VERSION "HNNBNNNYNNNNNNNNNNNNNNNNNNNNNNNNNNNNNNNNNN/4/%%%/4/'%**4NNN///"

NS_ :

BS_:

BU_: AFS_B8 Airbag_B8 Daempfer_B8 Gateway_B8 Getriebe_AL6000 Getriebe_DL5001 Getriebe_VL3002 LWR_B8 Motor_EDC17_003 Motor_EDC17_004 Motor_MED17_B8 Motor_MED9_B8 Motor_SIMOS8_B8 Motor_Slave_B8 Getriebe_AL1000 Motor_MED17_SIMOS8 Motor_EDC17 Gateway_Routing_PAG Gateway_VW EPB_D4 Motor_EDC17_D4 Motor_MED17_003 Hybrid_MSG Hybrid_DQ200 Motor_ME17_BY Motor_MED17_SIMOS8_D4 Motor_EDC17_B8 Getriebe_AL551_951_D4_C7 Getriebe_AL551_Hybrid_D4_C7 Getriebe_DL501_C7 Getriebe_VL381_C7 Motor_MED17_SIMOS8_D4_Hybrid SCU_D4 Gateway_D4C7 Motor_MED17_Q5_Hybrid Fahrwerk STH_D4 Airbag_D4 Gateway_PAG_002 Gateway_VW_T003 Gateway_D4 LEH_Hybrid SCR_C7 BMS_Hybrid Gateway_App_PAG Getriebe_AL1004 Motor_MED17_006 Getriebe_AL5000

BO_ 906 GW_Fwk_01_Ant_PAG: 8 Gateway_Routing_PAG
 SG_ KL_T_PASM_1 : 5|1@1+ (1,0) [0|1] "" Vector__XXX
 SG_ KL_T_PASM_2 : 6|1@1+ (1,0) [0|1] "" Vector__XXX
 SG_ ESP_Gierrate_Offset : 8|8@1+ (0.1,-12.6) [-12.6|12.7] "Unit_DegreOfArcPerSecon" Vector__XXX
 SG_ KL_AussenTemp_WK : 16|8@1+ (0.5,-50) [-50|76] "Unit_DegreCelsi" Vector__XXX
 SG_ GE_Getriebestatus : 24|4@1+ (1,0) [0|15] "" Vector__XXX
 SG_ FAS_Status_Anzeige : 28|3@1+ (1,0) [0|7] "" Vector__XXX
 SG_ KL_Magnetventil : 32|1@1+ (1,0) [0|1] "" Vector__XXX
 SG_ LS_Tip_Hoch : 33|1@1+ (1,0) [0|1] "" Vector__XXX
 SG_ LS_Tip_Runter : 34|1@1+ (1,0) [0|1] "" Vector__XXX
 SG_ KL_T_PSM_off : 35|1@1+ (1,0) [0|1] ""  Getriebe_AL1000
 SG_ TV_Eingriff : 36|1@1+ (1,0) [0|1] "" Vector__XXX
 SG_ FSM_Status : 37|1@1+ (1,0) [0|1] "" Vector__XXX
 SG_ KL_Niv_up : 38|1@1+ (1,0) [0|1] "" Vector__XXX
 SG_ KL_Niv_down : 39|1@1+ (1,0) [0|1] "" Vector__XXX
 SG_ ESP_Rollenmodus : 40|1@1+ (1,0) [0|1] ""  Getriebe_AL1000,Motor_MED17_SIMOS8
 SG_ KL_T_Abgasklappe : 41|1@1+ (1,0) [0|1] ""  Motor_EDC17,Motor_MED17_SIMOS8
 SG_ KL_T_HDC : 42|1@1+ (1,0) [0|1] "" Vector__XXX
 SG_ KL_T_PASM_3 : 45|1@1+ (1,0) [0|1] "" Vector__XXX
 SG_ Wischer_vorne_Schnell : 46|1@1+ (1,0) [0|1] "" Vector__XXX
 SG_ Wischer_vorne_Normal : 47|1@1+ (1,0) [0|1] "" Vector__XXX
 SG_ F_Getriebe_07_PAG_Fwk : 48|1@1+ (1,0) [0|1] "" Vector__XXX
 SG_ F_ESP_11_Ant : 49|1@1+ (1,0) [0|1] ""  Motor_MED17_SIMOS8
 SG_ F_Klima_03_Fwk_Ant : 50|1@1+ (1,0) [0|1] "" Vector__XXX
 SG_ F_Wischer_01_Fwk : 51|1@1+ (1,0) [0|1] "" Vector__XXX
 SG_ F_TSK_03_Fwk : 52|1@1+ (1,0) [0|1] "" Vector__XXX
 SG_ LS_Fehler : 53|1@1+ (1,0) [0|1] "" Vector__XXX
 SG_ F_Klima_08_PAG_Fwk : 54|1@1+ (1,0) [0|1] ""  Getriebe_AL1000,Motor_EDC17,Motor_MED17_SIMOS8
 SG_ F_ESP_13_Ant : 56|1@1+ (1,0) [0|1] "" Vector__XXX
 SG_ F_LS_01_Fwk : 57|1@1+ (1,0) [0|1] "" Vector__XXX

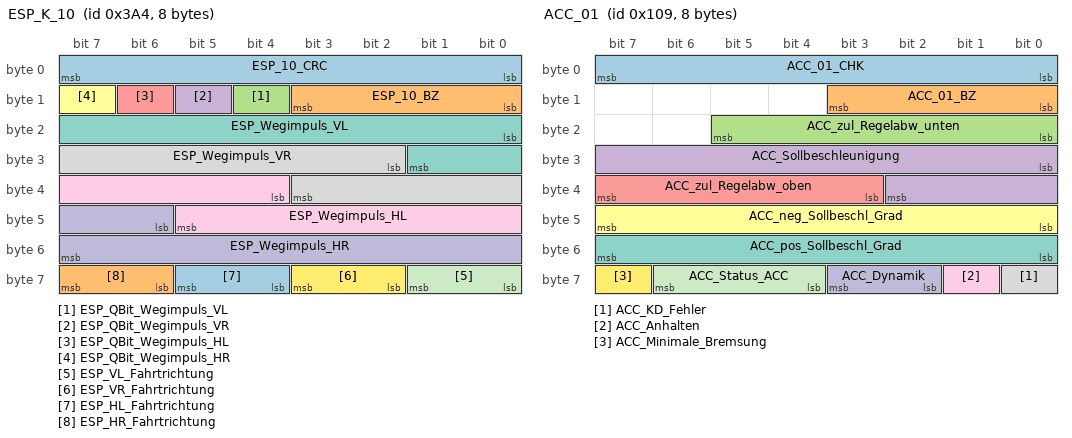
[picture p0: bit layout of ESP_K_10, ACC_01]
BO_ 932 ESP_K_10: 8 Gateway_VW
 SG_ ESP_10_CRC : 0|8@1+ (1,0) [0|255] ""  Motor_EDC17,Motor_MED17_SIMOS8
 SG_ ESP_10_BZ : 8|4@1+ (1,0) [0|15] ""  Motor_EDC17,Motor_MED17_SIMOS8
 SG_ ESP_QBit_Wegimpuls_VL : 12|1@1+ (1,0) [0|1] ""  Motor_EDC17,Motor_MED17_SIMOS8
 SG_ ESP_QBit_Wegimpuls_VR : 13|1@1+ (1,0) [0|1] ""  Motor_EDC17,Motor_MED17_SIMOS8
 SG_ ESP_QBit_Wegimpuls_HL : 14|1@1+ (1,0) [0|1] ""  Motor_EDC17,Motor_MED17_SIMOS8
 SG_ ESP_QBit_Wegimpuls_HR : 15|1@1+ (1,0) [0|1] ""  Motor_EDC17,Motor_MED17_SIMOS8
 SG_ ESP_Wegimpuls_VL : 16|10@1+ (1,0) [0|1000] ""  Motor_EDC17,Motor_MED17_SIMOS8
 SG_ ESP_Wegimpuls_VR : 26|10@1+ (1,0) [0|1000] ""  Motor_EDC17,Motor_MED17_SIMOS8
 SG_ ESP_Wegimpuls_HL : 36|10@1+ (1,0) [0|1000] ""  Motor_EDC17,Motor_MED17_SIMOS8
 SG_ ESP_Wegimpuls_HR : 46|10@1+ (1,0) [0|1000] ""  Motor_EDC17,Motor_MED17_SIMOS8
 SG_ ESP_VL_Fahrtrichtung : 56|2@1+ (1,0) [0|3] "" Vector__XXX
 SG_ ESP_VR_Fahrtrichtung : 58|2@1+ (1,0) [0|3] "" Vector__XXX
 SG_ ESP_HL_Fahrtrichtung : 60|2@1+ (1,0) [0|3] "" Vector__XXX
 SG_ ESP_HR_Fahrtrichtung : 62|2@1+ (1,0) [0|3] "" Vector__XXX

BO_ 1424 Kessy_02: 8 Gateway_B8
 SG_ KY_Funkschl_Nr : 0|4@1+ (1,0) [0|15] "" Vector__XXX
 SG_ KY_ID_Geb_autorisiert : 4|1@1+ (1,0) [0|1] "" Vector__XXX
 SG_ KY_ID_Geb_steckt : 5|1@1+ (1,0) [0|1] "" Vector__XXX
 SG_ KY_FFB_Frequenz : 6|2@1+ (1,0) [0|3] "" Vector__XXX
 SG_ KY_HF_Aktiv : 8|1@1+ (1,0) [0|1] "" Vector__XXX
 SG_ KY_LF_Aktiv : 9|1@1+ (1,0) [0|1] "" Vector__XXX
 SG_ KY_ELV_verr : 10|1@1+ (1,0) [0|1] ""  EPB_D4
 SG_ KY_ELV_entr : 11|1@1+ (1,0) [0|1] ""  EPB_D4
 SG_ KY_ELV_enable_Anforderung : 12|1@1+ (1,0) [0|1] "" Vector__XXX
 SG_ KY_Valet_Parking : 14|1@1+ (1,0) [0|1] "" Vector__XXX
 SG_ KY_Keyless_Verbau : 15|1@1+ (1,0) [0|1] "" Vector__XXX
 SG_ KY_FBS_Fahrer_Hinweise : 16|3@1+ (1,0) [0|7] "" Vector__XXX
 SG_ FBS_Warn_Lenkung_def : 19|1@1+ (1,0) [0|1] "" Vector__XXX
 SG_ FBS_Warn_LenkVerriegelung_def : 20|1@1+ (1,0) [0|1] "" Vector__XXX
 SG_ FBS_Warn_Schluessel_Batt : 21|1@1+ (1,0) [0|1] "" Vector__XXX
 SG_ FBS_Prio_Warn_04 : 22|1@1+ (1,0) [0|1] "" Vector__XXX
 SG_ FBS_Prio_Warn_05 : 23|1@1+ (1,0) [0|1] "" Vector__XXX
 SG_ KY_KYL_Fahrer_Hinweise : 24|3@1+ (1,0) [0|7] "" Vector__XXX
 SG_ KYL_Warn_kein_Schuessel : 27|1@1+ (1,0) [0|1] "" Vector__XXX
 SG_ KYL_Warn_Kessy_defekt : 28|1@1+ (1,0) [0|1] "" Vector__XXX
 SG_ KY_KYL_Prio_Warn_03 : 29|1@1+ (1,0) [0|1] "" Vector__XXX
 SG_ KY_KYL_Prio_Warn_04 : 30|1@1+ (1,0) [0|1] "" Vector__XXX
 SG_ KY_KYL_Prio_Warn_05 : 31|1@1+ (1,0) [0|1] "" Vector__XXX
 SG_ KY_Schluessel_Soll : 32|4@1+ (1,0) [0|15] "" Vector__XXX
 SG_ KY_Schluessel_Ist : 36|4@1+ (1,0) [0|15] "" Vector__XXX
 SG_ KY_WFS_Safe : 40|1@1+ (1,0) [0|1] "" Vector__XXX
 SG_ KY_WFS_LZ : 41|2@1+ (1,0) [0|3] "" Vector__XXX
 SG_ KY_StartStopp_Info : 43|2@1+ (1,0) [0|3] ""  Motor_EDC17_D4,Motor_MED17_003
 SG_ FBS_KD_Fehler : 47|1@1+ (1,0) [0|1] "" Vector__XXX

BO_ 265 ACC_01: 8 Gateway_B8
 SG_ ACC_01_CHK : 0|8@1+ (1,0) [0|255] ""  Daempfer_B8,Motor_EDC17_003,Motor_EDC17_004,Motor_MED17_B8,Motor_MED9_B8,Motor_SIMOS8_B8
 SG_ ACC_01_BZ : 8|4@1+ (1,0) [0|15] ""  Daempfer_B8,Motor_EDC17_003,Motor_EDC17_004,Motor_MED17_B8,Motor_MED9_B8,Motor_SIMOS8_B8
 SG_ ACC_zul_Regelabw_unten : 16|6@1+ (0.024,0) [0|1.512] "m/s2"  Motor_EDC17_003,Motor_EDC17_004,Motor_MED17_B8,Motor_MED9_B8,Motor_SIMOS8_B8
 SG_ ACC_Sollbeschleunigung : 24|11@1+ (0.005,-7.22) [-7.22|3.01] "m/s2"  Daempfer_B8,Motor_EDC17_003,Motor_EDC17_004,Motor_MED17_B8,Motor_MED9_B8,Motor_SIMOS8_B8
 SG_ ACC_zul_Regelabw_oben : 35|5@1+ (0.0625,0) [0|1.9375] "m/s2"  Motor_EDC17_003,Motor_EDC17_004,Motor_MED17_B8,Motor_MED9_B8,Motor_SIMOS8_B8
 SG_ ACC_neg_Sollbeschl_Grad : 40|8@1+ (0.05,0) [0|12.7] "m/s³"  Motor_EDC17_003,Motor_EDC17_004,Motor_MED17_B8,Motor_MED9_B8,Motor_SIMOS8_B8
 SG_ ACC_pos_Sollbeschl_Grad : 48|8@1+ (0.05,0) [0|12.7] "m/s³"  Motor_EDC17_003,Motor_EDC17_004,Motor_MED17_B8,Motor_MED9_B8,Motor_SIMOS8_B8
 SG_ ACC_KD_Fehler : 56|1@1+ (1,0) [0|1] "" Vector__XXX
 SG_ ACC_Anhalten : 57|1@1+ (1,0) [0|1] ""  Motor_EDC17_003,Motor_EDC17_004,Motor_MED17_B8,Motor_MED9_B8,Motor_SIMOS8_B8
 SG_ ACC_Dynamik : 58|2@1+ (1,0) [0|3] ""  Motor_EDC17_003,Motor_EDC17_004,Motor_MED17_B8,Motor_MED9_B8,Motor_SIMOS8_B8
 SG_ ACC_Status_ACC : 60|3@1+ (1,0) [0|7] ""  Daempfer_B8,Motor_EDC17_003,Motor_EDC17_004,Motor_MED17_B8,Motor_MED9_B8,Motor_SIMOS8_B8
 SG_ ACC_Minimale_Bremsung : 63|1@1+ (1,0) [0|1] ""  Motor_EDC17_003,Motor_EDC17_004,Motor_MED17_B8,Motor_MED9_B8,Motor_SIMOS8_B8

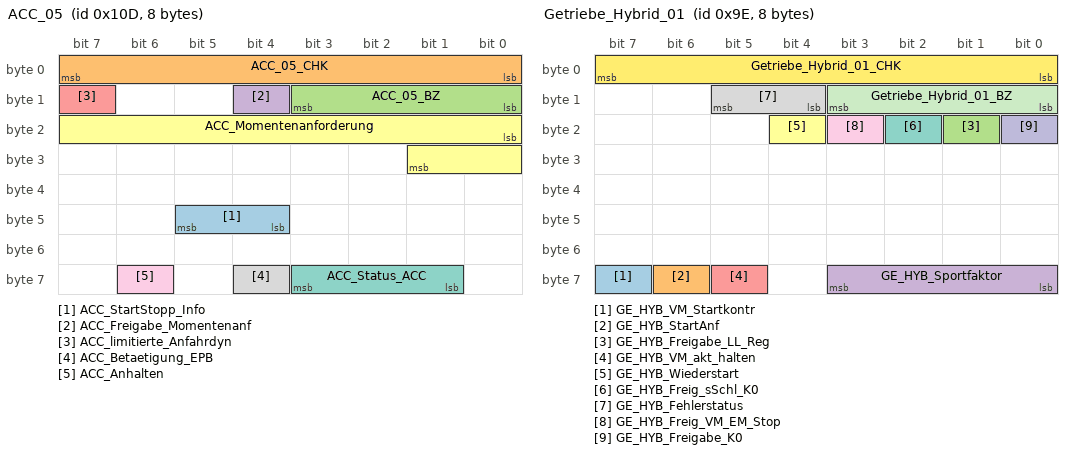
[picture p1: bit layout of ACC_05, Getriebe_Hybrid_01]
BO_ 269 ACC_05: 8 Gateway_B8
 SG_ ACC_StartStopp_Info : 44|2@1+ (1,0) [0|0] "" Vector__XXX
 SG_ ACC_05_CHK : 0|8@1+ (1,0) [0|255] ""  Daempfer_B8,Motor_EDC17_003,Motor_EDC17_004,Motor_MED17_B8,Motor_MED9_B8,Motor_SIMOS8_B8
 SG_ ACC_05_BZ : 8|4@1+ (1,0) [0|15] ""  Daempfer_B8,Motor_EDC17_003,Motor_EDC17_004,Motor_MED17_B8,Motor_MED9_B8,Motor_SIMOS8_B8
 SG_ ACC_Freigabe_Momentenanf : 12|1@1+ (1,0) [0|1] ""  Motor_EDC17_003,Motor_EDC17_004,Motor_MED17_B8,Motor_MED9_B8,Motor_SIMOS8_B8
 SG_ ACC_limitierte_Anfahrdyn : 15|1@1+ (1,0) [0|1] ""  Daempfer_B8,Motor_EDC17_003,Motor_EDC17_004,Motor_MED17_B8,Motor_MED9_B8,Motor_SIMOS8_B8
 SG_ ACC_Momentenanforderung : 16|10@1+ (1,0) [0|1021] ""  Motor_EDC17_003,Motor_EDC17_004,Motor_MED17_B8,Motor_MED9_B8,Motor_SIMOS8_B8
 SG_ ACC_Status_ACC : 57|3@1+ (1,0) [0|7] ""  Motor_EDC17_003,Motor_EDC17_004,Motor_MED17_B8,Motor_MED9_B8,Motor_SIMOS8_B8
 SG_ ACC_Betaetigung_EPB : 60|1@1+ (1,0) [0|1] ""  Motor_EDC17_003,Motor_EDC17_004,Motor_MED17_B8,Motor_MED9_B8,Motor_SIMOS8_B8
 SG_ ACC_Anhalten : 62|1@1+ (1,0) [0|1] ""  Motor_EDC17_003,Motor_EDC17_004,Motor_MED17_B8,Motor_MED9_B8,Motor_SIMOS8_B8

BO_ 158 Getriebe_Hybrid_01: 8 Hybrid_DQ200
 SG_ GE_HYB_VM_Startkontr : 63|1@1+ (1,0) [0|1] ""  Hybrid_MSG
 SG_ GE_HYB_StartAnf : 62|1@1+ (1,0) [0|1] ""  Hybrid_MSG
 SG_ GE_HYB_Freigabe_LL_Reg : 17|1@1+ (1,0) [0|1] ""  Hybrid_MSG
 SG_ GE_HYB_Sportfaktor : 56|4@1+ (1,0) [0|15] ""  Hybrid_MSG
 SG_ GE_HYB_VM_akt_halten : 61|1@1+ (1,0) [0|1] ""  Hybrid_MSG
 SG_ GE_HYB_Wiederstart : 20|1@1+ (1,0) [0|1] ""  Hybrid_MSG
 SG_ GE_HYB_Freig_sSchl_K0 : 18|1@1+ (1,0) [0|1] ""  Hybrid_MSG
 SG_ GE_HYB_Fehlerstatus : 12|2@1+ (1,0) [0|3] ""  Hybrid_MSG
 SG_ GE_HYB_Freig_VM_EM_Stop : 19|1@1+ (1,0) [0|1] ""  Hybrid_MSG
 SG_ GE_HYB_Freigabe_K0 : 16|1@1+ (1,0) [0|1] ""  Hybrid_MSG
 SG_ Getriebe_Hybrid_01_BZ : 8|4@1+ (1,0) [0|15] ""  Hybrid_MSG
 SG_ Getriebe_Hybrid_01_CHK : 0|8@1+ (1,0) [0|255] ""  Hybrid_MSG

BO_ 255 NOX2: 8 Vector__XXX
 SG_ NOx_Fehlerstatus_Bit7_1 : 63|1@1+ (1,0) [0|1] "" Vector__XXX
 SG_ NOx_Fehlerstatus_Bit6_1 : 62|1@1+ (1,0) [0|1] "" Vector__XXX
 SG_ NOx_Fehlerstatus_Bit5_1 : 61|1@1+ (1,0) [0|1] "" Vector__XXX
 SG_ NOx_Fehlerstatus_Bit4_1 : 60|1@1+ (1,0) [0|1] "" Vector__XXX
 SG_ NOx_Fehlerstatus_Bit3_1 : 59|1@1+ (1,0) [0|1] "" Vector__XXX
 SG_ NOx_Fehlerstatus_Bit2_1 : 58|1@1+ (1,0) [0|1] "" Vector__XXX
 SG_ NOx_Fehlerstatus_Bit1_1 : 57|1@1+ (1,0) [0|1] "" Vector__XXX
 SG_ NOx_Fehlerstatus_Bit0_1 : 56|1@1+ (1,0) [0|1] "" Vector__XXX
 SG_ NOx_Ubat_1 : 56|8@1+ (160,0) [0|40800] "mV" Vector__XXX
 SG_ NOx_MuxInfo_Korrekturfakt_OBD_1 : 56|8@1+ (1,0) [0|255] "" Vector__XXX
 SG_ NOx_MultiplexCode_Daten_1 : 55|1@1+ (1,0) [0|1] "" Vector__XXX
 SG_ NOx_MultiplexCode_OBD_1 : 53|2@1+ (1,0) [0|1] "" Vector__XXX
 SG_ NOx_Qbit_NOx_1 : 52|1@1+ (1,0) [0|1] "" Vector__XXX
 SG_ NOx_QBit_Rezp_Lambda_1 : 51|1@1+ (1,0) [0|1] "" Vector__XXX
 SG_ NOx_QBit_Lamb_U_1 : 50|1@1+ (1,0) [0|1] "" Vector__XXX
 SG_ NOx_QBit_Heizer_1 : 49|1@1+ (1,0) [0|1] "" Vector__XXX
 SG_ NOx_TaupunktEmpfang_1 : 48|1@1+ (1,0) [0|1] "" Vector__XXX
 SG_ NOx_MuxInfo_SensorStatus_1 : 48|8@1+ (1,0) [0|255] "" Vector__XXX
 SG_ NOx_MuxInfo_Lamb_U_4 : 40|8@1+ (1,0) [0|255] "" Vector__XXX
 SG_ NOx_MuxInfo_Lamb_U_3 : 40|8@1- (1,0) [-127|127] "" Vector__XXX
 SG_ NOx_MuxInfo_Lamb_U_2 : 32|8@1- (1,0) [-127|127] "" Vector__XXX
 SG_ NOx_MuxInfo_Lamb_U_1 : 32|16@1- (1,0) [-32768|32767] "mV" Vector__XXX
 SG_ NOx_MuxInfo_RezpLambda_Wert_3 : 16|16@1+ (1,0) [0|2000] "" Vector__XXX
 SG_ NOx_MuxInfo_RezpLambda_Wert_2 : 16|16@1+ (1,0) [0|8000] "" Vector__XXX
 SG_ NOx_MuxInfo_RezpLambda_Wert_1 : 16|16@1- (0.001,0) [-32.768|32.767] "" Vector__XXX
 SG_ NOx_MuxInfo_NOx_Wert_3 : 0|16@1+ (1,0) [0|2000] "-" Vector__XXX
 SG_ NOx_MuxInfo_NOx_Wert_2 : 0|16@1+ (1,0) [0|2000] "-" Vector__XXX
 SG_ NOx_MuxInfo_NOx_Wert_1 : 0|16@1- (0.1,0) [-3276.8|3276.7] "ppm" Vector__XXX

BO_ 254 NOX1: 8 Vector__XXX
 SG_ NOx_Fehlerstatus_Bit7_1 : 63|1@1+ (1,0) [0|1] "" Vector__XXX
 SG_ NOx_Fehlerstatus_Bit6_1 : 62|1@1+ (1,0) [0|1] "" Vector__XXX
 SG_ NOx_Fehlerstatus_Bit5_1 : 61|1@1+ (1,0) [0|1] "" Vector__XXX
 SG_ NOx_Fehlerstatus_Bit4_1 : 60|1@1+ (1,0) [0|1] "" Vector__XXX
 SG_ NOx_Fehlerstatus_Bit3_1 : 59|1@1+ (1,0) [0|1] "" Vector__XXX
 SG_ NOx_Fehlerstatus_Bit2_1 : 58|1@1+ (1,0) [0|1] "" Vector__XXX
 SG_ NOx_Fehlerstatus_Bit1_1 : 57|1@1+ (1,0) [0|1] "" Vector__XXX
 SG_ NOx_Fehlerstatus_Bit0_1 : 56|1@1+ (1,0) [0|1] "" Vector__XXX
 SG_ NOx_Ubat_1 : 56|8@1+ (160,0) [0|40800] "mV" Vector__XXX
 SG_ NOx_MuxInfo_Korrekturfakt_OBD_1 : 56|8@1+ (1,0) [0|255] "" Vector__XXX
 SG_ NOx_MultiplexCode_Daten_1 : 55|1@1+ (1,0) [0|1] "" Vector__XXX
 SG_ NOx_MultiplexCode_OBD_1 : 53|2@1+ (1,0) [0|1] "" Vector__XXX
 SG_ NOx_Qbit_NOx_1 : 52|1@1+ (1,0) [0|1] "" Vector__XXX
 SG_ NOx_QBit_Rezp_Lambda_1 : 51|1@1+ (1,0) [0|1] "" Vector__XXX
 SG_ NOx_QBit_Lamb_U_1 : 50|1@1+ (1,0) [0|1] "" Vector__XXX
 SG_ NOx_QBit_Heizer_1 : 49|1@1+ (1,0) [0|1] "" Vector__XXX
 SG_ NOx_TaupunktEmpfang_1 : 48|1@1+ (1,0) [0|1] "" Vector__XXX
 SG_ NOx_MuxInfo_SensorStatus_1 : 48|8@1+ (1,0) [0|255] "" Vector__XXX
 SG_ NOx_MuxInfo_Lamb_U_4 : 40|8@1+ (1,0) [0|255] "" Vector__XXX
 SG_ NOx_MuxInfo_Lamb_U_3 : 40|8@1- (1,0) [-127|127] "" Vector__XXX
 SG_ NOx_MuxInfo_Lamb_U_2 : 32|8@1- (1,0) [-127|127] "" Vector__XXX
 SG_ NOx_MuxInfo_Lamb_U_1 : 32|16@1- (1,0) [-32768|32767] "mV" Vector__XXX
 SG_ NOx_MuxInfo_RezpLambda_Wert_3 : 16|16@1+ (1,0) [0|2000] "" Vector__XXX
 SG_ NOx_MuxInfo_RezpLambda_Wert_2 : 16|16@1+ (1,0) [0|8000] "" Vector__XXX
 SG_ NOx_MuxInfo_RezpLambda_Wert_1 : 16|16@1- (0.001,0) [-32.768|32.767] "" Vector__XXX
 SG_ NOx_MuxInfo_NOx_Wert_3 : 0|16@1+ (1,0) [0|2000] "-" Vector__XXX
 SG_ NOx_MuxInfo_NOx_Wert_2 : 0|16@1+ (1,0) [0|2000] "-" Vector__XXX
 SG_ NOx_MuxInfo_NOx_Wert_1 : 0|16@1- (0.1,0) [-3276.8|3276.7] "ppm" Vector__XXX

BO_ 64 Airbag_01: 8 Airbag_B8
 SG_ Airbag_01_CHK : 0|8@1+ (1,0) [0|255] ""  Gateway_B8,Motor_EDC17_003,Motor_EDC17_004,Motor_MED17_B8,Motor_MED9_B8,Motor_SIMOS8_B8
 SG_ Airbag_01_BZ : 8|4@1+ (1,0) [0|15] ""  Gateway_B8,Motor_EDC17_003,Motor_EDC17_004,Motor_MED17_B8,Motor_MED9_B8,Motor_SIMOS8_B8
 SG_ AB_Front_Crash : 16|1@1+ (1,0) [0|1] ""  Gateway_B8
 SG_ AB_Heck_Crash : 17|1@1+ (1,0) [0|1] ""  Gateway_B8
 SG_ AB_SF_Crash : 18|1@1+ (1,0) [0|1] ""  Gateway_B8
 SG_ AB_SB_Crash : 19|1@1+ (1,0) [0|1] ""  Gateway_B8
 SG_ AB_Rollover_Crash : 20|1@1+ (1,0) [0|1] ""  Gateway_B8
 SG_ AB_Crash_Int : 21|3@1+ (1,0) [0|7] ""  Gateway_B8,Motor_EDC17_003,Motor_EDC17_004,Motor_MED17_B8,Motor_MED9_B8,Motor_SIMOS8_B8
 SG_ AB_Lampe : 24|1@1+ (1,0) [0|1] ""  Gateway_B8
 SG_ AB_Deaktiviert : 25|1@1+ (1,0) [0|1] ""  Gateway_B8
 SG_ AB_VB_deaktiviert : 26|1@1+ (1,0) [0|1] ""  Gateway_B8
 SG_ AB_Systemfehler : 27|1@1+ (1,0) [0|1] ""  Gateway_B8
 SG_ AB_Diagnose : 28|1@1+ (1,0) [0|1] ""  Gateway_B8
 SG_ AB_Stellgliedtest : 29|1@1+ (1,0) [0|1] ""  Gateway_B8,Motor_EDC17_003,Motor_EDC17_004,Motor_MED17_B8,Motor_MED9_B8,Motor_SIMOS8_B8
 SG_ AB_Erh_Auf_VB : 30|2@1+ (1,0) [0|3] ""  Gateway_B8
 SG_ AB_Gurtwarn_VF : 32|1@1+ (1,0) [0|1] ""  Gateway_B8
 SG_ AB_Gurtwarn_VB : 33|1@1+ (1,0) [0|1] ""  Gateway_B8
 SG_ AB_Anzeige_Fussg : 34|2@1+ (1,0) [0|3] ""  Gateway_B8
 SG_ AB_Deaktivierung_HV : 42|3@1+ (1,0) [0|7] ""  Gateway_B8
 SG_ void_Byte_02 : 48|8@1+ (1,0) [0|255] ""  Gateway_B8
 SG_ void_Byte_03 : 56|7@1+ (1,0) [0|127] ""  Gateway_B8
 SG_ AB_KD_Fehler : 63|1@1+ (1,0) [0|1] ""  Gateway_B8

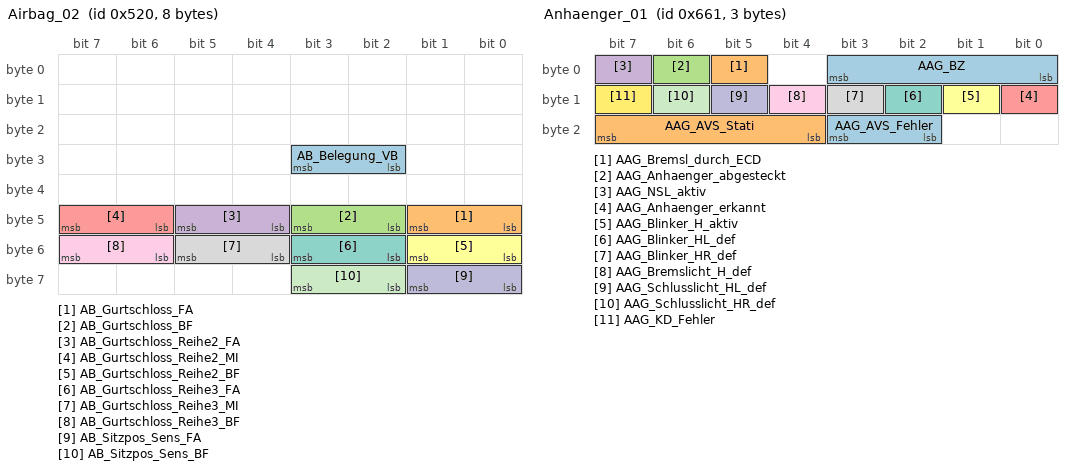
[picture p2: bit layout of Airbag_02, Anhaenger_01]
BO_ 1312 Airbag_02: 8 Airbag_B8
 SG_ AB_Belegung_VB : 26|2@1+ (1,0) [0|3] ""  Gateway_B8
 SG_ AB_Gurtschloss_FA : 40|2@1+ (1,0) [0|3] ""  Gateway_B8,Motor_EDC17_D4,Motor_MED17_003
 SG_ AB_Gurtschloss_BF : 42|2@1+ (1,0) [0|3] ""  Gateway_B8
 SG_ AB_Gurtschloss_Reihe2_FA : 44|2@1+ (1,0) [0|3] ""  Gateway_B8
 SG_ AB_Gurtschloss_Reihe2_MI : 46|2@1+ (1,0) [0|3] ""  Gateway_B8
 SG_ AB_Gurtschloss_Reihe2_BF : 48|2@1+ (1,0) [0|3] ""  Gateway_B8
 SG_ AB_Gurtschloss_Reihe3_FA : 50|2@1+ (1,0) [0|3] ""  Gateway_B8
 SG_ AB_Gurtschloss_Reihe3_MI : 52|2@1+ (1,0) [0|3] ""  Gateway_B8
 SG_ AB_Gurtschloss_Reihe3_BF : 54|2@1+ (1,0) [0|3] ""  Gateway_B8
 SG_ AB_Sitzpos_Sens_FA : 56|2@1+ (1,0) [0|3] ""  Gateway_B8
 SG_ AB_Sitzpos_Sens_BF : 58|2@1+ (1,0) [0|3] ""  Gateway_B8

BO_ 1633 Anhaenger_01: 3 Gateway_B8
 SG_ AAG_BZ : 0|4@1+ (1,0) [0|15] ""  Getriebe_AL6000,Motor_EDC17_003,Motor_EDC17_004,Motor_MED17_B8,Motor_MED9_B8,Motor_SIMOS8_B8
 SG_ AAG_Bremsl_durch_ECD : 5|1@1+ (1,0) [0|1] ""  Motor_EDC17_003,Motor_EDC17_004,Motor_MED17_B8,Motor_MED9_B8,Motor_SIMOS8_B8
 SG_ AAG_Anhaenger_abgesteckt : 6|1@1+ (1,0) [0|1] "" Vector__XXX
 SG_ AAG_NSL_aktiv : 7|1@1+ (1,0) [0|1] "" Vector__XXX
 SG_ AAG_Anhaenger_erkannt : 8|1@1+ (1,0) [0|1] ""  Getriebe_AL6000,Getriebe_DL5001,Getriebe_VL3002,Motor_EDC17_003,Motor_EDC17_004,Motor_MED17_B8,Motor_MED9_B8,Motor_SIMOS8_B8
 SG_ AAG_Blinker_H_aktiv : 9|1@1+ (1,0) [0|1] "" Vector__XXX
 SG_ AAG_Blinker_HL_def : 10|1@1+ (1,0) [0|1] "" Vector__XXX
 SG_ AAG_Blinker_HR_def : 11|1@1+ (1,0) [0|1] "" Vector__XXX
 SG_ AAG_Bremslicht_H_def : 12|1@1+ (1,0) [0|1] ""  Motor_EDC17_003,Motor_EDC17_004,Motor_MED17_B8,Motor_MED9_B8,Motor_SIMOS8_B8
 SG_ AAG_Schlusslicht_HL_def : 13|1@1+ (1,0) [0|1] "" Vector__XXX
 SG_ AAG_Schlusslicht_HR_def : 14|1@1+ (1,0) [0|1] "" Vector__XXX
 SG_ AAG_KD_Fehler : 15|1@1+ (1,0) [0|1] "" Vector__XXX
 SG_ AAG_AVS_Fehler : 18|2@1+ (1,0) [0|3] "" Vector__XXX
 SG_ AAG_AVS_Stati : 20|4@1+ (1,0) [0|15] "" Vector__XXX

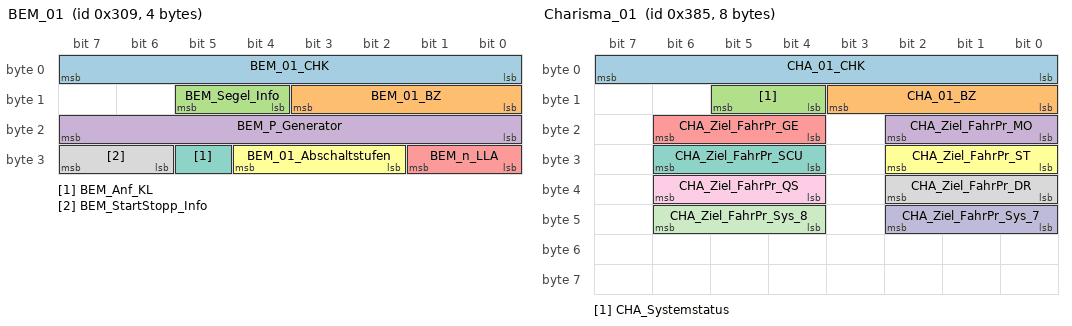
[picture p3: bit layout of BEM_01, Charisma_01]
BO_ 777 BEM_01: 4 Gateway_B8
 SG_ BEM_01_CHK : 0|8@1+ (1,0) [0|255] ""  Motor_EDC17_D4,Motor_ME17_BY,Motor_MED17_SIMOS8_D4
 SG_ BEM_01_BZ : 8|4@1+ (1,0) [0|15] ""  Motor_EDC17_D4,Motor_ME17_BY,Motor_MED17_SIMOS8_D4
 SG_ BEM_Segel_Info : 12|2@1+ (1,0) [0|3] "" Vector__XXX
 SG_ BEM_P_Generator : 16|8@1+ (50,0) [0|12700] "Unit_Watt"  Motor_EDC17_D4,Motor_ME17_BY,Motor_MED17_SIMOS8_D4
 SG_ BEM_n_LLA : 24|2@1+ (1,0) [0|3] ""  Motor_EDC17_D4,Motor_ME17_BY,Motor_MED17_SIMOS8_D4
 SG_ BEM_01_Abschaltstufen : 26|3@1+ (1,0) [0|7] "" Vector__XXX
 SG_ BEM_Anf_KL : 29|1@1+ (1,0) [0|1] ""  Motor_EDC17_D4,Motor_ME17_BY,Motor_MED17_SIMOS8_D4
 SG_ BEM_StartStopp_Info : 30|2@1+ (1,0) [0|3] ""  Motor_EDC17_D4,Motor_ME17_BY,Motor_MED17_SIMOS8_D4

BO_ 867 Blinkmodi_01: 4 Gateway_B8
 SG_ BM_ZV_auf : 0|1@1+ (1,0) [0|1] "" Vector__XXX
 SG_ BM_ZV_zu : 1|1@1+ (1,0) [0|1] "" Vector__XXX
 SG_ BM_DWA_ein : 2|1@1+ (1,0) [0|1] "" Vector__XXX
 SG_ BM_DWA_Alarm : 3|1@1+ (1,0) [0|1] "" Vector__XXX
 SG_ BM_Crash : 4|1@1+ (1,0) [0|1] "" Vector__XXX
 SG_ BM_Panik : 5|1@1+ (1,0) [0|1] "" Vector__XXX
 SG_ BM_Not_Bremsung : 6|1@1+ (1,0) [0|1] "" Vector__XXX
 SG_ BM_GDO : 7|1@1+ (1,0) [0|1] "" Vector__XXX
 SG_ BM_links : 8|1@1+ (1,0) [0|1] "" Vector__XXX
 SG_ BM_rechts : 9|1@1+ (1,0) [0|1] "" Vector__XXX
 SG_ BM_Warnblinken : 10|1@1+ (1,0) [0|1] "" Vector__XXX
 SG_ BM_Autobahn : 11|1@1+ (1,0) [0|1] ""  AFS_B8
 SG_ BM_Taxi_Notalarm : 12|1@1+ (1,0) [0|1] "" Vector__XXX
 SG_ BM_Telematik : 13|1@1+ (1,0) [0|1] "" Vector__XXX
 SG_ BM_WBT_Beleuchtung : 15|1@1+ (1,0) [0|1] "" Vector__XXX
 SG_ Blinken_li_Fzg_Takt : 16|1@1+ (1,0) [0|1] "" Vector__XXX
 SG_ Blinken_re_Fzg_Takt : 17|1@1+ (1,0) [0|1] "" Vector__XXX
 SG_ Blinken_li_Kombi_Takt : 18|1@1+ (1,0) [0|1] "" Vector__XXX
 SG_ Blinken_re_Kombi_Takt : 19|1@1+ (1,0) [0|1] "" Vector__XXX
 SG_ Blinken_FWB_aktiv : 23|1@1+ (1,0) [0|1] "" Vector__XXX

BO_ 482 CCP_GE_CR0_01: 8 Gateway_B8
 SG_ CCP_GE_CRO_01_Data : 0|64@1+ (1,0) [0|1] ""  Getriebe_AL6000,Getriebe_DL5001,Getriebe_VL3002

BO_ 490 CCP_GE_DTO_01: 8 Getriebe_AL6000
 SG_ CCP_GE_DTO_01_Data : 0|64@1+ (1,0) [0|1] "" Vector__XXX

BO_ 480 CCP_MO_CRO_01: 8 Gateway_B8
 SG_ CCP_MO_CRO_01_Data : 0|64@1+ (1,0) [0|1] ""  Motor_EDC17_003,Motor_EDC17_004,Motor_MED17_B8,Motor_MED9_B8,Motor_SIMOS8_B8

BO_ 2616986624 CCP_MO_CRO_02: 8 Vector__XXX
 SG_ CCP_MO_CRO_02_Data : 0|64@1+ (1,0) [0|1] ""  Motor_EDC17_003,Motor_EDC17_004,Motor_MED17_B8,Motor_MED9_B8,Motor_SIMOS8_B8

BO_ 488 CCP_MO_DTO_01: 8 Motor_EDC17_003
 SG_ CCP_MO_DTO_01_Data : 0|64@1+ (1,0) [0|1] "" Vector__XXX

BO_ 2616986625 CCP_MO_DTO_02: 8 Motor_SIMOS8_B8
 SG_ CCP_MO_DTO_02_Data : 0|64@1+ (1,0) [0|1] "" Vector__XXX

BO_ 481 CCP_MOS_CRO_01: 8 Gateway_B8
 SG_ CCP_MOS_CRO_01_Data : 0|64@1+ (1,0) [0|1] ""  Motor_Slave_B8

BO_ 2616986629 CCP_MOS_CRO_02: 8 Vector__XXX
 SG_ CCP_MOS_CRO_02_Data : 0|64@1+ (1,0) [0|1] ""  Motor_Slave_B8

BO_ 489 CCP_MOS_DTO_01: 8 Motor_Slave_B8
 SG_ CCP_MOS_DTO_01_Data : 0|64@1+ (1,0) [0|1] "" Vector__XXX

BO_ 2616986630 CCP_MOS_DTO_02: 8 Motor_Slave_B8
 SG_ CCP_MOS_DTO_02_Data : 0|64@1+ (1,0) [0|1] "" Vector__XXX

BO_ 901 Charisma_01: 8 Gateway_B8
 SG_ CHA_01_CHK : 0|8@1+ (1,0) [0|255] ""  Daempfer_B8,Getriebe_AL6000,Getriebe_DL5001,Getriebe_VL3002,Motor_EDC17_003,Motor_EDC17_004,Motor_MED17_B8,Motor_MED9_B8,Motor_SIMOS8_B8
 SG_ CHA_01_BZ : 8|4@1+ (1,0) [0|15] "" Vector__XXX
 SG_ CHA_Systemstatus : 12|2@1+ (1,0) [0|3] ""  Daempfer_B8,Getriebe_AL6000,Getriebe_DL5001,Getriebe_VL3002,Motor_EDC17_003,Motor_EDC17_004,Motor_MED17_B8,Motor_MED9_B8,Motor_SIMOS8_B8
 SG_ CHA_Ziel_FahrPr_MO : 16|3@1+ (1,0) [0|7] ""  Motor_EDC17_003,Motor_EDC17_004,Motor_MED17_B8,Motor_MED9_B8,Motor_SIMOS8_B8
 SG_ CHA_Ziel_FahrPr_GE : 20|3@1+ (1,0) [0|7] ""  Getriebe_AL6000,Getriebe_DL5001,Getriebe_VL3002
 SG_ CHA_Ziel_FahrPr_ST : 24|3@1+ (1,0) [0|7] "" Vector__XXX
 SG_ CHA_Ziel_FahrPr_SCU : 28|3@1+ (1,0) [0|7] "" Vector__XXX
 SG_ CHA_Ziel_FahrPr_DR : 32|3@1+ (1,0) [0|7] ""  Daempfer_B8
 SG_ CHA_Ziel_FahrPr_QS : 36|3@1+ (1,0) [0|7] "" Vector__XXX
 SG_ CHA_Ziel_FahrPr_Sys_7 : 40|3@1+ (1,0) [0|7] "" Vector__XXX
 SG_ CHA_Ziel_FahrPr_Sys_8 : 44|3@1+ (1,0) [0|7] "" Vector__XXX

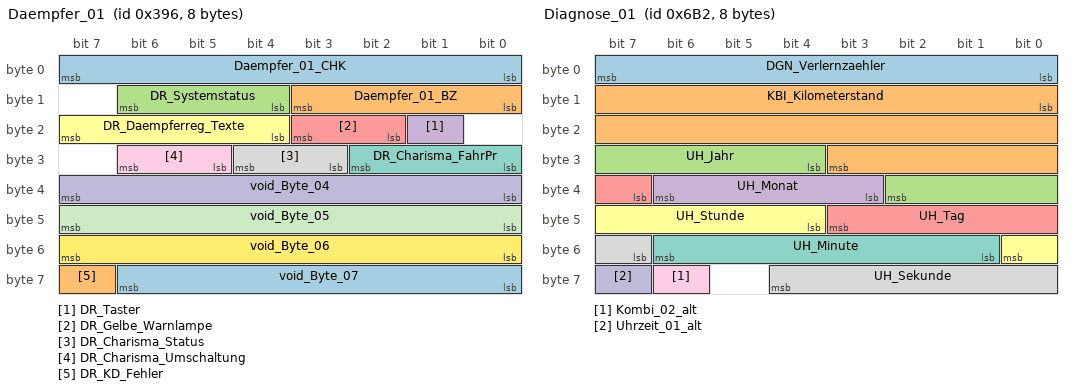
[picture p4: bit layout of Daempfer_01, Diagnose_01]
BO_ 918 Daempfer_01: 8 Daempfer_B8
 SG_ Daempfer_01_CHK : 0|8@1+ (1,0) [0|255] ""  Gateway_B8
 SG_ Daempfer_01_BZ : 8|4@1+ (1,0) [0|15] ""  Gateway_B8
 SG_ DR_Systemstatus : 12|3@1+ (1,0) [0|7] ""  Gateway_B8
 SG_ DR_Taster : 17|1@1+ (1,0) [0|1] ""  Gateway_B8
 SG_ DR_Gelbe_Warnlampe : 18|2@1+ (1,0) [0|3] ""  Gateway_B8
 SG_ DR_Daempferreg_Texte : 20|4@1+ (1,0) [0|15] ""  Gateway_B8
 SG_ DR_Charisma_FahrPr : 24|3@1+ (1,0) [0|7] ""  Gateway_B8
 SG_ DR_Charisma_Status : 27|2@1+ (1,0) [0|3] ""  Gateway_B8
 SG_ DR_Charisma_Umschaltung : 29|2@1+ (1,0) [0|3] ""  Gateway_B8
 SG_ void_Byte_04 : 32|8@1+ (1,0) [0|255] ""  Gateway_B8
 SG_ void_Byte_05 : 40|8@1+ (1,0) [0|255] ""  Gateway_B8
 SG_ void_Byte_06 : 48|8@1+ (1,0) [0|255] ""  Gateway_B8
 SG_ void_Byte_07 : 56|7@1+ (1,0) [0|127] ""  Gateway_B8
 SG_ DR_KD_Fehler : 63|1@1+ (1,0) [0|1] ""  Gateway_B8

BO_ 1714 Diagnose_01: 8 Gateway_B8
 SG_ DGN_Verlernzaehler : 0|8@1+ (1,0) [0|254] ""  AFS_B8,Airbag_B8,Daempfer_B8,LWR_B8
 SG_ KBI_Kilometerstand : 8|20@1+ (1,0) [0|1048573] "km"  AFS_B8,Airbag_B8,Daempfer_B8,Getriebe_AL6000,Getriebe_DL5001,Getriebe_VL3002,LWR_B8,Motor_EDC17_003,Motor_EDC17_004,Motor_MED17_B8,Motor_MED9_B8,Motor_SIMOS8_B8
 SG_ UH_Jahr : 28|7@1+ (1,2000) [2000|2127] ""  AFS_B8,Airbag_B8,Daempfer_B8,Getriebe_AL6000,Getriebe_DL5001,Getriebe_VL3002,LWR_B8,Motor_EDC17_003,Motor_EDC17_004,Motor_MED17_B8,Motor_MED9_B8,Motor_SIMOS8_B8
 SG_ UH_Monat : 35|4@1+ (1,0) [1|12] "month"  AFS_B8,Airbag_B8,Daempfer_B8,Getriebe_AL6000,Getriebe_DL5001,Getriebe_VL3002,LWR_B8,Motor_EDC17_003,Motor_EDC17_004,Motor_MED17_B8,Motor_MED9_B8,Motor_SIMOS8_B8
 SG_ UH_Tag : 39|5@1+ (1,0) [1|31] "d"  AFS_B8,Airbag_B8,Daempfer_B8,Getriebe_AL6000,Getriebe_DL5001,Getriebe_VL3002,LWR_B8,Motor_EDC17_003,Motor_EDC17_004,Motor_MED17_B8,Motor_MED9_B8,Motor_SIMOS8_B8
 SG_ UH_Stunde : 44|5@1+ (1,0) [0|23] "h"  AFS_B8,Airbag_B8,Daempfer_B8,Getriebe_AL6000,Getriebe_DL5001,Getriebe_VL3002,LWR_B8,Motor_EDC17_003,Motor_EDC17_004,Motor_MED17_B8,Motor_MED9_B8,Motor_SIMOS8_B8
 SG_ UH_Minute : 49|6@1+ (1,0) [0|59] "min"  AFS_B8,Airbag_B8,Daempfer_B8,Getriebe_AL6000,Getriebe_DL5001,Getriebe_VL3002,LWR_B8,Motor_EDC17_003,Motor_EDC17_004,Motor_MED17_B8,Motor_MED9_B8,Motor_SIMOS8_B8
 SG_ UH_Sekunde : 55|6@1+ (1,0) [0|59] "s"  AFS_B8,Airbag_B8,Daempfer_B8,Getriebe_AL6000,Getriebe_DL5001,Getriebe_VL3002,LWR_B8,Motor_EDC17_003,Motor_EDC17_004,Motor_MED17_B8,Motor_MED9_B8,Motor_SIMOS8_B8
 SG_ Kombi_02_alt : 62|1@1+ (1,0) [0|1] ""  AFS_B8,Airbag_B8,Getriebe_AL6000,Getriebe_DL5001,Getriebe_VL3002,LWR_B8,Motor_EDC17_003,Motor_EDC17_004,Motor_MED17_B8,Motor_MED9_B8,Motor_SIMOS8_B8
 SG_ Uhrzeit_01_alt : 63|1@1+ (1,0) [0|1] ""  AFS_B8,Airbag_B8,Getriebe_AL6000,Getriebe_DL5001,Getriebe_VL3002,LWR_B8,Motor_EDC17_003,Motor_EDC17_004,Motor_MED17_B8,Motor_MED9_B8,Motor_SIMOS8_B8

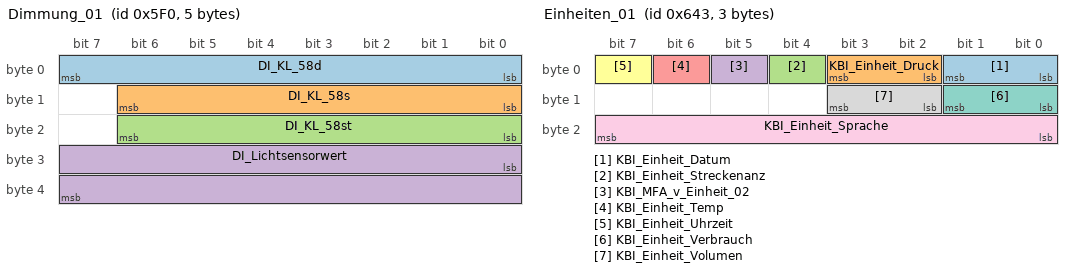
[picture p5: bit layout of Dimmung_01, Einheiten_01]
BO_ 1520 Dimmung_01: 5 Gateway_B8
 SG_ DI_KL_58d : 0|8@1+ (1,0) [0|253] ""  Airbag_B8
 SG_ DI_KL_58s : 8|7@1+ (1,0) [0|100] "%" Vector__XXX
 SG_ DI_KL_58st : 16|7@1+ (1,0) [0|100] "%" Vector__XXX
 SG_ DI_Lichtsensorwert : 24|16@1+ (1,0) [0|65535] "" Vector__XXX

BO_ 1603 Einheiten_01: 3 Gateway_B8
 SG_ KBI_Einheit_Datum : 0|2@1+ (1,0) [0|3] "" Vector__XXX
 SG_ KBI_Einheit_Druck : 2|2@1+ (1,0) [0|3] "" Vector__XXX
 SG_ KBI_Einheit_Streckenanz : 4|1@1+ (1,0) [0|1] ""  Motor_EDC17_B8
 SG_ KBI_MFA_v_Einheit_02 : 5|1@1+ (1,0) [0|1] "" Vector__XXX
 SG_ KBI_Einheit_Temp : 6|1@1+ (1,0) [0|1] "" Vector__XXX
 SG_ KBI_Einheit_Uhrzeit : 7|1@1+ (1,0) [0|1] "" Vector__XXX
 SG_ KBI_Einheit_Verbrauch : 8|2@1+ (1,0) [0|3] "" Vector__XXX
 SG_ KBI_Einheit_Volumen : 10|2@1+ (1,0) [0|3] "" Vector__XXX
 SG_ KBI_Einheit_Sprache : 16|8@1+ (1,0) [0|255] "" Vector__XXX

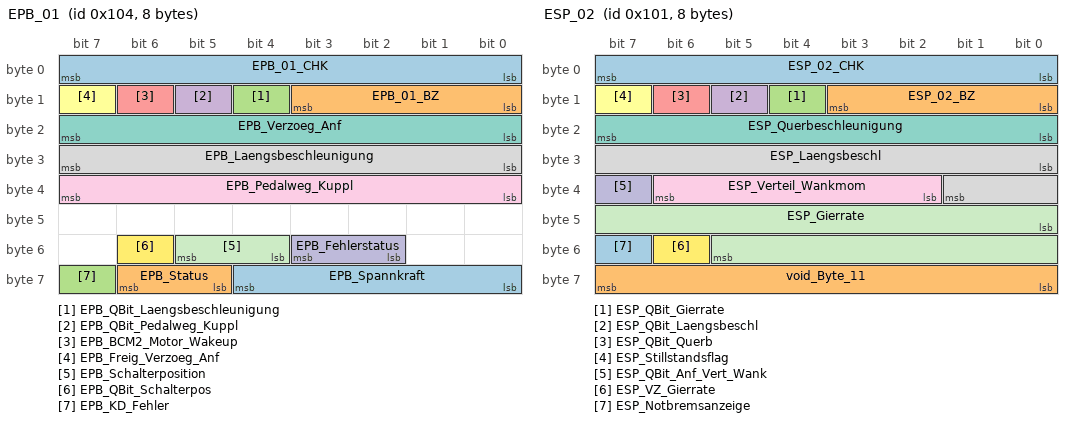
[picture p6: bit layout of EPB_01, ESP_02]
BO_ 260 EPB_01: 8 Gateway_B8
 SG_ EPB_01_CHK : 0|8@1+ (1,0) [0|255] ""  Daempfer_B8,Getriebe_AL6000,Getriebe_DL5001,Getriebe_VL3002,Motor_EDC17_003,Motor_EDC17_004,Motor_MED17_B8,Motor_MED9_B8,Motor_SIMOS8_B8
 SG_ EPB_01_BZ : 8|4@1+ (1,0) [0|15] ""  Daempfer_B8,Getriebe_AL6000,Getriebe_DL5001,Getriebe_VL3002,Motor_EDC17_003,Motor_EDC17_004,Motor_MED17_B8,Motor_MED9_B8,Motor_SIMOS8_B8
 SG_ EPB_QBit_Laengsbeschleunigung : 12|1@1+ (1,0) [0|1] ""  Getriebe_AL6000,Getriebe_DL5001,Getriebe_VL3002,Motor_EDC17_003,Motor_EDC17_004,Motor_MED17_B8,Motor_MED9_B8,Motor_SIMOS8_B8
 SG_ EPB_QBit_Pedalweg_Kuppl : 13|1@1+ (1,0) [0|1] ""  Motor_EDC17_003,Motor_EDC17_004,Motor_MED17_B8,Motor_MED9_B8,Motor_SIMOS8_B8
 SG_ EPB_BCM2_Motor_Wakeup : 14|1@1+ (1,0) [0|1] "" Vector__XXX
 SG_ EPB_Freig_Verzoeg_Anf : 15|1@1+ (1,0) [0|1] ""  Daempfer_B8,Getriebe_AL6000,Motor_EDC17_003,Motor_EDC17_004,Motor_MED17_B8,Motor_MED9_B8,Motor_SIMOS8_B8
 SG_ EPB_Verzoeg_Anf : 16|8@1+ (0.048,-7.968) [-7.968|4.224] "m/s2"  Daempfer_B8
 SG_ EPB_Laengsbeschleunigung : 24|8@1+ (1,-128) [-128|126] "%g"  Getriebe_AL6000,Getriebe_DL5001,Getriebe_VL3002,Motor_EDC17_003,Motor_EDC17_004,Motor_MED17_B8,Motor_MED9_B8,Motor_SIMOS8_B8
 SG_ EPB_Pedalweg_Kuppl : 32|8@1+ (0.4,0) [8|92] "%"  Motor_EDC17_003,Motor_EDC17_004,Motor_MED17_B8,Motor_MED9_B8,Motor_SIMOS8_B8
 SG_ EPB_Fehlerstatus : 50|2@1+ (1,0) [0|3] "" Vector__XXX
 SG_ EPB_Schalterposition : 52|2@1+ (1,0) [0|3] ""  Getriebe_AL6000,Motor_EDC17_003,Motor_EDC17_004,Motor_MED17_B8,Motor_MED9_B8,Motor_SIMOS8_B8
 SG_ EPB_QBit_Schalterpos : 54|1@1+ (1,0) [0|1] ""  Getriebe_AL6000,Motor_EDC17_003,Motor_EDC17_004,Motor_MED17_B8,Motor_MED9_B8,Motor_SIMOS8_B8
 SG_ EPB_Spannkraft : 56|5@1+ (1,0) [0|29] "kN"  Getriebe_AL6000
 SG_ EPB_Status : 61|2@1+ (1,0) [0|3] ""  Getriebe_AL6000,Motor_EDC17_003,Motor_EDC17_004,Motor_MED17_B8,Motor_MED9_B8,Motor_SIMOS8_B8
 SG_ EPB_KD_Fehler : 63|1@1+ (1,0) [0|1] "" Vector__XXX

BO_ 256 ESP_01: 8 Gateway_B8
 SG_ ESP_01_CHK : 0|8@1+ (1,0) [0|255] ""  Airbag_B8,Daempfer_B8,Getriebe_AL6000,Getriebe_DL5001,Getriebe_VL3002,Motor_EDC17_003,Motor_EDC17_004,Motor_MED17_B8,Motor_MED9_B8,Motor_SIMOS8_B8
 SG_ ESP_01_BZ : 8|4@1+ (1,0) [0|15] ""  Airbag_B8,Daempfer_B8,Getriebe_AL6000,Getriebe_DL5001,Getriebe_VL3002,Motor_EDC17_003,Motor_EDC17_004,Motor_MED17_B8,Motor_MED9_B8,Motor_SIMOS8_B8
 SG_ ASR_Moment_langsam : 12|10@1+ (1,0) [0|1021] ""  Airbag_B8,Getriebe_AL6000,Getriebe_DL5001,Motor_EDC17_003,Motor_EDC17_004,Motor_MED17_B8,Motor_MED9_B8,Motor_SIMOS8_B8
 SG_ ASR_MSR_Moment_schnell : 22|10@1+ (1,0) [0|1021] ""  Airbag_B8,Getriebe_AL6000,Getriebe_DL5001,Motor_EDC17_003,Motor_EDC17_004,Motor_MED17_B8,Motor_MED9_B8,Motor_SIMOS8_B8
 SG_ ESP_v_Signal : 32|16@1+ (0.01,0) [0|655.32] "km/h"  Airbag_B8,Daempfer_B8,Getriebe_AL6000,Getriebe_DL5001,Motor_EDC17_003,Motor_EDC17_004,Motor_MED17_B8,Motor_MED9_B8,Motor_SIMOS8_B8
 SG_ ASR_Tastung_passiv : 48|1@1+ (1,0) [0|1] ""  Airbag_B8,Getriebe_AL6000,Getriebe_DL5001,Getriebe_VL3002,Motor_EDC17_003,Motor_EDC17_004,Motor_MED17_B8,Motor_MED9_B8,Motor_SIMOS8_B8
 SG_ ESP_Tastung_passiv : 49|1@1+ (1,0) [0|1] ""  Airbag_B8,Getriebe_AL6000,Getriebe_DL5001,Getriebe_VL3002,Motor_EDC17_003,Motor_EDC17_004,Motor_MED17_B8,Motor_MED9_B8,Motor_SIMOS8_B8
 SG_ ESP_Systemstatus : 50|1@1+ (1,0) [0|1] ""  Airbag_B8,Motor_EDC17_003,Motor_EDC17_004,Motor_MED17_B8,Motor_MED9_B8,Motor_SIMOS8_B8
 SG_ ASR_Schalteingriff : 51|2@1+ (1,0) [0|3] ""  Airbag_B8,Getriebe_AL6000,Getriebe_DL5001,Getriebe_VL3002
 SG_ OBD_Schlechtweg : 53|1@1+ (1,0) [0|1] ""  Motor_EDC17_003,Motor_EDC17_004,Motor_MED17_B8,Motor_MED9_B8,Motor_SIMOS8_B8
 SG_ OBD_QBit_Schlechtweg : 54|1@1+ (1,0) [0|1] ""  Motor_EDC17_003,Motor_EDC17_004,Motor_MED17_B8,Motor_MED9_B8,Motor_SIMOS8_B8
 SG_ ESP_QBit_v_Signal : 55|1@1+ (1,0) [0|1] ""  Airbag_B8,Daempfer_B8,Getriebe_AL6000,Getriebe_DL5001,Motor_EDC17_003,Motor_EDC17_004,Motor_MED17_B8,Motor_MED9_B8,Motor_SIMOS8_B8
 SG_ ABS_Bremsung : 56|1@1+ (1,0) [0|1] ""  Airbag_B8,Daempfer_B8,Getriebe_AL6000,Getriebe_DL5001,Getriebe_VL3002,Motor_EDC17_003,Motor_EDC17_004,Motor_MED17_B8,Motor_MED9_B8,Motor_SIMOS8_B8
 SG_ ASR_Anf : 57|1@1+ (1,0) [0|1] ""  Airbag_B8,Getriebe_AL6000,Getriebe_DL5001,Getriebe_VL3002,Motor_EDC17_003,Motor_EDC17_004,Motor_MED17_B8,Motor_MED9_B8,Motor_SIMOS8_B8
 SG_ MSR_Anf : 58|1@1+ (1,0) [0|1] ""  Airbag_B8,Getriebe_VL3002,Motor_EDC17_003,Motor_EDC17_004,Motor_MED17_B8,Motor_MED9_B8,Motor_SIMOS8_B8
 SG_ EBV_Eingriff : 59|1@1+ (1,0) [0|1] ""  Airbag_B8,Daempfer_B8,Getriebe_AL6000,Getriebe_DL5001,Motor_EDC17_003,Motor_EDC17_004,Motor_MED17_B8,Motor_MED9_B8,Motor_SIMOS8_B8
 SG_ EDS_Eingriff : 60|1@1+ (1,0) [0|1] ""  Airbag_B8,Daempfer_B8,Getriebe_VL3002,Motor_EDC17_003,Motor_EDC17_004,Motor_MED17_B8,Motor_MED9_B8,Motor_SIMOS8_B8
 SG_ ESP_Eingriff : 61|1@1+ (1,0) [0|1] ""  Airbag_B8,Daempfer_B8,Getriebe_AL6000,Getriebe_DL5001,Getriebe_VL3002,Motor_EDC17_003,Motor_EDC17_004,Motor_MED17_B8,Motor_MED9_B8,Motor_SIMOS8_B8
 SG_ ESP_ASP : 62|1@1+ (1,0) [0|1] ""  Motor_EDC17_003,Motor_EDC17_004,Motor_MED17_B8,Motor_MED9_B8,Motor_SIMOS8_B8
 SG_ ESP_KD_Fehler : 63|1@1+ (1,0) [0|1] "" Vector__XXX

BO_ 257 ESP_02: 8 Gateway_B8
 SG_ ESP_02_CHK : 0|8@1+ (1,0) [0|255] ""  Daempfer_B8,Getriebe_AL6000,Getriebe_DL5001,Motor_EDC17_003,Motor_EDC17_004,Motor_MED17_B8,Motor_MED9_B8,Motor_SIMOS8_B8
 SG_ ESP_02_BZ : 8|4@1+ (1,0) [0|15] ""  Daempfer_B8,Getriebe_AL6000,Getriebe_DL5001,Motor_EDC17_003,Motor_EDC17_004,Motor_MED17_B8,Motor_MED9_B8,Motor_SIMOS8_B8
 SG_ ESP_QBit_Gierrate : 12|1@1+ (1,0) [0|1] ""  AFS_B8,Daempfer_B8
 SG_ ESP_QBit_Laengsbeschl : 13|1@1+ (1,0) [0|1] "" Vector__XXX
 SG_ ESP_QBit_Querb : 14|1@1+ (1,0) [0|1] ""  AFS_B8,Daempfer_B8,Getriebe_AL6000,Getriebe_DL5001,Motor_EDC17_003,Motor_EDC17_004,Motor_MED17_B8,Motor_MED9_B8,Motor_SIMOS8_B8
 SG_ ESP_Stillstandsflag : 15|1@1+ (1,0) [0|1] "" Vector__XXX
 SG_ ESP_Querbeschleunigung : 16|8@1+ (0.01,-1.27) [-1.27001|1.26999] "g"  AFS_B8,Daempfer_B8,Getriebe_AL6000,Getriebe_DL5001,Motor_EDC17_003,Motor_EDC17_004,Motor_MED17_B8,Motor_MED9_B8,Motor_SIMOS8_B8
 SG_ ESP_Laengsbeschl : 24|10@1+ (0.03125,-16) [-16|15.90625] "" Vector__XXX
 SG_ ESP_Verteil_Wankmom : 34|5@1+ (0.1,-1) [-1|1] "" Vector__XXX
 SG_ ESP_QBit_Anf_Vert_Wank : 39|1@1+ (1,0) [0|1] "" Vector__XXX
 SG_ ESP_Gierrate : 40|14@1+ (0.01,0) [0|163.82] "Grad/s"  AFS_B8,Daempfer_B8
 SG_ ESP_VZ_Gierrate : 54|1@1+ (1,0) [0|1] ""  AFS_B8,Daempfer_B8
 SG_ ESP_Notbremsanzeige : 55|1@1+ (1,0) [0|1] "" Vector__XXX
 SG_ void_Byte_11 : 56|8@1+ (1,0) [0|255] "" Vector__XXX

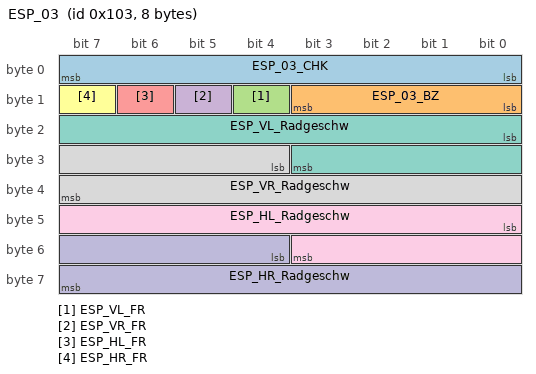
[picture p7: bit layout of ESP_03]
BO_ 259 ESP_03: 8 Gateway_B8
 SG_ ESP_03_CHK : 0|8@1+ (1,0) [0|255] ""  Getriebe_AL6000,Getriebe_DL5001,Getriebe_VL3002
 SG_ ESP_03_BZ : 8|4@1+ (1,0) [0|15] ""  Getriebe_AL6000,Getriebe_DL5001,Getriebe_VL3002
 SG_ ESP_VL_FR : 12|1@1+ (1,0) [0|1] ""  Getriebe_AL6000,Getriebe_DL5001
 SG_ ESP_VR_FR : 13|1@1+ (1,0) [0|1] ""  Getriebe_AL6000,Getriebe_DL5001
 SG_ ESP_HL_FR : 14|1@1+ (1,0) [0|1] ""  AFS_B8,Getriebe_AL6000,Getriebe_DL5001,LWR_B8
 SG_ ESP_HR_FR : 15|1@1+ (1,0) [0|1] ""  AFS_B8,Getriebe_AL6000,Getriebe_DL5001,LWR_B8
 SG_ ESP_VL_Radgeschw : 16|12@1+ (0.1,0) [0|409.2] "km/h"  Getriebe_AL6000,Getriebe_DL5001,Getriebe_VL3002
 SG_ ESP_VR_Radgeschw : 28|12@1+ (0.1,0) [0|409.2] "km/h"  Getriebe_AL6000,Getriebe_DL5001,Getriebe_VL3002
 SG_ ESP_HL_Radgeschw : 40|12@1+ (0.1,0) [0|409.2] "km/h"  AFS_B8,Getriebe_AL6000,Getriebe_DL5001,Getriebe_VL3002,LWR_B8
 SG_ ESP_HR_Radgeschw : 52|12@1+ (0.1,0) [0|409.2] "km/h"  AFS_B8,Getriebe_AL6000,Getriebe_DL5001,Getriebe_VL3002,LWR_B8

BO_TX_BU_ 490 : Getriebe_AL6000,Getriebe_DL5001,Getriebe_VL3002;
BO_TX_BU_ 488 : Motor_EDC17_003,Motor_EDC17_004,Motor_MED17_B8,Motor_MED9_B8,Motor_SIMOS8_B8;
BO_TX_BU_ 2616986625 : Motor_EDC17_003,Motor_EDC17_004,Motor_MED17_B8,Motor_MED9_B8,Motor_SIMOS8_B8;

CM_ "Generiert durch die EE-Vernetzungsdatenbank, Version 3.0.3";
CM_ SG_ 265 ACC_01_CHK "Bildung der CHK:

XOR Byte2 XOR Byte 3 ... XOR Byte n  XOR CHK-Endwert  = CHK

Ab B8 ist CHK-Endwert abhängig vom CAN-ID: CHK-Endwert = MSB XOR LSB
MSB: High-Byte des Identifiers der CAN-Botschaft
LSB: Low-Byte des Identifiers der CAN-Botschaft";
CM_ SG_ 265 ACC_zul_Regelabw_unten "Anforderung an den Triebstrangkoordinator. Zulässiger Betrag der Abweichung zwischen angeforderter 'ACC_Sollbeschleunigung' und umzusetzender Sollbeschleunigung  im TSK. Im TSK wird, abhängig vom Arbeitspunkt die Toleranz und die Sollbeschleunigung für da";
CM_ SG_ 265 ACC_Sollbeschleunigung "Anforderung an den Triebstrangkoordinator , eine 'ACC_Sollbeschleunigung' umzusetzen.";
CM_ SG_ 265 ACC_zul_Regelabw_oben "Anforderung an den Triebstrangkoordinator. Zulässiger Betrag der Abweichung zwischen angeforderter 'ACC_Sollbeschleunigung' und umzusetzender Sollbeschleunigung  im TSK. Im TSK wird, abhängig vom Arbeitspunkt die Toleranz und die Sollbeschleunigung für da";
CM_ SG_ 265 ACC_neg_Sollbeschl_Grad "Empfehlung an den Triebstrangkoordinator , mit welchem betragsmäßig maximalen negativen Gradienten eine ACC-Anforderung 'ACC_Sollbeschleunigung' einzuregeln ist.";
CM_ SG_ 265 ACC_pos_Sollbeschl_Grad "Empfehlung an den Triebstrangkoordinator , mit welchem betragsmäßig maximalen positiven Gradienten eine ACC-Anforderung 'ACC_Sollbeschleunigung' einzuregeln ist.";
CM_ SG_ 265 ACC_Anhalten "Im Falle eines gesetzten Bits wird vom ACC ein Anhalten bis in den Stand gewünscht. Das Bit wird von ACC nur unterhalb einer appl. Geschwindigkeitsschwelle gesetzt. Notwendig für die ACCplus-Funktionalität. Nicht für B8 relevant, jedoch im Vorgriff auf di";
CM_ SG_ 265 ACC_Dynamik "Über dieses Signal wird dem TSK mitgeteilt, in welchem Fahrprogramm das ACC aktuell betrieben wird. Wird im TSK verwendet, u.a. um im Falle ACC im Handschalter beim Wiedereinkuppeln das Moment abh. vom Fahrprogramm mit unterschiedlichen Rampen hochzufahre";
CM_ SG_ 265 ACC_Status_ACC "ACC-Status für Handshake mit Triebstrangkoordinator.
";
CM_ SG_ 265 ACC_Minimale_Bremsung "Im Falle eines gesetzten Bits wird vom ACC dem TSK angezeigt, dass es sich im Resume_Suspend_Mode befindet. In diesem Mode darf der TSK keine ECD-Bremsung anfordern, unabhängig von der 'ACC_Sollbeschleunigungsanforderung'. Eine Fahrzeugverzögerung darf nu";
CM_ SG_ 64 AB_Front_Crash "Bit wird bei Überschreitung der Gurtstraffer-, US- und RdW-Schwelle gesetzt";
CM_ SG_ 64 AB_Heck_Crash "Wird für alle neu anlaufenden Projekte umgesetzt: AB8.4, Audi8/VW8";
CM_ SG_ 64 AB_SF_Crash "Z.Zt. nur in Verbindung mit Crash-Intensität >= 100b (Kraftstoffpumpenabschaltung) verwendet.";
CM_ SG_ 64 AB_SB_Crash "Z.Zt. nur in Verbindung mit Crash-Intensität >= 100b (Kraftstoffpumpenabschaltung) verwendet.
";
CM_ SG_ 64 AB_Rollover_Crash "Wird im B6/B7 Cabrio und New Beetle Cabrio bedient. ";
CM_ SG_ 64 AB_Crash_Int "Die folgende Auswertung ist bei VW geplant:
>= 0x1: ZV auf
>= 0x2: Notruf ausgelöst
>= 0x4: Kraftstoffabschaltung (mit RDW-Schwelle aktiviert, d.h.Bit 7 = 1);

Information bleibt bei jeder Schwellwert-überschreitung für ~1 s bestehen
(Achtung: Ene";
CM_ SG_ 64 AB_Lampe "Sicherheitswarnlampe im Kombi wird vom Airbag-SG angesteuert; Zustand der Lampe wird auf dem CAN-Bus ausgegeben (auch Blinkinformation).";
CM_ SG_ 64 AB_Deaktiviert "Airbag oder Gurtstraffer wurden per Anpassung deaktiviert: Aktualisierung erst nach Selbsttest";
CM_ SG_ 64 AB_VB_deaktiviert "Als Option vorgehalten, Beifahrerairbag wurden per Schlüsselschalter oder Insassenerkennung deaktiviert";
CM_ SG_ 64 AB_Systemfehler "Systemfehler Ggf. wird Warnlampe dauernd eingeschaltet.";
CM_ SG_ 64 AB_Diagnose "Airbag in Diagnose";
CM_ SG_ 64 AB_Stellgliedtest "Information, ob Airbag im Stellgliedtest ist, um eine Notrufauflösung beim Stellgliedtest zu verhindern";
CM_ SG_ 64 AB_Erh_Auf_VB "Der Fahrer soll bei einem Statuswechsel des Beifahrerairbags (ausgelöst durch die Beifahrerinsassenerkennung oder den Schlüsselschloßschalter) aufmerksam gemacht werden durch eine Anzeige im Kombi. Nur Audi: gültig für: AB2 (4-Türer AU352), B7, C6, D3";
CM_ SG_ 64 AB_Gurtwarn_VF "Fahrer hat Gurt nicht gesteckt, Anzeige im Kombi";
CM_ SG_ 64 AB_Gurtwarn_VB "Beifahrer hat Gurt nicht gesteckt, Anzeige im Kombi";
CM_ SG_ 64 AB_Anzeige_Fussg "Anzeige für den Kunden, ob Reversierung der Motorhaube erfolgt ist";
CM_ SG_ 64 AB_KD_Fehler "Bei gesetztem Bit ist mindestens ein Kundendienstfehler eingetragen
";
CM_ SG_ 1312 AB_Belegung_VB "Belegungserkennung Vorne Beifahrer über Gurt-Wickelband
Wird in US-Steuergeräten Audi8R/VW8R/AB8.4E++ bedient, optional bei der RdW, falls SBE_EuroNCAP entschieden wird.
";
CM_ SG_ 1633 AAG_BZ "4bit-Botschaftszaehler, wird in jeder Sendebotschaft inkrementiert

";
CM_ SG_ 1633 AAG_Bremsl_durch_ECD "Bremslicht durch ECD aktiv";
CM_ SG_ 1633 AAG_Anhaenger_abgesteckt "Anhaenger wurde bei Kl. 15 aus abgesteckt";
CM_ SG_ 1633 AAG_NSL_aktiv "Anhaenger Nebelschlusslicht aktiv";
CM_ SG_ 1633 AAG_Anhaenger_erkannt "Erkennung Anhaenger ";
CM_ SG_ 1633 AAG_Blinker_H_aktiv "Status: Anhaenger Blinker aktiv";
CM_ SG_ 1633 AAG_Blinker_HL_def "Anhaenger Blinker links defekt";
CM_ SG_ 1633 AAG_Blinker_HR_def "Anhaenger Blinker rechts defekt";
CM_ SG_ 1633 AAG_Bremslicht_H_def "Anhaenger Bremslicht defekt";
CM_ SG_ 1633 AAG_Schlusslicht_HL_def "Anhaenger Schlußlicht links defekt";
CM_ SG_ 1633 AAG_Schlusslicht_HR_def "Anhaenger Schlußlicht rechts defekt";
CM_ SG_ 1633 AAG_KD_Fehler "Status Kundendienst-Fehlerspeicher";
CM_ SG_ 1633 AAG_AVS_Stati "Status AVS (bei abnehmbarer oder mech.schwenkbarer Anhängerkupplung ist der Status immer 0)
";
CM_ SG_ 777 BEM_01_CHK "Bildung der CHK:

XOR Byte2 XOR Byte 3 ... XOR Byte n  XOR CHK-Endwert  = CHK

Ab B8 ist CHK-Endwert abhängig vom CAN-ID: CHK-Endwert = MSB XOR LSB
MSB: High-Byte des Identifiers der CAN-Botschaft
LSB: Low-Byte des Identifiers der CAN-Botschaft";
CM_ SG_ 777 BEM_P_Generator "Es gilt: Signalspec BEM_P_Generator v1.0

Mechanische Generatorleistung dient dem Motorsteuergerät zur Berechnung der Motorlast; Genauigkeit ca. +/- (500W + 20% vom Messwert)";
CM_ SG_ 777 BEM_n_LLA "Es gilt: Signalspec BEM_n_LLA v1.0

Anforderung einer Leerlaufdrehzahlanhebung in zwei Stufen. Die Höhe der jeweiligen LL-Drehzahlstufe ist im Motorsteuergerät appliziert.



";
CM_ SG_ 777 BEM_01_Abschaltstufen "Signal inhaltlich identisch mit BEM_02_Abschaltstufen. Namentliche Umbenennung wegen Standard-SW im Gateway-BEM im B8 (Handling gleicher Signalnamen im Source-Code).
Abschaltstufen des Ruhestrommanagements
(Initialisierungswert aus EEPROM)";
CM_ SG_ 777 BEM_Anf_KL "Es gilt: Signalspec BEM_Anf_KL v1.1
Das BEM fordert über das MSG den Kühlerlüfter-Betrieb an; hierzu wird ein minimaler Leistungswert im MSG appliziert.
Szenario: bei erkannter abgetrennten Batterie soll durch Ansteuerung des Kühlerlüfters das Energien";
CM_ SG_ 867 BM_ZV_auf "Blinken bei ZV auf

";
CM_ SG_ 867 BM_ZV_zu "Blinken bei ZV zu

";
CM_ SG_ 867 BM_DWA_ein "Status Quittierungsblinken DWA";
CM_ SG_ 867 BM_DWA_Alarm "Status DWA-Alarmblinken
";
CM_ SG_ 867 BM_Crash "Status Crashblinken
";
CM_ SG_ 867 BM_Panik "Panikblinken
";
CM_ SG_ 867 BM_Not_Bremsung "Notbremsblinken

";
CM_ SG_ 867 BM_GDO "Blinken bei UGDO anlernen

";
CM_ SG_ 867 BM_links "Richtungsblinken links

";
CM_ SG_ 867 BM_rechts "Richtungsblinken rechts

";
CM_ SG_ 867 BM_Warnblinken "Warnblinken

";
CM_ SG_ 867 BM_Autobahn "Status Autobahnblinken
";
CM_ SG_ 867 BM_Taxi_Notalarm "Blinken bei Taxi-Not-Alarm

";
CM_ SG_ 867 BM_Telematik "Telematikblinken
";
CM_ SG_ 867 BM_WBT_Beleuchtung "Aktivierung Warnblinktasterfunktionsbeleuchtung
";
CM_ SG_ 867 Blinken_li_Fzg_Takt "Fzg-Takt Blinker links

";
CM_ SG_ 867 Blinken_re_Fzg_Takt "Fzg-Takt Blinker rechts

";
CM_ SG_ 867 Blinken_li_Kombi_Takt "Kombi-Takt Blinker links

";
CM_ SG_ 867 Blinken_re_Kombi_Takt "Kombi-Takt Blinker rechts

";
CM_ SG_ 867 Blinken_FWB_aktiv "Status freilaufendes Warnblinken
";
CM_ BO_ 482 "CCP in Serie mit 11Bit - Empfangskanal";
CM_ BO_ 490 "CCP in Serie mit 11Bit - Sendekanal";
CM_ BO_ 480 "CCP in Serie mit 11Bit - Empfangskanal";
CM_ BO_ 488 "CCP in Serie mit 11Bit - Sendekanal";
CM_ BO_ 901 "Die Botschaft wird bei aktiver Funktion (Betaetigung Charisma-Schalter) sowie bei Kl.15 EIN 5mal gesendet (kein Abmelden)";
CM_ SG_ 901 CHA_01_CHK "Bildung der CHK:

XOR Byte2 XOR Byte 3 ... XOR Byte n  XOR CHK-Endwert  = CHK

Ab B8 ist CHK-Endwert abhängig vom CAN-ID: CHK-Endwert = MSB XOR LSB
MSB: High-Byte des Identifiers der CAN-Botschaft
LSB: Low-Byte des Identifiers der CAN-Botschaft";
CM_ SG_ 901 CHA_01_BZ "Botschaftszaehler, wird aktuell noch nicht vom BCM1 bedient
(Vorhalt, falls Botschaft zyklisch wird)
";
CM_ SG_ 901 CHA_Systemstatus "Systemstatus Charisma Koordinator
";
CM_ SG_ 901 CHA_Ziel_FahrPr_MO "Anforderung Ziel-Fahrprogramm Motor";
CM_ SG_ 901 CHA_Ziel_FahrPr_GE "Anforderung Ziel-Fahrprogramm Getriebe";
CM_ SG_ 901 CHA_Ziel_FahrPr_ST "Anforderung Ziel-Fahrprogramm
";
CM_ SG_ 901 CHA_Ziel_FahrPr_SCU "Anforderung Ziel-Fahrprogramm SCU";
CM_ SG_ 901 CHA_Ziel_FahrPr_DR "Anforderung Ziel-Fahrprogramm Dämpfer

";
CM_ SG_ 901 CHA_Ziel_FahrPr_QS "Anforderung Ziel-Fahrprogramm Quattro Sport
";
CM_ SG_ 901 CHA_Ziel_FahrPr_Sys_7 "Anforderung Ziel-Fahrprogramm";
CM_ SG_ 901 CHA_Ziel_FahrPr_Sys_8 "Anforderung Ziel-Fahrprogramm";
CM_ SG_ 918 Daempfer_01_CHK "Bildung der CHK:

XOR Byte2 XOR Byte 3 ... XOR Byte n  XOR CHK-Endwert  = CHK

Ab B8 ist CHK-Endwert abhängig vom CAN-ID: CHK-Endwert = MSB XOR LSB
MSB: High-Byte des Identifiers der CAN-Botschaft
LSB: Low-Byte des Identifiers der CAN-Botschaft";
CM_ SG_ 918 DR_Systemstatus "Bei Statusänderung wird der Soll-Zustand ausgegeben. Der Status beschreibt einen Parametersatz: Temporäre Änderung der Dämpfereinstellungen werden hier nicht abgebildet.
";
CM_ SG_ 918 DR_Taster "Ausgabe der Position des Tasters der Dämpferregelung";
CM_ SG_ 918 DR_Gelbe_Warnlampe "Bit wird gesetzt, wenn während des Betriebes ein Fehler erkannt wird.";
CM_ SG_ 918 DR_Daempferreg_Texte "Die Textbits werden verwendet, um im Kombi Texte oder Bilder für die Dämpferregelung darzustellen

0x4 - 0xE tbd.

";
CM_ SG_ 918 DR_Charisma_FahrPr "Aktuelles Fahrprogramm des Charisma-Teilnehmers";
CM_ SG_ 918 DR_Charisma_Status "Charisma Systemstatus des Charisma-Teilnehmers";
CM_ SG_ 918 DR_Charisma_Umschaltung "Erkennung  Umschaltaufforderung des Charisma-Teilnehmers";
CM_ SG_ 1714 DGN_Verlernzaehler "Binär, wrap around";
CM_ SG_ 1714 KBI_Kilometerstand "Fehler wird ausgegeben, falls Kilometerstand nicht restaurierbar
";
CM_ SG_ 1714 UH_Monat "0x0D- 0xF =  Werte ungültig";
CM_ SG_ 1714 UH_Stunde "0x18 - 0x1F = Werte ungültig";
CM_ SG_ 1714 UH_Minute "0x3C- 0x3f = Werte ungültig";
CM_ SG_ 1714 UH_Sekunde "0x3C- 0x3f = Werte ungültig";
CM_ SG_ 1714 Kombi_02_alt "Veraltet Bit für die Signale:

Botschaft Diagnose_01:
KBI_Kilometerstand";
CM_ SG_ 1714 Uhrzeit_01_alt "Veraltet Bit für die Signale:

Botschaft Diagnose_01:
UH_Jahr
UH_Monat
UH_Tag
UH_Stunde
";
CM_ SG_ 1520 DI_KL_58d "Dimmwert für Funktionsbeleuchtung(u.a. Displays)
Um den hohen Dynamikbereich ohne sichtbare Sprungänderungen abzudecken, wird das Signal logarithmisch übertragen (Auflösung im unteren Dimmbereich höher). Im Detail gilt das Bauteil-Lastenheft LAH 8D0 900 ";
CM_ SG_ 1520 DI_KL_58s "Dimmwert für Suchbeleuchtung (z.B. Schaltersymbole, etc.)
0x7F = Fehlerwert, 0x7E = Init bzw. nicht verfuegbar;  gueltiger Wertebereich 0x0 - 0x64; ungueltiger Wertebereich 0x65 - 0x7D; Audi Sende Mindestabstand 50 ms, Hysterese +/- 3 Digits, Abtastung i";
CM_ SG_ 1520 DI_KL_58st "0x7F = Fehlerwert, 0x7E = Init bzw. nicht verfuegbar;  gueltiger Wertebereich 0x0 - 0x64; ungueltiger Wertebereich 0x65 - 0x7D; Audi Sende Mindestabstand 50 ms, Hysterese +/- 3 Digits, Abtastung im Empfänger-SG 50 ms";
CM_ SG_ 260 EPB_01_CHK "Bildung der CHK:

XOR Byte2 XOR Byte 3 ... XOR Byte n  XOR CHK-Endwert  = CHK

Ab B8 ist CHK-Endwert abhängig vom CAN-ID: CHK-Endwert = MSB XOR LSB
MSB: High-Byte des Identifiers der CAN-Botschaft
LSB: Low-Byte des Identifiers der CAN-Botschaft";
CM_ SG_ 260 EPB_QBit_Laengsbeschleunigung "Mitteilung z.Zt. für ACC, um unter bestimmten Zuständen mitzuteilen, daß Längsbeschleunigung temporär ungültig ist. Bsp.: Selbsttest Längsbeschleunigungssensor.";
CM_ SG_ 260 EPB_BCM2_Motor_Wakeup "EPB setzt dieses Bit, wenn EPB ein Nachwecken des ACAN fordert. Die Wakeup-Ursache des Car-Wakeup wird im NM high von den SG nicht ausgewertet, weswegen die Car-Wakeup-Information in einer konventionellen Applikationsbotschaft zum BCM2 gesendet werden. Da";
CM_ SG_ 260 EPB_Freig_Verzoeg_Anf "Verzögerungsanforderung  ";
CM_ SG_ 260 EPB_Verzoeg_Anf "Steuerungsanforderung an andere Systeme (z.B. ESP), um während der Fahrt, durch den Handbremsschalter ausgelöst, zu bremsen (ECD-Funktion)";
CM_ SG_ 260 EPB_Laengsbeschleunigung "Längsbeschleunigungssignal.
Achtung misst auch die Erdebeschleuinigung (stehend am Hang Wert !=0)

Entspricht bei kleinen Winkel dem Neigungswinkelsignal (<30%).";
CM_ SG_ 260 EPB_Pedalweg_Kuppl "Signal entspricht Tastverhältnis des PWM. Gesamtweg Kupplungspedal 10% bis 90%, damit zu erwartende Werte 25 bis 225. 25 bei Kupplungspedal nicht getreten, 225 bei Kupplungspedal voll durchgetreten.
2% Toleranz wird im Wertebereich ermöglicht (8%-92%).
";
CM_ SG_ 260 EPB_Schalterposition "Spiegelt die Schalterstellung wieder.

0x3 = Schalterfehler ";
CM_ SG_ 260 EPB_Spannkraft "Erzeugte Spannkraft. Bezieht sich auf die Aktuatoren.";
CM_ SG_ 260 EPB_Status "Gibt den Zustand der EPB-Aktuatoren an. Verknüpfung mit Fehlerstatus; wenn z.B. 'Linke Seite fehlerhaft' und 'Bremse geschlossen', dann ist nur die rechte Seite geschlossen. Das Bit wird gesetzt, wenn auf einer Seite Spannkraft aufgebaut wird. Wenn auf be";
CM_ SG_ 256 ESP_01_CHK "ACHTUNG: Ab v658_02 wird ein zusätzlicher Endwert verwendet wegen nich abwärtskompatible Änderungen!
Ab B8 ist CHK-Endwert abhängig vom CAN-ID: CHK-Endwert = MSB XOR LSB XOR 0xAA
MSB: High-Byte des Identifiers der CAN-Botschaft
LSB: Low-Byte des Identi";
CM_ SG_ 256 ASR_Moment_langsam "Achtung:
Einheitenloser CAN-Wert.
Faktor in MO_Faktor_Momente in Motor_Code_01 beachten!

Langsame reduzierende (ASR) Momentenanforderung an der Motor";
CM_ SG_ 256 ASR_MSR_Moment_schnell "Achtung:
Einheitenloser CAN-Wert.
Faktor in MO_Faktor_Momente in Motor_Code_01 beachten!

Schnelle reduzierende (ASR) oder erhöhende (MSR) Momentanforderung an den Motor, Eingriffsart wird über das Signal 'ASR_MSR_Eingriffsart' qualifiziert";
CM_ SG_ 256 ESP_v_Signal "Geschwindigkeitssignal vom ESP. Mittelwert der angetriebenen Räder.

Im B8 gilt die Signalspezifikation: LAH 8K0907AG_V1.3.pdf - Geschwindigkeitausgabe BOSCH ESP
";
CM_ SG_ 256 ASR_Tastung_passiv "ASR passiv getastet.
AUDI B8 front: Ab 70km/h wird das Bit automatisiert zurückgesetzt.
AUDI B8 quattro: Ab 70km/h wird das Bit automatisiert zurückgesetzt, ab 50km/h wieder zugeschalten.

Im B8 gilt die Funktionsspezifikation: LAH 8K0614D_V1.0.pdf - ";
CM_ SG_ 256 ESP_Tastung_passiv "ESP passiv getastet

Im B8 gilt die Funktionsspezifikation: LAH 8K0614D_V1.0.pdf - Passivtasterkonzept";
CM_ SG_ 256 ESP_Systemstatus "Fehler steht für Stillegung ESP mit Fehlereintrag.
AUDI B8: Flag wird bei Unterspannung im Stand bis einmalig 6km/h überschritten wurden nicht gesetzt (Ausblendung Startvorgang)";
CM_ SG_ 256 ASR_Schalteingriff "Wunsch an das Getriebe während einer ASR Regelung, bei Audi nur 0x0 und 0x1 genutzt

";
CM_ SG_ 256 OBD_Schlechtweg "Für Ausblendung der Zündaussetzererkennung im Motorsteuergerät (Otto). Bit wird gesetzt, wenn Rad-Drehbeschleunigung im ESP > Grenzwert ist. Vorteil gegenüber Radgeschwindigkeiten, dass ESP alle 2 ms dynamisch die Rad-Drehbeschleunigung errechnet und dem ";
CM_ SG_ 256 ESP_QBit_v_Signal "Geschwindigkeit wird vom ESP aus Ersatzwerten errechnet, wenn Bit gesetzt ist. Güte des Signals ist verändert.

Im B8 gilt die Signalspezifikation: LAH 8K0907AG_V1.3.pdf - Geschwindigkeitausgabe BOSCH ESP ";
CM_ SG_ 256 ABS_Bremsung "Antiblockiersystem, Bit zeigt auch Druckabbau an (z.B. ESP hat zuviel Druck aufgebaut oder ungebremste Regelung auf Bahnübergang)";
CM_ SG_ 256 ASR_Anf "Die Momentenanforderung 'ASR_MSR_Moment_schnell' und 'ASR_Moment_langsam' sind auszuführen";
CM_ SG_ 256 MSR_Anf "Die Momentenanforderung 'ASR_MSR_Moment_schnell' ist auszuführen.";
CM_ SG_ 256 EBV_Eingriff "Elektronische Bremskraftverteilung, aktueller Eingriff (Druckhalten, Druckabbau), kein ABS / ESP-Eingriff";
CM_ SG_ 256 EDS_Eingriff "Elektronische Differentialsperre";
CM_ SG_ 256 ESP_Eingriff "Eingriff des Fahrdynamikreglers";
CM_ SG_ 256 ESP_ASP "ASP = Anhaenger-Stabilisierungs-Programm";
CM_ SG_ 257 ESP_02_CHK "ACHTUNG: Ab v658_02 wird ein zusätzlicher Endwert verwendet wegen nich abwärtskompatible Änderungen!
Ab B8 ist CHK-Endwert abhängig vom CAN-ID: CHK-Endwert = MSB XOR LSB XOR 0xAA
MSB: High-Byte des Identifiers der CAN-Botschaft
LSB: Low-Byte des Identi";
CM_ SG_ 257 ESP_QBit_Gierrate "QBit der Giergeschwindigkeit, keine Filterung; ungültiger Wert kann bspw. aufgrund einer Unterspannung oder in der Initialisierungsphase ausgegeben werden.";
CM_ SG_ 257 ESP_QBit_Laengsbeschl "Vorhalt VW / nicht AUDI:
QBit der Längsbeschleunigung";
CM_ SG_ 257 ESP_QBit_Querb "Querbeschleunigung wird vom ESP aus Ersatzwerten errechnet, wenn Bit gesetzt ist. Güte des Signals ist verändert.

AUDI B8: Es wird kein Ersatzwert berechnet";
CM_ SG_ 257 ESP_Stillstandsflag "Bei RB-Projekten wird das Stillstandsflag gesetzt, wenn der absolute Stillstand der Raddrehzahlsensoren erkannt wurde, d.h. kein Zahn bewegt sich mehr. Dieses Bit wird bspw. im MOST für TV-Tuner-Abschaltung Australien verwendet, d.h. leichte Erschütterung";
CM_ SG_ 257 ESP_Querbeschleunigung "In ESP-Projekten bspw. ContiTEVES und RB wird ein Sensor-Cluster verwendet, welcher den gemessenen Sensorwert ausgibt. 0xFF bedeutet hier die Größe kann nicht errechnet werden.";
CM_ SG_ 257 ESP_Laengsbeschl "Vorhalt VW / nicht AUDI:
Sensorwert Längsbeschleunigung vom Sensorcluster";
CM_ SG_ 257 ESP_Verteil_Wankmom "Anforderung einer Wankmomentenverteilung an CDC (Exklusivnutzung!)

-1...-0,1 = Fahrzeug untersteuernd (Anforderung Dämpfer vorne weich / hinten hart)
0 = Fahrzeug neutral, keine Dämpferansteuerung erforderlich
+0,1...+1 = Fahrzeug übersteuernd: Anfor";
CM_ SG_ 257 ESP_QBit_Anf_Vert_Wank "QBit der Wankmomentenverteilung";
CM_ SG_ 257 ESP_Gierrate "Low_Byte = Byte 1; High_Byte = Byte 2; Nicht offsetkorrigierte, gemessene Giergeschwindigkeit
tatsächliche Auflösung Bosch ESP: 0,27 Grad/s
";
CM_ SG_ 257 ESP_VZ_Gierrate "Vorzeichen der Gierrate";
CM_ SG_ 257 ESP_Notbremsanzeige "Im B8 gilt das Lastenheft Adaptives Bremslicht V18.0.doc";
CM_ SG_ 259 ESP_03_CHK "Bildung der CHK:

XOR Byte2 XOR Byte 3 ... XOR Byte n  XOR CHK-Endwert  = CHK

Ab B8 ist CHK-Endwert abhängig vom CAN-ID: CHK-Endwert = MSB XOR LSB
MSB: High-Byte des Identifiers der CAN-Botschaft
LSB: Low-Byte des Identifiers der CAN-Botschaft";
CM_ SG_ 259 ESP_VL_FR "Fahrtrichtungserkennung Rad Vorne Links

Im B8 gilt die Signalspezifikation: LAH 8K0907AG_V1.3.pdf - Geschwindigkeitausgabe BOSCH ESP ";
CM_ SG_ 259 ESP_VR_FR "Fahrtrichtungserkennung Rad Vorne Rechts

Im B8 gilt die Signalspezifikation: LAH 8K0907AG_V1.3.pdf - Geschwindigkeitausgabe BOSCH ESP ";
CM_ SG_ 259 ESP_HL_FR "Fahrtrichtungserkennung Rad Hinten Links

Im B8 gilt die Signalspezifikation: LAH 8K0907AG_V1.3.pdf - Geschwindigkeitausgabe BOSCH ESP ";
CM_ SG_ 259 ESP_HR_FR "Fahrtrichtungserkennung Rad Hinten Rechts

Im B8 gilt die Signalspezifikation: LAH 8K0907AG_V1.3.pdf - Geschwindigkeitausgabe BOSCH ESP ";
CM_ SG_ 259 ESP_VL_Radgeschw "Im B8 gilt die Signalspezifikation: LAH 8K0907AG_V1.3.pdf - Geschwindigkeitausgabe BOSCH ESP ";
CM_ SG_ 259 ESP_VR_Radgeschw "Im B8 gilt die Signalspezifikation: LAH 8K0907AG_V1.3.pdf - Geschwindigkeitausgabe BOSCH ESP ";
CM_ SG_ 259 ESP_HL_Radgeschw "Im B8 gilt die Signalspezifikation: LAH 8K0907AG_V1.3.pdf - Geschwindigkeitausgabe BOSCH ESP ";
CM_ SG_ 259 ESP_HR_Radgeschw "Im B8 gilt die Signalspezifikation: LAH 8K0907AG_V1.3.pdf - Geschwindigkeitausgabe BOSCH ESP ";
BA_DEF_  "GenNWMApBusSleep" STRING ;
BA_DEF_  "GenNWMApCanNormal" STRING ;
BA_DEF_  "GenNWMApCanOff" STRING ;
BA_DEF_  "GenNWMApCanOn" STRING ;
BA_DEF_  "GenNWMApCanSleep" STRING ;
BA_DEF_  "GenNWMApCanWakeUp" STRING ;
BA_DEF_  "GenNWMGotoMode_Awake" STRING ;
BA_DEF_  "GenNWMGotoMode_BusSleep" STRING ;
BA_DEF_  "GenNWMSleepTime" INT 0 1000000;
BA_DEF_  "GenNWMTalkNM" STRING ;
BA_DEF_  "Manufacturer" STRING ;
BA_DEF_  "NmBaseAddress" HEX 0 2047;
BA_DEF_  "NWM-BasisAdresse" HEX 0 2047;
BA_DEF_  "NmMessageCount" INT 1 255;
BA_DEF_  "NWMMessageCount" INT 1 64;
BA_DEF_  "NmType" STRING ;
BA_DEF_  "NWM-Typ" ENUM  "VAG-OSEK","None";
BA_DEF_  "VAGTP20_SetupMessageCount" INT 0 255;
BA_DEF_  "VAGTP20_SetupStartAddress" HEX 0 2047;
BA_DEF_  "VersionDay" INT 1 31;
BA_DEF_  "VersionMonth" INT 1 12;
BA_DEF_  "VersionNumber" INT -2147483648 2147483647;
BA_DEF_  "VersionWeek" INT 1 52;
BA_DEF_  "VersionYear" INT 0 99;
BA_DEF_  "NmhBaseAddress" INT 0 0;
BA_DEF_  "NmhMessageCount" INT 0 0;
BA_DEF_ BU_  "GenNodAutoGenDsp" ENUM  "No","Yes";
BA_DEF_ BU_  "GenNodAutoGenSnd" ENUM  "No","Yes";
BA_DEF_ BU_  "GenNodSleepTime" INT 0 1000000;
BA_DEF_ BU_  "ILUsed" ENUM  "No","Yes";
BA_DEF_ BU_  "NmCAN" INT 1 2;
BA_DEF_ BU_  "NmNode" ENUM  "No","Yes";
BA_DEF_ BU_  "NWM-Knoten" ENUM  "No","Yes";
BA_DEF_ BU_  "NodeLayerModules" STRING ;
BA_DEF_ BU_  "VAGTP20_TargetAddress" HEX 0 127;
BA_DEF_ BU_  "NmhStationAddress" HEX 0 0;
BA_DEF_ BU_  "NmhNode" ENUM  "No","Yes";
BA_DEF_ BO_  "GenMsgAutoGenDsp" ENUM  "No","Yes";
BA_DEF_ BO_  "GenMsgAutoGenSnd" ENUM  "No","Yes";
BA_DEF_ BO_  "GenMsgCycleTime" INT 0 65535;
BA_DEF_ BO_  "GenMsgCycleTimeFast" INT 0 65535;
BA_DEF_ BO_  "GenMsgDelayTime" INT 0 100000;
BA_DEF_ BO_  "GenMsgILSupport" ENUM  "No","Yes";
BA_DEF_ BO_  "GenMsgNrOfRepetition" INT 0 100;
BA_DEF_ BO_  "GenMsgSendType" ENUM  "cyclicX","spontanX","cyclicIfActiveX","spontanWithDelay","cyclicAndSpontanX","cyclicAndSpontanWithDelay","spontanWithRepetition","cyclicIfActiveAndSpontanWD","cyclicIfActiveFast","cyclicWithRepeatOnDemand";
BA_DEF_ BO_  "GenMsgStartDelayTime" INT 0 100000;
BA_DEF_ BO_  "NmMessage" ENUM  "No","Yes";
BA_DEF_ BO_  "NmhMessage" ENUM  "No","Yes";
BA_DEF_ BO_  "NWM-Botschaft" ENUM  "No","Yes";
BA_DEF_ BO_  "VAGTP20_API" HEX 0 255;
BA_DEF_ BO_  "VAGTP20_DynConnection" ENUM  "No","Yes";
BA_DEF_ BO_  "VAGTP20_DynSetup" ENUM  "No","Yes";
BA_DEF_ BO_  "VAGTP20_StatConnection" ENUM  "No","Yes";
BA_DEF_ BO_  "Timeoutzeit" INT 0 1000000;
BA_DEF_ BO_  "akt_Dateninh_NM_Betr" ENUM  "No","Yes";
BA_DEF_ SG_  "GenSigAltSetting" STRING ;
BA_DEF_ SG_  "GenSigAssignSetting" STRING ;
BA_DEF_ SG_  "GenSigAutoGenDsp" ENUM  "No","Yes";
BA_DEF_ SG_  "GenSigAutoGenSnd" ENUM  "No","Yes";
BA_DEF_ SG_  "GenSigConditionalSend" STRING ;
BA_DEF_ SG_  "GenSigEnvVarType" ENUM  "int","float","undef";
BA_DEF_ SG_  "GenSigEVName" STRING ;
BA_DEF_ SG_  "GenSigInactiveValue" INT -2147483648 2147483647;
BA_DEF_ SG_  "GenSigPostIfSetting" STRING ;
BA_DEF_ SG_  "GenSigPostSetting" STRING ;
BA_DEF_ SG_  "GenSigPreIfSetting" STRING ;
BA_DEF_ SG_  "GenSigPreSetting" STRING ;
BA_DEF_ SG_  "GenSigSendType" ENUM  "Cyclic","OnWrite","OnWriteWithRepetition","OnChange","OnChangeWithRepetition","IfActive","IfActiveWithRepetition","NoSigSendType";
BA_DEF_ SG_  "GenSigStartValue" INT -2147483648 2147483647;
BA_DEF_ SG_  "NWM-WakeupAllowed" ENUM  "No","Yes";
BA_DEF_ SG_  "NMH-WakeupAllowed" ENUM  "No","Yes";
BA_DEF_ SG_  "GenSigTimeoutMsg_Motor_EDC17_003" HEX 0 2047;
BA_DEF_ SG_  "GenSigTimeoutMsg_Motor_EDC17_004" HEX 0 2047;
BA_DEF_ SG_  "GenSigTimeoutMsg_Motor_MED17_B8" HEX 0 2047;
BA_DEF_ SG_  "GenSigTimeoutMsg_Motor_MED9_B8" HEX 0 2047;
BA_DEF_ SG_  "GenSigTimeoutMsg_Motor_SIMOS8_B8" HEX 0 2047;
BA_DEF_ SG_  "GenSigTimeoutMsg_Daempfer_B8" HEX 0 2047;
BA_DEF_ SG_  "GenSigTimeoutMsg_Gateway_B8" HEX 0 2047;
BA_DEF_ SG_  "GenSigTimeoutMsg_Getriebe_AL6000" HEX 0 2047;
BA_DEF_ SG_  "GenSigTimeoutMsg_Getriebe_DL5001" HEX 0 2047;
BA_DEF_ SG_  "GenSigTimeoutMsg_Getriebe_VL3002" HEX 0 2047;
BA_DEF_ SG_  "GenSigTimeoutMsg_AFS_B8" HEX 0 2047;
BA_DEF_ SG_  "GenSigTimeoutMsg_Motor_Slave_B8" HEX 0 2047;
BA_DEF_ SG_  "GenSigTimeoutMsg_Airbag_B8" HEX 0 2047;
BA_DEF_ SG_  "GenSigTimeoutMsg_LWR_B8" HEX 0 2047;
BA_DEF_ SG_  "GenSigFuncType" ENUM  "NoFunction","MsgCounter","CRC-8","XOR","XOR-2","DatedBit","SW-Kl15","CHK","Constant","Protocol";
BA_DEF_ SG_  "GenSigSwitchedByIgnition" ENUM  "No","Yes";
BA_DEF_ SG_  "Fehlerwert" HEX 0 2147483647;
BA_DEF_ SG_  "GenSigMissingSourceValue" HEX 0 2147483647;
BA_DEF_ SG_  "SystemSignalLongSymbol" STRING ;
BA_DEF_DEF_  "GenNWMApBusSleep" "NMIndNetSDN()";
BA_DEF_DEF_  "GenNWMApCanNormal" "";
BA_DEF_DEF_  "GenNWMApCanOff" "NMIndNetOff()";
BA_DEF_DEF_  "GenNWMApCanOn" "NMIndNetOn()";
BA_DEF_DEF_  "GenNWMApCanSleep" "";
BA_DEF_DEF_  "GenNWMApCanWakeUp" "";
BA_DEF_DEF_  "GenNWMGotoMode_Awake" "Nmh_ReqNetOn()";
BA_DEF_DEF_  "GenNWMGotoMode_BusSleep" "Nmh_ReqNetOff()";
BA_DEF_DEF_  "GenNWMSleepTime" 0;
BA_DEF_DEF_  "GenNWMTalkNM" "Nmh_ReqNetOn()";
BA_DEF_DEF_  "Manufacturer" "";
BA_DEF_DEF_  "NmBaseAddress" 0;
BA_DEF_DEF_  "NWM-BasisAdresse" 0;
BA_DEF_DEF_  "NmMessageCount" 64;
BA_DEF_DEF_  "NWMMessageCount" 64;
BA_DEF_DEF_  "NmType" "VAG-OSEK";
BA_DEF_DEF_  "NWM-Typ" "VAG-OSEK";
BA_DEF_DEF_  "VAGTP20_SetupMessageCount" 128;
BA_DEF_DEF_  "VAGTP20_SetupStartAddress" 0;
BA_DEF_DEF_  "VersionDay" 10;
BA_DEF_DEF_  "VersionMonth" 10;
BA_DEF_DEF_  "VersionNumber" 0;
BA_DEF_DEF_  "VersionWeek" 41;
BA_DEF_DEF_  "VersionYear" 6;
BA_DEF_DEF_  "NmhBaseAddress" 0;
BA_DEF_DEF_  "NmhMessageCount" 0;
BA_DEF_DEF_  "GenNodAutoGenDsp" "Yes";
BA_DEF_DEF_  "GenNodAutoGenSnd" "Yes";
BA_DEF_DEF_  "GenNodSleepTime" 0;
BA_DEF_DEF_  "ILUsed" "";
BA_DEF_DEF_  "NmCAN" 1;
BA_DEF_DEF_  "NmNode" "No";
BA_DEF_DEF_  "NWM-Knoten" "No";
BA_DEF_DEF_  "NodeLayerModules" "";
BA_DEF_DEF_  "VAGTP20_TargetAddress" 0;
BA_DEF_DEF_  "NmhStationAddress" 0;
BA_DEF_DEF_  "NmhNode" "Yes";
BA_DEF_DEF_  "GenMsgAutoGenDsp" "Yes";
BA_DEF_DEF_  "GenMsgAutoGenSnd" "Yes";
BA_DEF_DEF_  "GenMsgCycleTime" 0;
BA_DEF_DEF_  "GenMsgCycleTimeFast" 0;
BA_DEF_DEF_  "GenMsgDelayTime" 0;
BA_DEF_DEF_  "GenMsgILSupport" "";
BA_DEF_DEF_  "GenMsgNrOfRepetition" 0;
BA_DEF_DEF_  "GenMsgSendType" "cyclicX";
BA_DEF_DEF_  "GenMsgStartDelayTime" 0;
BA_DEF_DEF_  "NmMessage" "No";
BA_DEF_DEF_  "NmhMessage" "No";
BA_DEF_DEF_  "NWM-Botschaft" "No";
BA_DEF_DEF_  "VAGTP20_API" 0;
BA_DEF_DEF_  "VAGTP20_DynConnection" "No";
BA_DEF_DEF_  "VAGTP20_DynSetup" "No";
BA_DEF_DEF_  "VAGTP20_StatConnection" "No";
BA_DEF_DEF_  "Timeoutzeit" 0;
BA_DEF_DEF_  "akt_Dateninh_NM_Betr" "";
BA_DEF_DEF_  "GenSigAltSetting" "";
BA_DEF_DEF_  "GenSigAssignSetting" "";
BA_DEF_DEF_  "GenSigAutoGenDsp" "";
BA_DEF_DEF_  "GenSigAutoGenSnd" "";
BA_DEF_DEF_  "GenSigConditionalSend" "";
BA_DEF_DEF_  "GenSigEnvVarType" "undef";
BA_DEF_DEF_  "GenSigEVName" "";
BA_DEF_DEF_  "GenSigInactiveValue" 0;
BA_DEF_DEF_  "GenSigPostIfSetting" "";
BA_DEF_DEF_  "GenSigPostSetting" "";
BA_DEF_DEF_  "GenSigPreIfSetting" "";
BA_DEF_DEF_  "GenSigPreSetting" "";
BA_DEF_DEF_  "GenSigSendType" "Cyclic";
BA_DEF_DEF_  "GenSigStartValue" 0;
BA_DEF_DEF_  "NWM-WakeupAllowed" "";
BA_DEF_DEF_  "NMH-WakeupAllowed" "";
BA_DEF_DEF_  "GenSigTimeoutMsg_Motor_EDC17_003" 0;
BA_DEF_DEF_  "GenSigTimeoutMsg_Motor_EDC17_004" 0;
BA_DEF_DEF_  "GenSigTimeoutMsg_Motor_MED17_B8" 0;
BA_DEF_DEF_  "GenSigTimeoutMsg_Motor_MED9_B8" 0;
BA_DEF_DEF_  "GenSigTimeoutMsg_Motor_SIMOS8_B8" 0;
BA_DEF_DEF_  "GenSigTimeoutMsg_Daempfer_B8" 0;
BA_DEF_DEF_  "GenSigTimeoutMsg_Gateway_B8" 0;
BA_DEF_DEF_  "GenSigTimeoutMsg_Getriebe_AL6000" 0;
BA_DEF_DEF_  "GenSigTimeoutMsg_Getriebe_DL5001" 0;
BA_DEF_DEF_  "GenSigTimeoutMsg_Getriebe_VL3002" 0;
BA_DEF_DEF_  "GenSigTimeoutMsg_AFS_B8" 0;
BA_DEF_DEF_  "GenSigTimeoutMsg_Motor_Slave_B8" 0;
BA_DEF_DEF_  "GenSigTimeoutMsg_Airbag_B8" 0;
BA_DEF_DEF_  "GenSigTimeoutMsg_LWR_B8" 0;
BA_DEF_DEF_  "GenSigFuncType" "";
BA_DEF_DEF_  "GenSigSwitchedByIgnition" "";
BA_DEF_DEF_  "Fehlerwert" 0;
BA_DEF_DEF_  "GenSigMissingSourceValue" 0;
BA_DEF_DEF_  "SystemSignalLongSymbol" "";
BA_ "GenNWMApBusSleep" "apBusSleep()";
BA_ "GenNWMApCanNormal" "apCanNormal()";
BA_ "GenNWMApCanOff" "apCanOff()";
BA_ "GenNWMApCanOn" "apCanOn()";
BA_ "GenNWMApCanSleep" "apCanSleep()";
BA_ "GenNWMApCanWakeUp" "apCanWakeUp()";
BA_ "GenNWMGotoMode_Awake" "gotoMode_Awake()";
BA_ "GenNWMGotoMode_BusSleep" "gotoMode_BusSleep()";
BA_ "GenNWMSleepTime" 30;
BA_ "GenNWMTalkNM" "talkNM()";
BA_ "Manufacturer" "VAG";
BA_ "NmBaseAddress" 1024;
BA_ "NWM-BasisAdresse" 1024;
BA_ "VAGTP20_SetupStartAddress" 512;
BA_ "NmhBaseAddress" 30;
BA_ "ILUsed" BU_ AFS_B8 0;
BA_ "VAGTP20_TargetAddress" BU_ AFS_B8 6;
BA_ "NmhNode" BU_ AFS_B8 0;
BA_ "ILUsed" BU_ Airbag_B8 0;
BA_ "VAGTP20_TargetAddress" BU_ Airbag_B8 5;
BA_ "NmhNode" BU_ Airbag_B8 0;
BA_ "ILUsed" BU_ Daempfer_B8 0;
BA_ "VAGTP20_TargetAddress" BU_ Daempfer_B8 12;
BA_ "NmhNode" BU_ Daempfer_B8 0;
BA_ "GenNodSleepTime" BU_ Gateway_B8 30000;
BA_ "ILUsed" BU_ Gateway_B8 0;
BA_ "NmNode" BU_ Gateway_B8 1;
BA_ "NWM-Knoten" BU_ Gateway_B8 1;
BA_ "NodeLayerModules" BU_ Gateway_B8 "VAGNM01.DLL";
BA_ "VAGTP20_TargetAddress" BU_ Gateway_B8 31;
BA_ "GenNodSleepTime" BU_ Getriebe_AL6000 30000;
BA_ "ILUsed" BU_ Getriebe_AL6000 0;
BA_ "NodeLayerModules" BU_ Getriebe_AL6000 "VAGNM01.DLL";
BA_ "VAGTP20_TargetAddress" BU_ Getriebe_AL6000 2;
BA_ "NmhStationAddress" BU_ Getriebe_AL6000 2;
BA_ "GenNodSleepTime" BU_ Getriebe_DL5001 30000;
BA_ "ILUsed" BU_ Getriebe_DL5001 0;
BA_ "NodeLayerModules" BU_ Getriebe_DL5001 "NMHigh.DLL";
BA_ "VAGTP20_TargetAddress" BU_ Getriebe_DL5001 2;
BA_ "NmhStationAddress" BU_ Getriebe_DL5001 2;
BA_ "GenNodSleepTime" BU_ Getriebe_VL3002 30000;
BA_ "ILUsed" BU_ Getriebe_VL3002 0;
BA_ "NodeLayerModules" BU_ Getriebe_VL3002 "VAGNM01.DLL";
BA_ "VAGTP20_TargetAddress" BU_ Getriebe_VL3002 2;
BA_ "NmhStationAddress" BU_ Getriebe_VL3002 2;
BA_ "ILUsed" BU_ LWR_B8 0;
BA_ "VAGTP20_TargetAddress" BU_ LWR_B8 6;
BA_ "NmhNode" BU_ LWR_B8 0;
BA_ "GenNodSleepTime" BU_ Motor_EDC17_003 30000;
BA_ "ILUsed" BU_ Motor_EDC17_003 0;
BA_ "NodeLayerModules" BU_ Motor_EDC17_003 "VAGNM01.DLL";
BA_ "VAGTP20_TargetAddress" BU_ Motor_EDC17_003 1;
BA_ "NmhStationAddress" BU_ Motor_EDC17_003 1;
BA_ "GenNodSleepTime" BU_ Motor_EDC17_004 30000;
BA_ "ILUsed" BU_ Motor_EDC17_004 0;
BA_ "NodeLayerModules" BU_ Motor_EDC17_004 "VAGNM01.DLL";
BA_ "VAGTP20_TargetAddress" BU_ Motor_EDC17_004 1;
BA_ "NmhStationAddress" BU_ Motor_EDC17_004 1;
BA_ "GenNodSleepTime" BU_ Motor_MED17_B8 30000;
BA_ "ILUsed" BU_ Motor_MED17_B8 0;
BA_ "NodeLayerModules" BU_ Motor_MED17_B8 "VAGNM01.DLL";
BA_ "VAGTP20_TargetAddress" BU_ Motor_MED17_B8 1;
BA_ "NmhStationAddress" BU_ Motor_MED17_B8 1;
BA_ "GenNodSleepTime" BU_ Motor_MED9_B8 30000;
BA_ "ILUsed" BU_ Motor_MED9_B8 0;
BA_ "NodeLayerModules" BU_ Motor_MED9_B8 "VAGNM01.DLL";
BA_ "VAGTP20_TargetAddress" BU_ Motor_MED9_B8 1;
BA_ "NmhStationAddress" BU_ Motor_MED9_B8 1;
BA_ "ILUsed" BU_ Motor_SIMOS8_B8 0;
BA_ "VAGTP20_TargetAddress" BU_ Motor_SIMOS8_B8 1;
BA_ "NmhStationAddress" BU_ Motor_SIMOS8_B8 1;
BA_ "GenNodSleepTime" BU_ Motor_Slave_B8 30000;
BA_ "ILUsed" BU_ Motor_Slave_B8 0;
BA_ "NodeLayerModules" BU_ Motor_Slave_B8 "VAGNM01.DLL";
BA_ "VAGTP20_TargetAddress" BU_ Motor_Slave_B8 21;
BA_ "NmhNode" BU_ Motor_Slave_B8 0;
BA_ "GenMsgCycleTime" BO_ 265 20;
BA_ "GenMsgILSupport" BO_ 265 1;
BA_ "akt_Dateninh_NM_Betr" BO_ 265 0;
BA_ "GenMsgCycleTime" BO_ 64 50;
BA_ "GenMsgDelayTime" BO_ 64 10;
BA_ "GenMsgILSupport" BO_ 64 1;
BA_ "GenMsgSendType" BO_ 64 5;
BA_ "akt_Dateninh_NM_Betr" BO_ 64 0;
BA_ "GenMsgCycleTime" BO_ 1312 200;
BA_ "GenMsgILSupport" BO_ 1312 1;
BA_ "akt_Dateninh_NM_Betr" BO_ 1312 0;
BA_ "GenMsgCycleTime" BO_ 1633 100;
BA_ "GenMsgILSupport" BO_ 1633 1;
BA_ "akt_Dateninh_NM_Betr" BO_ 1633 1;
BA_ "GenMsgCycleTime" BO_ 777 50;
BA_ "GenMsgILSupport" BO_ 777 0;
BA_ "akt_Dateninh_NM_Betr" BO_ 777 1;
BA_ "GenMsgCycleTime" BO_ 867 50;
BA_ "GenMsgILSupport" BO_ 867 1;
BA_ "GenMsgSendType" BO_ 867 7;
BA_ "akt_Dateninh_NM_Betr" BO_ 867 1;
BA_ "GenMsgILSupport" BO_ 482 0;
BA_ "GenMsgSendType" BO_ 482 7;
BA_ "akt_Dateninh_NM_Betr" BO_ 482 1;
BA_ "GenMsgILSupport" BO_ 490 0;
BA_ "GenMsgSendType" BO_ 490 7;
BA_ "akt_Dateninh_NM_Betr" BO_ 490 1;
BA_ "GenMsgILSupport" BO_ 480 0;
BA_ "GenMsgSendType" BO_ 480 7;
BA_ "akt_Dateninh_NM_Betr" BO_ 480 1;
BA_ "GenMsgILSupport" BO_ 2616986624 0;
BA_ "GenMsgSendType" BO_ 2616986624 7;
BA_ "akt_Dateninh_NM_Betr" BO_ 2616986624 1;
BA_ "GenMsgILSupport" BO_ 488 0;
BA_ "GenMsgSendType" BO_ 488 7;
BA_ "akt_Dateninh_NM_Betr" BO_ 488 1;
BA_ "GenMsgILSupport" BO_ 2616986625 0;
BA_ "GenMsgSendType" BO_ 2616986625 7;
BA_ "akt_Dateninh_NM_Betr" BO_ 2616986625 1;
BA_ "GenMsgILSupport" BO_ 481 0;
BA_ "GenMsgSendType" BO_ 481 7;
BA_ "akt_Dateninh_NM_Betr" BO_ 481 1;
BA_ "GenMsgILSupport" BO_ 2616986629 0;
BA_ "GenMsgSendType" BO_ 2616986629 7;
BA_ "akt_Dateninh_NM_Betr" BO_ 2616986629 1;
BA_ "GenMsgILSupport" BO_ 489 0;
BA_ "GenMsgSendType" BO_ 489 7;
BA_ "akt_Dateninh_NM_Betr" BO_ 489 1;
BA_ "GenMsgILSupport" BO_ 2616986630 0;
BA_ "GenMsgSendType" BO_ 2616986630 7;
BA_ "akt_Dateninh_NM_Betr" BO_ 2616986630 1;
BA_ "GenMsgCycleTime" BO_ 901 100;
BA_ "GenMsgILSupport" BO_ 901 1;
BA_ "GenMsgNrOfRepetition" BO_ 901 5;
BA_ "GenMsgSendType" BO_ 901 2;
BA_ "akt_Dateninh_NM_Betr" BO_ 901 1;
BA_ "GenMsgCycleTime" BO_ 918 100;
BA_ "GenMsgILSupport" BO_ 918 1;
BA_ "akt_Dateninh_NM_Betr" BO_ 918 1;
BA_ "GenMsgCycleTime" BO_ 1714 1000;
BA_ "GenMsgILSupport" BO_ 1714 1;
BA_ "akt_Dateninh_NM_Betr" BO_ 1714 1;
BA_ "GenMsgCycleTime" BO_ 1520 200;
BA_ "GenMsgDelayTime" BO_ 1520 50;
BA_ "GenMsgILSupport" BO_ 1520 1;
BA_ "akt_Dateninh_NM_Betr" BO_ 1520 1;
BA_ "GenMsgCycleTime" BO_ 260 20;
BA_ "GenMsgILSupport" BO_ 260 1;
BA_ "akt_Dateninh_NM_Betr" BO_ 260 1;
BA_ "GenMsgCycleTime" BO_ 256 20;
BA_ "GenMsgILSupport" BO_ 256 1;
BA_ "akt_Dateninh_NM_Betr" BO_ 256 1;
BA_ "GenMsgCycleTime" BO_ 257 20;
BA_ "GenMsgILSupport" BO_ 257 1;
BA_ "akt_Dateninh_NM_Betr" BO_ 257 1;
BA_ "GenMsgCycleTime" BO_ 259 20;
BA_ "GenMsgILSupport" BO_ 259 1;
BA_ "akt_Dateninh_NM_Betr" BO_ 259 1;
BA_ "GenSigAutoGenDsp" SG_ 265 ACC_01_CHK 1;
BA_ "GenSigAutoGenSnd" SG_ 265 ACC_01_CHK 1;
BA_ "GenSigSendType" SG_ 265 ACC_01_CHK 7;
BA_ "NWM-WakeupAllowed" SG_ 265 ACC_01_CHK 0;
BA_ "NMH-WakeupAllowed" SG_ 265 ACC_01_CHK 0;
BA_ "GenSigTimeoutMsg_Daempfer_B8" SG_ 265 ACC_01_CHK 265;
BA_ "GenSigTimeoutMsg_Motor_EDC17_003" SG_ 265 ACC_01_CHK 265;
BA_ "GenSigTimeoutMsg_Motor_EDC17_004" SG_ 265 ACC_01_CHK 265;
BA_ "GenSigTimeoutMsg_Motor_MED17_B8" SG_ 265 ACC_01_CHK 265;
BA_ "GenSigTimeoutMsg_Motor_MED9_B8" SG_ 265 ACC_01_CHK 265;
BA_ "GenSigTimeoutMsg_Motor_SIMOS8_B8" SG_ 265 ACC_01_CHK 265;
BA_ "GenSigAutoGenDsp" SG_ 265 ACC_01_BZ 1;
BA_ "GenSigAutoGenSnd" SG_ 265 ACC_01_BZ 1;
BA_ "GenSigSendType" SG_ 265 ACC_01_BZ 7;
BA_ "NWM-WakeupAllowed" SG_ 265 ACC_01_BZ 0;
BA_ "NMH-WakeupAllowed" SG_ 265 ACC_01_BZ 0;
BA_ "GenSigTimeoutMsg_Daempfer_B8" SG_ 265 ACC_01_BZ 265;
BA_ "GenSigTimeoutMsg_Motor_EDC17_003" SG_ 265 ACC_01_BZ 265;
BA_ "GenSigTimeoutMsg_Motor_EDC17_004" SG_ 265 ACC_01_BZ 265;
BA_ "GenSigTimeoutMsg_Motor_MED17_B8" SG_ 265 ACC_01_BZ 265;
BA_ "GenSigTimeoutMsg_Motor_MED9_B8" SG_ 265 ACC_01_BZ 265;
BA_ "GenSigTimeoutMsg_Motor_SIMOS8_B8" SG_ 265 ACC_01_BZ 265;
BA_ "GenSigAutoGenDsp" SG_ 265 ACC_zul_Regelabw_unten 1;
BA_ "GenSigAutoGenSnd" SG_ 265 ACC_zul_Regelabw_unten 1;
BA_ "GenSigSendType" SG_ 265 ACC_zul_Regelabw_unten 7;
BA_ "NWM-WakeupAllowed" SG_ 265 ACC_zul_Regelabw_unten 0;
BA_ "NMH-WakeupAllowed" SG_ 265 ACC_zul_Regelabw_unten 0;
BA_ "GenSigTimeoutMsg_Motor_EDC17_003" SG_ 265 ACC_zul_Regelabw_unten 265;
BA_ "GenSigTimeoutMsg_Motor_EDC17_004" SG_ 265 ACC_zul_Regelabw_unten 265;
BA_ "GenSigTimeoutMsg_Motor_MED17_B8" SG_ 265 ACC_zul_Regelabw_unten 265;
BA_ "GenSigTimeoutMsg_Motor_MED9_B8" SG_ 265 ACC_zul_Regelabw_unten 265;
BA_ "GenSigTimeoutMsg_Motor_SIMOS8_B8" SG_ 265 ACC_zul_Regelabw_unten 265;
BA_ "GenSigAutoGenDsp" SG_ 265 ACC_Sollbeschleunigung 0;
BA_ "GenSigAutoGenSnd" SG_ 265 ACC_Sollbeschleunigung 0;
BA_ "GenSigSendType" SG_ 265 ACC_Sollbeschleunigung 7;
BA_ "GenSigStartValue" SG_ 265 ACC_Sollbeschleunigung 1444;
BA_ "NWM-WakeupAllowed" SG_ 265 ACC_Sollbeschleunigung 0;
BA_ "NMH-WakeupAllowed" SG_ 265 ACC_Sollbeschleunigung 0;
BA_ "GenSigTimeoutMsg_Daempfer_B8" SG_ 265 ACC_Sollbeschleunigung 265;
BA_ "GenSigTimeoutMsg_Motor_EDC17_003" SG_ 265 ACC_Sollbeschleunigung 265;
BA_ "GenSigTimeoutMsg_Motor_EDC17_004" SG_ 265 ACC_Sollbeschleunigung 265;
BA_ "GenSigTimeoutMsg_Motor_MED17_B8" SG_ 265 ACC_Sollbeschleunigung 265;
BA_ "GenSigTimeoutMsg_Motor_MED9_B8" SG_ 265 ACC_Sollbeschleunigung 265;
BA_ "GenSigTimeoutMsg_Motor_SIMOS8_B8" SG_ 265 ACC_Sollbeschleunigung 265;
BA_ "GenSigAutoGenDsp" SG_ 265 ACC_zul_Regelabw_oben 1;
BA_ "GenSigAutoGenSnd" SG_ 265 ACC_zul_Regelabw_oben 1;
BA_ "GenSigSendType" SG_ 265 ACC_zul_Regelabw_oben 7;
BA_ "NWM-WakeupAllowed" SG_ 265 ACC_zul_Regelabw_oben 0;
BA_ "NMH-WakeupAllowed" SG_ 265 ACC_zul_Regelabw_oben 0;
BA_ "GenSigTimeoutMsg_Motor_EDC17_003" SG_ 265 ACC_zul_Regelabw_oben 265;
BA_ "GenSigTimeoutMsg_Motor_EDC17_004" SG_ 265 ACC_zul_Regelabw_oben 265;
BA_ "GenSigTimeoutMsg_Motor_MED17_B8" SG_ 265 ACC_zul_Regelabw_oben 265;
BA_ "GenSigTimeoutMsg_Motor_MED9_B8" SG_ 265 ACC_zul_Regelabw_oben 265;
BA_ "GenSigTimeoutMsg_Motor_SIMOS8_B8" SG_ 265 ACC_zul_Regelabw_oben 265;
BA_ "GenSigAutoGenDsp" SG_ 265 ACC_neg_Sollbeschl_Grad 1;
BA_ "GenSigAutoGenSnd" SG_ 265 ACC_neg_Sollbeschl_Grad 1;
BA_ "GenSigSendType" SG_ 265 ACC_neg_Sollbeschl_Grad 7;
BA_ "NWM-WakeupAllowed" SG_ 265 ACC_neg_Sollbeschl_Grad 0;
BA_ "NMH-WakeupAllowed" SG_ 265 ACC_neg_Sollbeschl_Grad 0;
BA_ "GenSigTimeoutMsg_Motor_EDC17_003" SG_ 265 ACC_neg_Sollbeschl_Grad 265;
BA_ "GenSigTimeoutMsg_Motor_EDC17_004" SG_ 265 ACC_neg_Sollbeschl_Grad 265;
BA_ "GenSigTimeoutMsg_Motor_MED17_B8" SG_ 265 ACC_neg_Sollbeschl_Grad 265;
BA_ "GenSigTimeoutMsg_Motor_MED9_B8" SG_ 265 ACC_neg_Sollbeschl_Grad 265;
BA_ "GenSigTimeoutMsg_Motor_SIMOS8_B8" SG_ 265 ACC_neg_Sollbeschl_Grad 265;
BA_ "GenSigAutoGenDsp" SG_ 265 ACC_pos_Sollbeschl_Grad 1;
BA_ "GenSigAutoGenSnd" SG_ 265 ACC_pos_Sollbeschl_Grad 1;
BA_ "GenSigSendType" SG_ 265 ACC_pos_Sollbeschl_Grad 7;
BA_ "NWM-WakeupAllowed" SG_ 265 ACC_pos_Sollbeschl_Grad 0;
BA_ "NMH-WakeupAllowed" SG_ 265 ACC_pos_Sollbeschl_Grad 0;
BA_ "GenSigTimeoutMsg_Motor_EDC17_003" SG_ 265 ACC_pos_Sollbeschl_Grad 265;
BA_ "GenSigTimeoutMsg_Motor_EDC17_004" SG_ 265 ACC_pos_Sollbeschl_Grad 265;
BA_ "GenSigTimeoutMsg_Motor_MED17_B8" SG_ 265 ACC_pos_Sollbeschl_Grad 265;
BA_ "GenSigTimeoutMsg_Motor_MED9_B8" SG_ 265 ACC_pos_Sollbeschl_Grad 265;
BA_ "GenSigTimeoutMsg_Motor_SIMOS8_B8" SG_ 265 ACC_pos_Sollbeschl_Grad 265;
BA_ "GenSigAutoGenDsp" SG_ 265 ACC_KD_Fehler 1;
BA_ "GenSigAutoGenSnd" SG_ 265 ACC_KD_Fehler 1;
BA_ "GenSigSendType" SG_ 265 ACC_KD_Fehler 7;
BA_ "NWM-WakeupAllowed" SG_ 265 ACC_KD_Fehler 0;
BA_ "NMH-WakeupAllowed" SG_ 265 ACC_KD_Fehler 0;
BA_ "GenSigAutoGenDsp" SG_ 265 ACC_Anhalten 1;
BA_ "GenSigAutoGenSnd" SG_ 265 ACC_Anhalten 1;
BA_ "GenSigSendType" SG_ 265 ACC_Anhalten 7;
BA_ "NWM-WakeupAllowed" SG_ 265 ACC_Anhalten 0;
BA_ "NMH-WakeupAllowed" SG_ 265 ACC_Anhalten 0;
BA_ "GenSigTimeoutMsg_Motor_EDC17_003" SG_ 265 ACC_Anhalten 265;
BA_ "GenSigTimeoutMsg_Motor_EDC17_004" SG_ 265 ACC_Anhalten 265;
BA_ "GenSigTimeoutMsg_Motor_MED17_B8" SG_ 265 ACC_Anhalten 265;
BA_ "GenSigTimeoutMsg_Motor_MED9_B8" SG_ 265 ACC_Anhalten 265;
BA_ "GenSigTimeoutMsg_Motor_SIMOS8_B8" SG_ 265 ACC_Anhalten 265;
BA_ "GenSigAutoGenDsp" SG_ 265 ACC_Dynamik 1;
BA_ "GenSigAutoGenSnd" SG_ 265 ACC_Dynamik 1;
BA_ "GenSigSendType" SG_ 265 ACC_Dynamik 7;
BA_ "NWM-WakeupAllowed" SG_ 265 ACC_Dynamik 0;
BA_ "NMH-WakeupAllowed" SG_ 265 ACC_Dynamik 0;
BA_ "GenSigTimeoutMsg_Motor_EDC17_003" SG_ 265 ACC_Dynamik 265;
BA_ "GenSigTimeoutMsg_Motor_EDC17_004" SG_ 265 ACC_Dynamik 265;
BA_ "GenSigTimeoutMsg_Motor_MED17_B8" SG_ 265 ACC_Dynamik 265;
BA_ "GenSigTimeoutMsg_Motor_MED9_B8" SG_ 265 ACC_Dynamik 265;
BA_ "GenSigTimeoutMsg_Motor_SIMOS8_B8" SG_ 265 ACC_Dynamik 265;
BA_ "GenSigAutoGenDsp" SG_ 265 ACC_Status_ACC 1;
BA_ "GenSigAutoGenSnd" SG_ 265 ACC_Status_ACC 1;
BA_ "GenSigSendType" SG_ 265 ACC_Status_ACC 7;
BA_ "NWM-WakeupAllowed" SG_ 265 ACC_Status_ACC 0;
BA_ "NMH-WakeupAllowed" SG_ 265 ACC_Status_ACC 0;
BA_ "GenSigTimeoutMsg_Daempfer_B8" SG_ 265 ACC_Status_ACC 265;
BA_ "GenSigTimeoutMsg_Motor_EDC17_003" SG_ 265 ACC_Status_ACC 265;
BA_ "GenSigTimeoutMsg_Motor_EDC17_004" SG_ 265 ACC_Status_ACC 265;
BA_ "GenSigTimeoutMsg_Motor_MED17_B8" SG_ 265 ACC_Status_ACC 265;
BA_ "GenSigTimeoutMsg_Motor_MED9_B8" SG_ 265 ACC_Status_ACC 265;
BA_ "GenSigTimeoutMsg_Motor_SIMOS8_B8" SG_ 265 ACC_Status_ACC 265;
BA_ "GenSigAutoGenDsp" SG_ 265 ACC_Minimale_Bremsung 1;
BA_ "GenSigAutoGenSnd" SG_ 265 ACC_Minimale_Bremsung 1;
BA_ "GenSigSendType" SG_ 265 ACC_Minimale_Bremsung 7;
BA_ "NWM-WakeupAllowed" SG_ 265 ACC_Minimale_Bremsung 0;
BA_ "NMH-WakeupAllowed" SG_ 265 ACC_Minimale_Bremsung 0;
BA_ "GenSigTimeoutMsg_Motor_EDC17_003" SG_ 265 ACC_Minimale_Bremsung 265;
BA_ "GenSigTimeoutMsg_Motor_EDC17_004" SG_ 265 ACC_Minimale_Bremsung 265;
BA_ "GenSigTimeoutMsg_Motor_MED17_B8" SG_ 265 ACC_Minimale_Bremsung 265;
BA_ "GenSigTimeoutMsg_Motor_MED9_B8" SG_ 265 ACC_Minimale_Bremsung 265;
BA_ "GenSigTimeoutMsg_Motor_SIMOS8_B8" SG_ 265 ACC_Minimale_Bremsung 265;
BA_ "GenSigAutoGenDsp" SG_ 64 Airbag_01_CHK 1;
BA_ "GenSigAutoGenSnd" SG_ 64 Airbag_01_CHK 1;
BA_ "GenSigEnvVarType" SG_ 64 Airbag_01_CHK 0;
BA_ "GenSigSendType" SG_ 64 Airbag_01_CHK 7;
BA_ "NWM-WakeupAllowed" SG_ 64 Airbag_01_CHK 0;
BA_ "NMH-WakeupAllowed" SG_ 64 Airbag_01_CHK 0;
BA_ "GenSigTimeoutMsg_Gateway_B8" SG_ 64 Airbag_01_CHK 64;
BA_ "GenSigTimeoutMsg_Motor_EDC17_003" SG_ 64 Airbag_01_CHK 64;
BA_ "GenSigTimeoutMsg_Motor_EDC17_004" SG_ 64 Airbag_01_CHK 64;
BA_ "GenSigTimeoutMsg_Motor_MED17_B8" SG_ 64 Airbag_01_CHK 64;
BA_ "GenSigTimeoutMsg_Motor_MED9_B8" SG_ 64 Airbag_01_CHK 64;
BA_ "GenSigTimeoutMsg_Motor_SIMOS8_B8" SG_ 64 Airbag_01_CHK 64;
BA_ "GenSigAutoGenDsp" SG_ 64 Airbag_01_BZ 1;
BA_ "GenSigAutoGenSnd" SG_ 64 Airbag_01_BZ 1;
BA_ "GenSigEnvVarType" SG_ 64 Airbag_01_BZ 0;
BA_ "GenSigSendType" SG_ 64 Airbag_01_BZ 7;
BA_ "NWM-WakeupAllowed" SG_ 64 Airbag_01_BZ 0;
BA_ "NMH-WakeupAllowed" SG_ 64 Airbag_01_BZ 0;
BA_ "GenSigTimeoutMsg_Gateway_B8" SG_ 64 Airbag_01_BZ 64;
BA_ "GenSigTimeoutMsg_Motor_EDC17_003" SG_ 64 Airbag_01_BZ 64;
BA_ "GenSigTimeoutMsg_Motor_EDC17_004" SG_ 64 Airbag_01_BZ 64;
BA_ "GenSigTimeoutMsg_Motor_MED17_B8" SG_ 64 Airbag_01_BZ 64;
BA_ "GenSigTimeoutMsg_Motor_MED9_B8" SG_ 64 Airbag_01_BZ 64;
BA_ "GenSigTimeoutMsg_Motor_SIMOS8_B8" SG_ 64 Airbag_01_BZ 64;
BA_ "GenSigAutoGenDsp" SG_ 64 AB_Front_Crash 1;
BA_ "GenSigAutoGenSnd" SG_ 64 AB_Front_Crash 1;
BA_ "GenSigEnvVarType" SG_ 64 AB_Front_Crash 0;
BA_ "GenSigSendType" SG_ 64 AB_Front_Crash 7;
BA_ "NWM-WakeupAllowed" SG_ 64 AB_Front_Crash 0;
BA_ "NMH-WakeupAllowed" SG_ 64 AB_Front_Crash 0;
BA_ "GenSigTimeoutMsg_Gateway_B8" SG_ 64 AB_Front_Crash 64;
BA_ "GenSigAutoGenDsp" SG_ 64 AB_Heck_Crash 1;
BA_ "GenSigAutoGenSnd" SG_ 64 AB_Heck_Crash 1;
BA_ "GenSigEnvVarType" SG_ 64 AB_Heck_Crash 0;
BA_ "GenSigSendType" SG_ 64 AB_Heck_Crash 7;
BA_ "NWM-WakeupAllowed" SG_ 64 AB_Heck_Crash 0;
BA_ "NMH-WakeupAllowed" SG_ 64 AB_Heck_Crash 0;
BA_ "GenSigTimeoutMsg_Gateway_B8" SG_ 64 AB_Heck_Crash 64;
BA_ "GenSigAutoGenDsp" SG_ 64 AB_SF_Crash 1;
BA_ "GenSigAutoGenSnd" SG_ 64 AB_SF_Crash 1;
BA_ "GenSigEnvVarType" SG_ 64 AB_SF_Crash 0;
BA_ "GenSigSendType" SG_ 64 AB_SF_Crash 7;
BA_ "NWM-WakeupAllowed" SG_ 64 AB_SF_Crash 0;
BA_ "NMH-WakeupAllowed" SG_ 64 AB_SF_Crash 0;
BA_ "GenSigTimeoutMsg_Gateway_B8" SG_ 64 AB_SF_Crash 64;
BA_ "GenSigAutoGenDsp" SG_ 64 AB_SB_Crash 1;
BA_ "GenSigAutoGenSnd" SG_ 64 AB_SB_Crash 1;
BA_ "GenSigEnvVarType" SG_ 64 AB_SB_Crash 0;
BA_ "GenSigSendType" SG_ 64 AB_SB_Crash 7;
BA_ "NWM-WakeupAllowed" SG_ 64 AB_SB_Crash 0;
BA_ "NMH-WakeupAllowed" SG_ 64 AB_SB_Crash 0;
BA_ "GenSigTimeoutMsg_Gateway_B8" SG_ 64 AB_SB_Crash 64;
BA_ "GenSigAutoGenDsp" SG_ 64 AB_Rollover_Crash 1;
BA_ "GenSigAutoGenSnd" SG_ 64 AB_Rollover_Crash 1;
BA_ "GenSigEnvVarType" SG_ 64 AB_Rollover_Crash 0;
BA_ "GenSigSendType" SG_ 64 AB_Rollover_Crash 7;
BA_ "NWM-WakeupAllowed" SG_ 64 AB_Rollover_Crash 0;
BA_ "NMH-WakeupAllowed" SG_ 64 AB_Rollover_Crash 0;
BA_ "GenSigTimeoutMsg_Gateway_B8" SG_ 64 AB_Rollover_Crash 64;
BA_ "GenSigAutoGenDsp" SG_ 64 AB_Crash_Int 1;
BA_ "GenSigAutoGenSnd" SG_ 64 AB_Crash_Int 1;
BA_ "GenSigEnvVarType" SG_ 64 AB_Crash_Int 0;
BA_ "GenSigSendType" SG_ 64 AB_Crash_Int 7;
BA_ "NWM-WakeupAllowed" SG_ 64 AB_Crash_Int 0;
BA_ "NMH-WakeupAllowed" SG_ 64 AB_Crash_Int 0;
BA_ "GenSigTimeoutMsg_Gateway_B8" SG_ 64 AB_Crash_Int 64;
BA_ "GenSigTimeoutMsg_Motor_EDC17_003" SG_ 64 AB_Crash_Int 64;
BA_ "GenSigTimeoutMsg_Motor_EDC17_004" SG_ 64 AB_Crash_Int 64;
BA_ "GenSigTimeoutMsg_Motor_MED17_B8" SG_ 64 AB_Crash_Int 64;
BA_ "GenSigTimeoutMsg_Motor_MED9_B8" SG_ 64 AB_Crash_Int 64;
BA_ "GenSigTimeoutMsg_Motor_SIMOS8_B8" SG_ 64 AB_Crash_Int 64;
BA_ "GenSigAutoGenDsp" SG_ 64 AB_Lampe 1;
BA_ "GenSigAutoGenSnd" SG_ 64 AB_Lampe 1;
BA_ "GenSigEnvVarType" SG_ 64 AB_Lampe 0;
BA_ "GenSigSendType" SG_ 64 AB_Lampe 7;
BA_ "GenSigStartValue" SG_ 64 AB_Lampe 1;
BA_ "NWM-WakeupAllowed" SG_ 64 AB_Lampe 0;
BA_ "NMH-WakeupAllowed" SG_ 64 AB_Lampe 0;
BA_ "GenSigTimeoutMsg_Gateway_B8" SG_ 64 AB_Lampe 64;
BA_ "GenSigAutoGenDsp" SG_ 64 AB_Deaktiviert 1;
BA_ "GenSigAutoGenSnd" SG_ 64 AB_Deaktiviert 1;
BA_ "GenSigEnvVarType" SG_ 64 AB_Deaktiviert 0;
BA_ "GenSigSendType" SG_ 64 AB_Deaktiviert 7;
BA_ "NWM-WakeupAllowed" SG_ 64 AB_Deaktiviert 0;
BA_ "NMH-WakeupAllowed" SG_ 64 AB_Deaktiviert 0;
BA_ "GenSigTimeoutMsg_Gateway_B8" SG_ 64 AB_Deaktiviert 64;
BA_ "GenSigAutoGenDsp" SG_ 64 AB_VB_deaktiviert 1;
BA_ "GenSigAutoGenSnd" SG_ 64 AB_VB_deaktiviert 1;
BA_ "GenSigEnvVarType" SG_ 64 AB_VB_deaktiviert 0;
BA_ "GenSigSendType" SG_ 64 AB_VB_deaktiviert 7;
BA_ "GenSigStartValue" SG_ 64 AB_VB_deaktiviert 1;
BA_ "NWM-WakeupAllowed" SG_ 64 AB_VB_deaktiviert 0;
BA_ "NMH-WakeupAllowed" SG_ 64 AB_VB_deaktiviert 0;
BA_ "GenSigTimeoutMsg_Gateway_B8" SG_ 64 AB_VB_deaktiviert 64;
BA_ "GenSigAutoGenDsp" SG_ 64 AB_Systemfehler 1;
BA_ "GenSigAutoGenSnd" SG_ 64 AB_Systemfehler 1;
BA_ "GenSigEnvVarType" SG_ 64 AB_Systemfehler 0;
BA_ "GenSigSendType" SG_ 64 AB_Systemfehler 7;
BA_ "NWM-WakeupAllowed" SG_ 64 AB_Systemfehler 0;
BA_ "NMH-WakeupAllowed" SG_ 64 AB_Systemfehler 0;
BA_ "GenSigTimeoutMsg_Gateway_B8" SG_ 64 AB_Systemfehler 64;
BA_ "GenSigAutoGenDsp" SG_ 64 AB_Diagnose 1;
BA_ "GenSigAutoGenSnd" SG_ 64 AB_Diagnose 1;
BA_ "GenSigEnvVarType" SG_ 64 AB_Diagnose 0;
BA_ "GenSigSendType" SG_ 64 AB_Diagnose 7;
BA_ "NWM-WakeupAllowed" SG_ 64 AB_Diagnose 0;
BA_ "NMH-WakeupAllowed" SG_ 64 AB_Diagnose 0;
BA_ "GenSigTimeoutMsg_Gateway_B8" SG_ 64 AB_Diagnose 64;
BA_ "GenSigAutoGenDsp" SG_ 64 AB_Stellgliedtest 1;
BA_ "GenSigAutoGenSnd" SG_ 64 AB_Stellgliedtest 1;
BA_ "GenSigEnvVarType" SG_ 64 AB_Stellgliedtest 0;
BA_ "GenSigSendType" SG_ 64 AB_Stellgliedtest 7;
BA_ "NWM-WakeupAllowed" SG_ 64 AB_Stellgliedtest 0;
BA_ "NMH-WakeupAllowed" SG_ 64 AB_Stellgliedtest 0;
BA_ "GenSigTimeoutMsg_Gateway_B8" SG_ 64 AB_Stellgliedtest 64;
BA_ "GenSigTimeoutMsg_Motor_EDC17_003" SG_ 64 AB_Stellgliedtest 64;
BA_ "GenSigTimeoutMsg_Motor_EDC17_004" SG_ 64 AB_Stellgliedtest 64;
BA_ "GenSigTimeoutMsg_Motor_MED17_B8" SG_ 64 AB_Stellgliedtest 64;
BA_ "GenSigTimeoutMsg_Motor_MED9_B8" SG_ 64 AB_Stellgliedtest 64;
BA_ "GenSigTimeoutMsg_Motor_SIMOS8_B8" SG_ 64 AB_Stellgliedtest 64;
BA_ "GenSigAutoGenDsp" SG_ 64 AB_Erh_Auf_VB 1;
BA_ "GenSigAutoGenSnd" SG_ 64 AB_Erh_Auf_VB 1;
BA_ "GenSigEnvVarType" SG_ 64 AB_Erh_Auf_VB 0;
BA_ "GenSigSendType" SG_ 64 AB_Erh_Auf_VB 7;
BA_ "NWM-WakeupAllowed" SG_ 64 AB_Erh_Auf_VB 0;
BA_ "NMH-WakeupAllowed" SG_ 64 AB_Erh_Auf_VB 0;
BA_ "GenSigTimeoutMsg_Gateway_B8" SG_ 64 AB_Erh_Auf_VB 64;
BA_ "GenSigAutoGenDsp" SG_ 64 AB_Gurtwarn_VF 1;
BA_ "GenSigAutoGenSnd" SG_ 64 AB_Gurtwarn_VF 1;
BA_ "GenSigEnvVarType" SG_ 64 AB_Gurtwarn_VF 0;
BA_ "GenSigSendType" SG_ 64 AB_Gurtwarn_VF 7;
BA_ "NWM-WakeupAllowed" SG_ 64 AB_Gurtwarn_VF 0;
BA_ "NMH-WakeupAllowed" SG_ 64 AB_Gurtwarn_VF 0;
BA_ "GenSigTimeoutMsg_Gateway_B8" SG_ 64 AB_Gurtwarn_VF 64;
BA_ "GenSigAutoGenDsp" SG_ 64 AB_Gurtwarn_VB 1;
BA_ "GenSigAutoGenSnd" SG_ 64 AB_Gurtwarn_VB 1;
BA_ "GenSigEnvVarType" SG_ 64 AB_Gurtwarn_VB 0;
BA_ "GenSigSendType" SG_ 64 AB_Gurtwarn_VB 7;
BA_ "NWM-WakeupAllowed" SG_ 64 AB_Gurtwarn_VB 0;
BA_ "NMH-WakeupAllowed" SG_ 64 AB_Gurtwarn_VB 0;
BA_ "GenSigTimeoutMsg_Gateway_B8" SG_ 64 AB_Gurtwarn_VB 64;
BA_ "GenSigAutoGenDsp" SG_ 64 AB_Anzeige_Fussg 1;
BA_ "GenSigAutoGenSnd" SG_ 64 AB_Anzeige_Fussg 1;
BA_ "GenSigSendType" SG_ 64 AB_Anzeige_Fussg 7;
BA_ "NWM-WakeupAllowed" SG_ 64 AB_Anzeige_Fussg 0;
BA_ "NMH-WakeupAllowed" SG_ 64 AB_Anzeige_Fussg 0;
BA_ "GenSigTimeoutMsg_Gateway_B8" SG_ 64 AB_Anzeige_Fussg 64;
BA_ "GenSigAutoGenDsp" SG_ 64 void_Byte_02 1;
BA_ "GenSigAutoGenSnd" SG_ 64 void_Byte_02 1;
BA_ "GenSigSendType" SG_ 64 void_Byte_02 7;
BA_ "NWM-WakeupAllowed" SG_ 64 void_Byte_02 0;
BA_ "NMH-WakeupAllowed" SG_ 64 void_Byte_02 0;
BA_ "GenSigTimeoutMsg_Gateway_B8" SG_ 64 void_Byte_02 64;
BA_ "GenSigAutoGenDsp" SG_ 64 void_Byte_03 1;
BA_ "GenSigAutoGenSnd" SG_ 64 void_Byte_03 1;
BA_ "GenSigSendType" SG_ 64 void_Byte_03 7;
BA_ "NWM-WakeupAllowed" SG_ 64 void_Byte_03 0;
BA_ "NMH-WakeupAllowed" SG_ 64 void_Byte_03 0;
BA_ "GenSigTimeoutMsg_Gateway_B8" SG_ 64 void_Byte_03 64;
BA_ "GenSigAutoGenDsp" SG_ 64 AB_KD_Fehler 1;
BA_ "GenSigAutoGenSnd" SG_ 64 AB_KD_Fehler 1;
BA_ "GenSigEnvVarType" SG_ 64 AB_KD_Fehler 0;
BA_ "GenSigSendType" SG_ 64 AB_KD_Fehler 7;
BA_ "NWM-WakeupAllowed" SG_ 64 AB_KD_Fehler 0;
BA_ "NMH-WakeupAllowed" SG_ 64 AB_KD_Fehler 0;
BA_ "GenSigTimeoutMsg_Gateway_B8" SG_ 64 AB_KD_Fehler 64;
BA_ "GenSigAutoGenDsp" SG_ 1312 AB_Belegung_VB 1;
BA_ "GenSigAutoGenSnd" SG_ 1312 AB_Belegung_VB 1;
BA_ "GenSigEnvVarType" SG_ 1312 AB_Belegung_VB 0;
BA_ "GenSigSendType" SG_ 1312 AB_Belegung_VB 7;
BA_ "NWM-WakeupAllowed" SG_ 1312 AB_Belegung_VB 0;
BA_ "NMH-WakeupAllowed" SG_ 1312 AB_Belegung_VB 0;
BA_ "GenSigTimeoutMsg_Gateway_B8" SG_ 1312 AB_Belegung_VB 1312;
BA_ "GenSigAutoGenDsp" SG_ 1633 AAG_BZ 1;
BA_ "GenSigAutoGenSnd" SG_ 1633 AAG_BZ 1;
BA_ "GenSigEnvVarType" SG_ 1633 AAG_BZ 0;
BA_ "GenSigSendType" SG_ 1633 AAG_BZ 7;
BA_ "NWM-WakeupAllowed" SG_ 1633 AAG_BZ 0;
BA_ "NMH-WakeupAllowed" SG_ 1633 AAG_BZ 0;
BA_ "GenSigTimeoutMsg_Getriebe_AL6000" SG_ 1633 AAG_BZ 1633;
BA_ "GenSigTimeoutMsg_Motor_EDC17_003" SG_ 1633 AAG_BZ 1633;
BA_ "GenSigTimeoutMsg_Motor_EDC17_004" SG_ 1633 AAG_BZ 1633;
BA_ "GenSigTimeoutMsg_Motor_MED17_B8" SG_ 1633 AAG_BZ 1633;
BA_ "GenSigTimeoutMsg_Motor_MED9_B8" SG_ 1633 AAG_BZ 1633;
BA_ "GenSigTimeoutMsg_Motor_SIMOS8_B8" SG_ 1633 AAG_BZ 1633;
BA_ "GenSigAutoGenDsp" SG_ 1633 AAG_Bremsl_durch_ECD 1;
BA_ "GenSigAutoGenSnd" SG_ 1633 AAG_Bremsl_durch_ECD 1;
BA_ "GenSigEnvVarType" SG_ 1633 AAG_Bremsl_durch_ECD 0;
BA_ "GenSigSendType" SG_ 1633 AAG_Bremsl_durch_ECD 7;
BA_ "NWM-WakeupAllowed" SG_ 1633 AAG_Bremsl_durch_ECD 0;
BA_ "NMH-WakeupAllowed" SG_ 1633 AAG_Bremsl_durch_ECD 0;
BA_ "GenSigTimeoutMsg_Motor_EDC17_003" SG_ 1633 AAG_Bremsl_durch_ECD 1633;
BA_ "GenSigTimeoutMsg_Motor_EDC17_004" SG_ 1633 AAG_Bremsl_durch_ECD 1633;
BA_ "GenSigTimeoutMsg_Motor_MED17_B8" SG_ 1633 AAG_Bremsl_durch_ECD 1633;
BA_ "GenSigTimeoutMsg_Motor_MED9_B8" SG_ 1633 AAG_Bremsl_durch_ECD 1633;
BA_ "GenSigTimeoutMsg_Motor_SIMOS8_B8" SG_ 1633 AAG_Bremsl_durch_ECD 1633;
BA_ "GenSigAutoGenDsp" SG_ 1633 AAG_Anhaenger_abgesteckt 1;
BA_ "GenSigAutoGenSnd" SG_ 1633 AAG_Anhaenger_abgesteckt 1;
BA_ "GenSigEnvVarType" SG_ 1633 AAG_Anhaenger_abgesteckt 0;
BA_ "GenSigSendType" SG_ 1633 AAG_Anhaenger_abgesteckt 7;
BA_ "NWM-WakeupAllowed" SG_ 1633 AAG_Anhaenger_abgesteckt 0;
BA_ "NMH-WakeupAllowed" SG_ 1633 AAG_Anhaenger_abgesteckt 0;
BA_ "GenSigAutoGenDsp" SG_ 1633 AAG_NSL_aktiv 1;
BA_ "GenSigAutoGenSnd" SG_ 1633 AAG_NSL_aktiv 1;
BA_ "GenSigEnvVarType" SG_ 1633 AAG_NSL_aktiv 0;
BA_ "GenSigSendType" SG_ 1633 AAG_NSL_aktiv 7;
BA_ "NWM-WakeupAllowed" SG_ 1633 AAG_NSL_aktiv 0;
BA_ "NMH-WakeupAllowed" SG_ 1633 AAG_NSL_aktiv 0;
BA_ "GenSigAutoGenDsp" SG_ 1633 AAG_Anhaenger_erkannt 1;
BA_ "GenSigAutoGenSnd" SG_ 1633 AAG_Anhaenger_erkannt 1;
BA_ "GenSigEnvVarType" SG_ 1633 AAG_Anhaenger_erkannt 0;
BA_ "GenSigSendType" SG_ 1633 AAG_Anhaenger_erkannt 7;
BA_ "NWM-WakeupAllowed" SG_ 1633 AAG_Anhaenger_erkannt 0;
BA_ "NMH-WakeupAllowed" SG_ 1633 AAG_Anhaenger_erkannt 0;
BA_ "GenSigTimeoutMsg_Getriebe_AL6000" SG_ 1633 AAG_Anhaenger_erkannt 1633;
BA_ "GenSigTimeoutMsg_Getriebe_DL5001" SG_ 1633 AAG_Anhaenger_erkannt 1633;
BA_ "GenSigTimeoutMsg_Getriebe_VL3002" SG_ 1633 AAG_Anhaenger_erkannt 1633;
BA_ "GenSigTimeoutMsg_Motor_EDC17_003" SG_ 1633 AAG_Anhaenger_erkannt 1633;
BA_ "GenSigTimeoutMsg_Motor_EDC17_004" SG_ 1633 AAG_Anhaenger_erkannt 1633;
BA_ "GenSigTimeoutMsg_Motor_MED17_B8" SG_ 1633 AAG_Anhaenger_erkannt 1633;
BA_ "GenSigTimeoutMsg_Motor_MED9_B8" SG_ 1633 AAG_Anhaenger_erkannt 1633;
BA_ "GenSigTimeoutMsg_Motor_SIMOS8_B8" SG_ 1633 AAG_Anhaenger_erkannt 1633;
BA_ "GenSigAutoGenDsp" SG_ 1633 AAG_Blinker_H_aktiv 1;
BA_ "GenSigAutoGenSnd" SG_ 1633 AAG_Blinker_H_aktiv 1;
BA_ "GenSigEnvVarType" SG_ 1633 AAG_Blinker_H_aktiv 0;
BA_ "GenSigSendType" SG_ 1633 AAG_Blinker_H_aktiv 7;
BA_ "NWM-WakeupAllowed" SG_ 1633 AAG_Blinker_H_aktiv 0;
BA_ "NMH-WakeupAllowed" SG_ 1633 AAG_Blinker_H_aktiv 0;
BA_ "GenSigAutoGenDsp" SG_ 1633 AAG_Blinker_HL_def 1;
BA_ "GenSigAutoGenSnd" SG_ 1633 AAG_Blinker_HL_def 1;
BA_ "GenSigEnvVarType" SG_ 1633 AAG_Blinker_HL_def 0;
BA_ "GenSigSendType" SG_ 1633 AAG_Blinker_HL_def 7;
BA_ "NWM-WakeupAllowed" SG_ 1633 AAG_Blinker_HL_def 0;
BA_ "NMH-WakeupAllowed" SG_ 1633 AAG_Blinker_HL_def 0;
BA_ "GenSigAutoGenDsp" SG_ 1633 AAG_Blinker_HR_def 1;
BA_ "GenSigAutoGenSnd" SG_ 1633 AAG_Blinker_HR_def 1;
BA_ "GenSigEnvVarType" SG_ 1633 AAG_Blinker_HR_def 0;
BA_ "GenSigSendType" SG_ 1633 AAG_Blinker_HR_def 7;
BA_ "NWM-WakeupAllowed" SG_ 1633 AAG_Blinker_HR_def 0;
BA_ "NMH-WakeupAllowed" SG_ 1633 AAG_Blinker_HR_def 0;
BA_ "GenSigAutoGenDsp" SG_ 1633 AAG_Bremslicht_H_def 1;
BA_ "GenSigAutoGenSnd" SG_ 1633 AAG_Bremslicht_H_def 1;
BA_ "GenSigEnvVarType" SG_ 1633 AAG_Bremslicht_H_def 0;
BA_ "GenSigSendType" SG_ 1633 AAG_Bremslicht_H_def 7;
BA_ "NWM-WakeupAllowed" SG_ 1633 AAG_Bremslicht_H_def 0;
BA_ "NMH-WakeupAllowed" SG_ 1633 AAG_Bremslicht_H_def 0;
BA_ "GenSigTimeoutMsg_Motor_EDC17_003" SG_ 1633 AAG_Bremslicht_H_def 1633;
BA_ "GenSigTimeoutMsg_Motor_EDC17_004" SG_ 1633 AAG_Bremslicht_H_def 1633;
BA_ "GenSigTimeoutMsg_Motor_MED17_B8" SG_ 1633 AAG_Bremslicht_H_def 1633;
BA_ "GenSigTimeoutMsg_Motor_MED9_B8" SG_ 1633 AAG_Bremslicht_H_def 1633;
BA_ "GenSigTimeoutMsg_Motor_SIMOS8_B8" SG_ 1633 AAG_Bremslicht_H_def 1633;
BA_ "GenSigAutoGenDsp" SG_ 1633 AAG_Schlusslicht_HL_def 1;
BA_ "GenSigAutoGenSnd" SG_ 1633 AAG_Schlusslicht_HL_def 1;
BA_ "GenSigEnvVarType" SG_ 1633 AAG_Schlusslicht_HL_def 0;
BA_ "GenSigSendType" SG_ 1633 AAG_Schlusslicht_HL_def 7;
BA_ "NWM-WakeupAllowed" SG_ 1633 AAG_Schlusslicht_HL_def 0;
BA_ "NMH-WakeupAllowed" SG_ 1633 AAG_Schlusslicht_HL_def 0;
BA_ "GenSigAutoGenDsp" SG_ 1633 AAG_Schlusslicht_HR_def 1;
BA_ "GenSigAutoGenSnd" SG_ 1633 AAG_Schlusslicht_HR_def 1;
BA_ "GenSigEnvVarType" SG_ 1633 AAG_Schlusslicht_HR_def 0;
BA_ "GenSigSendType" SG_ 1633 AAG_Schlusslicht_HR_def 7;
BA_ "NWM-WakeupAllowed" SG_ 1633 AAG_Schlusslicht_HR_def 0;
BA_ "NMH-WakeupAllowed" SG_ 1633 AAG_Schlusslicht_HR_def 0;
BA_ "GenSigAutoGenDsp" SG_ 1633 AAG_KD_Fehler 1;
BA_ "GenSigAutoGenSnd" SG_ 1633 AAG_KD_Fehler 1;
BA_ "GenSigEnvVarType" SG_ 1633 AAG_KD_Fehler 0;
BA_ "GenSigSendType" SG_ 1633 AAG_KD_Fehler 7;
BA_ "NWM-WakeupAllowed" SG_ 1633 AAG_KD_Fehler 0;
BA_ "NMH-WakeupAllowed" SG_ 1633 AAG_KD_Fehler 0;
BA_ "GenSigAutoGenDsp" SG_ 1633 AAG_AVS_Fehler 1;
BA_ "GenSigAutoGenSnd" SG_ 1633 AAG_AVS_Fehler 1;
BA_ "GenSigEnvVarType" SG_ 1633 AAG_AVS_Fehler 0;
BA_ "GenSigSendType" SG_ 1633 AAG_AVS_Fehler 7;
BA_ "NWM-WakeupAllowed" SG_ 1633 AAG_AVS_Fehler 0;
BA_ "NMH-WakeupAllowed" SG_ 1633 AAG_AVS_Fehler 0;
BA_ "GenSigAutoGenDsp" SG_ 1633 AAG_AVS_Stati 1;
BA_ "GenSigAutoGenSnd" SG_ 1633 AAG_AVS_Stati 1;
BA_ "GenSigEnvVarType" SG_ 1633 AAG_AVS_Stati 0;
BA_ "GenSigSendType" SG_ 1633 AAG_AVS_Stati 7;
BA_ "NWM-WakeupAllowed" SG_ 1633 AAG_AVS_Stati 0;
BA_ "NMH-WakeupAllowed" SG_ 1633 AAG_AVS_Stati 0;
BA_ "GenSigAutoGenDsp" SG_ 777 BEM_01_CHK 1;
BA_ "GenSigAutoGenSnd" SG_ 777 BEM_01_CHK 1;
BA_ "GenSigEnvVarType" SG_ 777 BEM_01_CHK 0;
BA_ "GenSigSendType" SG_ 777 BEM_01_CHK 7;
BA_ "NWM-WakeupAllowed" SG_ 777 BEM_01_CHK 0;
BA_ "NMH-WakeupAllowed" SG_ 777 BEM_01_CHK 0;
BA_ "GenSigTimeoutMsg_Motor_EDC17_003" SG_ 777 BEM_01_CHK 777;
BA_ "GenSigTimeoutMsg_Motor_EDC17_004" SG_ 777 BEM_01_CHK 777;
BA_ "GenSigTimeoutMsg_Motor_MED17_B8" SG_ 777 BEM_01_CHK 777;
BA_ "GenSigTimeoutMsg_Motor_MED9_B8" SG_ 777 BEM_01_CHK 777;
BA_ "GenSigTimeoutMsg_Motor_SIMOS8_B8" SG_ 777 BEM_01_CHK 777;
BA_ "GenSigAutoGenDsp" SG_ 777 BEM_01_BZ 1;
BA_ "GenSigAutoGenSnd" SG_ 777 BEM_01_BZ 1;
BA_ "GenSigEnvVarType" SG_ 777 BEM_01_BZ 0;
BA_ "GenSigSendType" SG_ 777 BEM_01_BZ 7;
BA_ "NWM-WakeupAllowed" SG_ 777 BEM_01_BZ 0;
BA_ "NMH-WakeupAllowed" SG_ 777 BEM_01_BZ 0;
BA_ "GenSigTimeoutMsg_Motor_EDC17_003" SG_ 777 BEM_01_BZ 777;
BA_ "GenSigTimeoutMsg_Motor_EDC17_004" SG_ 777 BEM_01_BZ 777;
BA_ "GenSigTimeoutMsg_Motor_MED17_B8" SG_ 777 BEM_01_BZ 777;
BA_ "GenSigTimeoutMsg_Motor_MED9_B8" SG_ 777 BEM_01_BZ 777;
BA_ "GenSigTimeoutMsg_Motor_SIMOS8_B8" SG_ 777 BEM_01_BZ 777;
BA_ "GenSigAutoGenDsp" SG_ 777 BEM_P_Generator 1;
BA_ "GenSigAutoGenSnd" SG_ 777 BEM_P_Generator 1;
BA_ "GenSigEnvVarType" SG_ 777 BEM_P_Generator 1;
BA_ "GenSigSendType" SG_ 777 BEM_P_Generator 7;
BA_ "NWM-WakeupAllowed" SG_ 777 BEM_P_Generator 0;
BA_ "NMH-WakeupAllowed" SG_ 777 BEM_P_Generator 0;
BA_ "GenSigTimeoutMsg_Motor_EDC17_003" SG_ 777 BEM_P_Generator 777;
BA_ "GenSigTimeoutMsg_Motor_EDC17_004" SG_ 777 BEM_P_Generator 777;
BA_ "GenSigTimeoutMsg_Motor_MED17_B8" SG_ 777 BEM_P_Generator 777;
BA_ "GenSigTimeoutMsg_Motor_MED9_B8" SG_ 777 BEM_P_Generator 777;
BA_ "GenSigTimeoutMsg_Motor_SIMOS8_B8" SG_ 777 BEM_P_Generator 777;
BA_ "GenSigAutoGenDsp" SG_ 777 BEM_n_LLA 1;
BA_ "GenSigAutoGenSnd" SG_ 777 BEM_n_LLA 1;
BA_ "GenSigEnvVarType" SG_ 777 BEM_n_LLA 0;
BA_ "GenSigSendType" SG_ 777 BEM_n_LLA 7;
BA_ "NWM-WakeupAllowed" SG_ 777 BEM_n_LLA 0;
BA_ "NMH-WakeupAllowed" SG_ 777 BEM_n_LLA 0;
BA_ "GenSigTimeoutMsg_Motor_EDC17_003" SG_ 777 BEM_n_LLA 777;
BA_ "GenSigTimeoutMsg_Motor_EDC17_004" SG_ 777 BEM_n_LLA 777;
BA_ "GenSigTimeoutMsg_Motor_MED17_B8" SG_ 777 BEM_n_LLA 777;
BA_ "GenSigTimeoutMsg_Motor_MED9_B8" SG_ 777 BEM_n_LLA 777;
BA_ "GenSigTimeoutMsg_Motor_SIMOS8_B8" SG_ 777 BEM_n_LLA 777;
BA_ "GenSigAutoGenDsp" SG_ 777 BEM_01_Abschaltstufen 1;
BA_ "GenSigAutoGenSnd" SG_ 777 BEM_01_Abschaltstufen 1;
BA_ "GenSigEnvVarType" SG_ 777 BEM_01_Abschaltstufen 0;
BA_ "GenSigSendType" SG_ 777 BEM_01_Abschaltstufen 7;
BA_ "NWM-WakeupAllowed" SG_ 777 BEM_01_Abschaltstufen 0;
BA_ "NMH-WakeupAllowed" SG_ 777 BEM_01_Abschaltstufen 0;
BA_ "GenSigTimeoutMsg_Motor_EDC17_003" SG_ 777 BEM_01_Abschaltstufen 777;
BA_ "GenSigTimeoutMsg_Motor_EDC17_004" SG_ 777 BEM_01_Abschaltstufen 777;
BA_ "GenSigTimeoutMsg_Motor_MED17_B8" SG_ 777 BEM_01_Abschaltstufen 777;
BA_ "GenSigTimeoutMsg_Motor_MED9_B8" SG_ 777 BEM_01_Abschaltstufen 777;
BA_ "GenSigTimeoutMsg_Motor_SIMOS8_B8" SG_ 777 BEM_01_Abschaltstufen 777;
BA_ "GenSigAutoGenDsp" SG_ 777 BEM_Anf_KL 1;
BA_ "GenSigAutoGenSnd" SG_ 777 BEM_Anf_KL 1;
BA_ "GenSigEnvVarType" SG_ 777 BEM_Anf_KL 0;
BA_ "GenSigSendType" SG_ 777 BEM_Anf_KL 7;
BA_ "NWM-WakeupAllowed" SG_ 777 BEM_Anf_KL 0;
BA_ "NMH-WakeupAllowed" SG_ 777 BEM_Anf_KL 0;
BA_ "GenSigTimeoutMsg_Motor_EDC17_003" SG_ 777 BEM_Anf_KL 777;
BA_ "GenSigTimeoutMsg_Motor_EDC17_004" SG_ 777 BEM_Anf_KL 777;
BA_ "GenSigTimeoutMsg_Motor_MED17_B8" SG_ 777 BEM_Anf_KL 777;
BA_ "GenSigTimeoutMsg_Motor_MED9_B8" SG_ 777 BEM_Anf_KL 777;
BA_ "GenSigTimeoutMsg_Motor_SIMOS8_B8" SG_ 777 BEM_Anf_KL 777;
BA_ "GenSigAutoGenDsp" SG_ 867 BM_ZV_auf 1;
BA_ "GenSigAutoGenSnd" SG_ 867 BM_ZV_auf 1;
BA_ "GenSigEnvVarType" SG_ 867 BM_ZV_auf 0;
BA_ "GenSigSendType" SG_ 867 BM_ZV_auf 7;
BA_ "NWM-WakeupAllowed" SG_ 867 BM_ZV_auf 0;
BA_ "NMH-WakeupAllowed" SG_ 867 BM_ZV_auf 0;
BA_ "GenSigAutoGenDsp" SG_ 867 BM_ZV_zu 1;
BA_ "GenSigAutoGenSnd" SG_ 867 BM_ZV_zu 1;
BA_ "GenSigEnvVarType" SG_ 867 BM_ZV_zu 0;
BA_ "GenSigSendType" SG_ 867 BM_ZV_zu 7;
BA_ "NWM-WakeupAllowed" SG_ 867 BM_ZV_zu 0;
BA_ "NMH-WakeupAllowed" SG_ 867 BM_ZV_zu 0;
BA_ "GenSigAutoGenDsp" SG_ 867 BM_DWA_ein 1;
BA_ "GenSigAutoGenSnd" SG_ 867 BM_DWA_ein 1;
BA_ "GenSigEnvVarType" SG_ 867 BM_DWA_ein 0;
BA_ "GenSigSendType" SG_ 867 BM_DWA_ein 7;
BA_ "NWM-WakeupAllowed" SG_ 867 BM_DWA_ein 0;
BA_ "NMH-WakeupAllowed" SG_ 867 BM_DWA_ein 0;
BA_ "GenSigAutoGenDsp" SG_ 867 BM_DWA_Alarm 1;
BA_ "GenSigAutoGenSnd" SG_ 867 BM_DWA_Alarm 1;
BA_ "GenSigEnvVarType" SG_ 867 BM_DWA_Alarm 0;
BA_ "GenSigSendType" SG_ 867 BM_DWA_Alarm 7;
BA_ "NWM-WakeupAllowed" SG_ 867 BM_DWA_Alarm 0;
BA_ "NMH-WakeupAllowed" SG_ 867 BM_DWA_Alarm 0;
BA_ "GenSigAutoGenDsp" SG_ 867 BM_Crash 1;
BA_ "GenSigAutoGenSnd" SG_ 867 BM_Crash 1;
BA_ "GenSigEnvVarType" SG_ 867 BM_Crash 0;
BA_ "GenSigSendType" SG_ 867 BM_Crash 7;
BA_ "NWM-WakeupAllowed" SG_ 867 BM_Crash 0;
BA_ "NMH-WakeupAllowed" SG_ 867 BM_Crash 0;
BA_ "GenSigAutoGenDsp" SG_ 867 BM_Panik 1;
BA_ "GenSigAutoGenSnd" SG_ 867 BM_Panik 1;
BA_ "GenSigEnvVarType" SG_ 867 BM_Panik 0;
BA_ "GenSigSendType" SG_ 867 BM_Panik 7;
BA_ "NWM-WakeupAllowed" SG_ 867 BM_Panik 0;
BA_ "NMH-WakeupAllowed" SG_ 867 BM_Panik 0;
BA_ "GenSigAutoGenDsp" SG_ 867 BM_Not_Bremsung 1;
BA_ "GenSigAutoGenSnd" SG_ 867 BM_Not_Bremsung 1;
BA_ "GenSigEnvVarType" SG_ 867 BM_Not_Bremsung 0;
BA_ "GenSigSendType" SG_ 867 BM_Not_Bremsung 7;
BA_ "NWM-WakeupAllowed" SG_ 867 BM_Not_Bremsung 0;
BA_ "NMH-WakeupAllowed" SG_ 867 BM_Not_Bremsung 0;
BA_ "GenSigAutoGenDsp" SG_ 867 BM_GDO 1;
BA_ "GenSigAutoGenSnd" SG_ 867 BM_GDO 1;
BA_ "GenSigEnvVarType" SG_ 867 BM_GDO 0;
BA_ "GenSigSendType" SG_ 867 BM_GDO 7;
BA_ "NWM-WakeupAllowed" SG_ 867 BM_GDO 0;
BA_ "NMH-WakeupAllowed" SG_ 867 BM_GDO 0;
BA_ "GenSigAutoGenDsp" SG_ 867 BM_links 1;
BA_ "GenSigAutoGenSnd" SG_ 867 BM_links 1;
BA_ "GenSigEnvVarType" SG_ 867 BM_links 0;
BA_ "GenSigSendType" SG_ 867 BM_links 7;
BA_ "NWM-WakeupAllowed" SG_ 867 BM_links 0;
BA_ "NMH-WakeupAllowed" SG_ 867 BM_links 0;
BA_ "GenSigAutoGenDsp" SG_ 867 BM_rechts 1;
BA_ "GenSigAutoGenSnd" SG_ 867 BM_rechts 1;
BA_ "GenSigEnvVarType" SG_ 867 BM_rechts 0;
BA_ "GenSigSendType" SG_ 867 BM_rechts 7;
BA_ "NWM-WakeupAllowed" SG_ 867 BM_rechts 0;
BA_ "NMH-WakeupAllowed" SG_ 867 BM_rechts 0;
BA_ "GenSigAutoGenDsp" SG_ 867 BM_Warnblinken 1;
BA_ "GenSigAutoGenSnd" SG_ 867 BM_Warnblinken 1;
BA_ "GenSigEnvVarType" SG_ 867 BM_Warnblinken 0;
BA_ "GenSigSendType" SG_ 867 BM_Warnblinken 7;
BA_ "NWM-WakeupAllowed" SG_ 867 BM_Warnblinken 0;
BA_ "NMH-WakeupAllowed" SG_ 867 BM_Warnblinken 0;
BA_ "GenSigAutoGenDsp" SG_ 867 BM_Autobahn 1;
BA_ "GenSigAutoGenSnd" SG_ 867 BM_Autobahn 1;
BA_ "GenSigEnvVarType" SG_ 867 BM_Autobahn 0;
BA_ "GenSigSendType" SG_ 867 BM_Autobahn 7;
BA_ "NWM-WakeupAllowed" SG_ 867 BM_Autobahn 0;
BA_ "NMH-WakeupAllowed" SG_ 867 BM_Autobahn 0;
BA_ "GenSigTimeoutMsg_AFS_B8" SG_ 867 BM_Autobahn 867;
BA_ "GenSigAutoGenDsp" SG_ 867 BM_Taxi_Notalarm 1;
BA_ "GenSigAutoGenSnd" SG_ 867 BM_Taxi_Notalarm 1;
BA_ "GenSigEnvVarType" SG_ 867 BM_Taxi_Notalarm 0;
BA_ "GenSigSendType" SG_ 867 BM_Taxi_Notalarm 7;
BA_ "NWM-WakeupAllowed" SG_ 867 BM_Taxi_Notalarm 0;
BA_ "NMH-WakeupAllowed" SG_ 867 BM_Taxi_Notalarm 0;
BA_ "GenSigAutoGenDsp" SG_ 867 BM_Telematik 1;
BA_ "GenSigAutoGenSnd" SG_ 867 BM_Telematik 1;
BA_ "GenSigEnvVarType" SG_ 867 BM_Telematik 0;
BA_ "GenSigSendType" SG_ 867 BM_Telematik 7;
BA_ "NWM-WakeupAllowed" SG_ 867 BM_Telematik 0;
BA_ "NMH-WakeupAllowed" SG_ 867 BM_Telematik 0;
BA_ "GenSigAutoGenDsp" SG_ 867 BM_WBT_Beleuchtung 1;
BA_ "GenSigAutoGenSnd" SG_ 867 BM_WBT_Beleuchtung 1;
BA_ "GenSigEnvVarType" SG_ 867 BM_WBT_Beleuchtung 0;
BA_ "GenSigSendType" SG_ 867 BM_WBT_Beleuchtung 7;
BA_ "NWM-WakeupAllowed" SG_ 867 BM_WBT_Beleuchtung 0;
BA_ "NMH-WakeupAllowed" SG_ 867 BM_WBT_Beleuchtung 0;
BA_ "GenSigAutoGenDsp" SG_ 867 Blinken_li_Fzg_Takt 1;
BA_ "GenSigAutoGenSnd" SG_ 867 Blinken_li_Fzg_Takt 1;
BA_ "GenSigEnvVarType" SG_ 867 Blinken_li_Fzg_Takt 0;
BA_ "GenSigSendType" SG_ 867 Blinken_li_Fzg_Takt 7;
BA_ "NWM-WakeupAllowed" SG_ 867 Blinken_li_Fzg_Takt 0;
BA_ "NMH-WakeupAllowed" SG_ 867 Blinken_li_Fzg_Takt 0;
BA_ "GenSigAutoGenDsp" SG_ 867 Blinken_re_Fzg_Takt 1;
BA_ "GenSigAutoGenSnd" SG_ 867 Blinken_re_Fzg_Takt 1;
BA_ "GenSigEnvVarType" SG_ 867 Blinken_re_Fzg_Takt 0;
BA_ "GenSigSendType" SG_ 867 Blinken_re_Fzg_Takt 7;
BA_ "NWM-WakeupAllowed" SG_ 867 Blinken_re_Fzg_Takt 0;
BA_ "NMH-WakeupAllowed" SG_ 867 Blinken_re_Fzg_Takt 0;
BA_ "GenSigAutoGenDsp" SG_ 867 Blinken_li_Kombi_Takt 1;
BA_ "GenSigAutoGenSnd" SG_ 867 Blinken_li_Kombi_Takt 1;
BA_ "GenSigEnvVarType" SG_ 867 Blinken_li_Kombi_Takt 0;
BA_ "GenSigSendType" SG_ 867 Blinken_li_Kombi_Takt 7;
BA_ "NWM-WakeupAllowed" SG_ 867 Blinken_li_Kombi_Takt 0;
BA_ "NMH-WakeupAllowed" SG_ 867 Blinken_li_Kombi_Takt 0;
BA_ "GenSigAutoGenDsp" SG_ 867 Blinken_re_Kombi_Takt 1;
BA_ "GenSigAutoGenSnd" SG_ 867 Blinken_re_Kombi_Takt 1;
BA_ "GenSigEnvVarType" SG_ 867 Blinken_re_Kombi_Takt 0;
BA_ "GenSigSendType" SG_ 867 Blinken_re_Kombi_Takt 7;
BA_ "NWM-WakeupAllowed" SG_ 867 Blinken_re_Kombi_Takt 0;
BA_ "NMH-WakeupAllowed" SG_ 867 Blinken_re_Kombi_Takt 0;
BA_ "GenSigAutoGenDsp" SG_ 867 Blinken_FWB_aktiv 1;
BA_ "GenSigAutoGenSnd" SG_ 867 Blinken_FWB_aktiv 1;
BA_ "GenSigEnvVarType" SG_ 867 Blinken_FWB_aktiv 0;
BA_ "GenSigSendType" SG_ 867 Blinken_FWB_aktiv 7;
BA_ "NWM-WakeupAllowed" SG_ 867 Blinken_FWB_aktiv 0;
BA_ "NMH-WakeupAllowed" SG_ 867 Blinken_FWB_aktiv 0;
BA_ "GenSigAutoGenDsp" SG_ 482 CCP_GE_CRO_01_Data 1;
BA_ "GenSigAutoGenSnd" SG_ 482 CCP_GE_CRO_01_Data 1;
BA_ "GenSigSendType" SG_ 482 CCP_GE_CRO_01_Data 7;
BA_ "NWM-WakeupAllowed" SG_ 482 CCP_GE_CRO_01_Data 0;
BA_ "NMH-WakeupAllowed" SG_ 482 CCP_GE_CRO_01_Data 0;
BA_ "GenSigTimeoutMsg_Getriebe_AL6000" SG_ 482 CCP_GE_CRO_01_Data 482;
BA_ "GenSigTimeoutMsg_Getriebe_DL5001" SG_ 482 CCP_GE_CRO_01_Data 482;
BA_ "GenSigTimeoutMsg_Getriebe_VL3002" SG_ 482 CCP_GE_CRO_01_Data 482;
BA_ "GenSigAutoGenDsp" SG_ 490 CCP_GE_DTO_01_Data 1;
BA_ "GenSigAutoGenSnd" SG_ 490 CCP_GE_DTO_01_Data 1;
BA_ "GenSigSendType" SG_ 490 CCP_GE_DTO_01_Data 7;
BA_ "NWM-WakeupAllowed" SG_ 490 CCP_GE_DTO_01_Data 0;
BA_ "NMH-WakeupAllowed" SG_ 490 CCP_GE_DTO_01_Data 0;
BA_ "GenSigAutoGenDsp" SG_ 480 CCP_MO_CRO_01_Data 1;
BA_ "GenSigAutoGenSnd" SG_ 480 CCP_MO_CRO_01_Data 1;
BA_ "GenSigSendType" SG_ 480 CCP_MO_CRO_01_Data 7;
BA_ "NWM-WakeupAllowed" SG_ 480 CCP_MO_CRO_01_Data 0;
BA_ "NMH-WakeupAllowed" SG_ 480 CCP_MO_CRO_01_Data 0;
BA_ "GenSigTimeoutMsg_Motor_EDC17_003" SG_ 480 CCP_MO_CRO_01_Data 480;
BA_ "GenSigTimeoutMsg_Motor_EDC17_004" SG_ 480 CCP_MO_CRO_01_Data 480;
BA_ "GenSigTimeoutMsg_Motor_MED17_B8" SG_ 480 CCP_MO_CRO_01_Data 480;
BA_ "GenSigTimeoutMsg_Motor_MED9_B8" SG_ 480 CCP_MO_CRO_01_Data 480;
BA_ "GenSigTimeoutMsg_Motor_SIMOS8_B8" SG_ 480 CCP_MO_CRO_01_Data 480;
BA_ "GenSigAutoGenDsp" SG_ 2616986624 CCP_MO_CRO_02_Data 1;
BA_ "GenSigAutoGenSnd" SG_ 2616986624 CCP_MO_CRO_02_Data 1;
BA_ "GenSigSendType" SG_ 2616986624 CCP_MO_CRO_02_Data 7;
BA_ "NWM-WakeupAllowed" SG_ 2616986624 CCP_MO_CRO_02_Data 0;
BA_ "NMH-WakeupAllowed" SG_ 2616986624 CCP_MO_CRO_02_Data 0;
BA_ "GenSigTimeoutMsg_Motor_EDC17_003" SG_ 2616986624 CCP_MO_CRO_02_Data 469502976;
BA_ "GenSigTimeoutMsg_Motor_EDC17_004" SG_ 2616986624 CCP_MO_CRO_02_Data 469502976;
BA_ "GenSigTimeoutMsg_Motor_MED17_B8" SG_ 2616986624 CCP_MO_CRO_02_Data 469502976;
BA_ "GenSigTimeoutMsg_Motor_MED9_B8" SG_ 2616986624 CCP_MO_CRO_02_Data 469502976;
BA_ "GenSigTimeoutMsg_Motor_SIMOS8_B8" SG_ 2616986624 CCP_MO_CRO_02_Data 469502976;
BA_ "GenSigAutoGenDsp" SG_ 488 CCP_MO_DTO_01_Data 1;
BA_ "GenSigAutoGenSnd" SG_ 488 CCP_MO_DTO_01_Data 1;
BA_ "GenSigSendType" SG_ 488 CCP_MO_DTO_01_Data 7;
BA_ "NWM-WakeupAllowed" SG_ 488 CCP_MO_DTO_01_Data 0;
BA_ "NMH-WakeupAllowed" SG_ 488 CCP_MO_DTO_01_Data 0;
BA_ "GenSigAutoGenDsp" SG_ 2616986625 CCP_MO_DTO_02_Data 1;
BA_ "GenSigAutoGenSnd" SG_ 2616986625 CCP_MO_DTO_02_Data 1;
BA_ "GenSigSendType" SG_ 2616986625 CCP_MO_DTO_02_Data 7;
BA_ "NWM-WakeupAllowed" SG_ 2616986625 CCP_MO_DTO_02_Data 0;
BA_ "NMH-WakeupAllowed" SG_ 2616986625 CCP_MO_DTO_02_Data 0;
BA_ "GenSigAutoGenDsp" SG_ 481 CCP_MOS_CRO_01_Data 1;
BA_ "GenSigAutoGenSnd" SG_ 481 CCP_MOS_CRO_01_Data 1;
BA_ "GenSigSendType" SG_ 481 CCP_MOS_CRO_01_Data 7;
BA_ "NWM-WakeupAllowed" SG_ 481 CCP_MOS_CRO_01_Data 0;
BA_ "NMH-WakeupAllowed" SG_ 481 CCP_MOS_CRO_01_Data 0;
BA_ "GenSigTimeoutMsg_Motor_Slave_B8" SG_ 481 CCP_MOS_CRO_01_Data 481;
BA_ "GenSigAutoGenDsp" SG_ 2616986629 CCP_MOS_CRO_02_Data 1;
BA_ "GenSigAutoGenSnd" SG_ 2616986629 CCP_MOS_CRO_02_Data 1;
BA_ "GenSigSendType" SG_ 2616986629 CCP_MOS_CRO_02_Data 7;
BA_ "NWM-WakeupAllowed" SG_ 2616986629 CCP_MOS_CRO_02_Data 0;
BA_ "NMH-WakeupAllowed" SG_ 2616986629 CCP_MOS_CRO_02_Data 0;
BA_ "GenSigTimeoutMsg_Motor_Slave_B8" SG_ 2616986629 CCP_MOS_CRO_02_Data 469502981;
BA_ "GenSigAutoGenDsp" SG_ 489 CCP_MOS_DTO_01_Data 1;
BA_ "GenSigAutoGenSnd" SG_ 489 CCP_MOS_DTO_01_Data 1;
BA_ "GenSigSendType" SG_ 489 CCP_MOS_DTO_01_Data 7;
BA_ "NWM-WakeupAllowed" SG_ 489 CCP_MOS_DTO_01_Data 0;
BA_ "NMH-WakeupAllowed" SG_ 489 CCP_MOS_DTO_01_Data 0;
BA_ "GenSigAutoGenDsp" SG_ 2616986630 CCP_MOS_DTO_02_Data 1;
BA_ "GenSigAutoGenSnd" SG_ 2616986630 CCP_MOS_DTO_02_Data 1;
BA_ "GenSigSendType" SG_ 2616986630 CCP_MOS_DTO_02_Data 7;
BA_ "NWM-WakeupAllowed" SG_ 2616986630 CCP_MOS_DTO_02_Data 0;
BA_ "NMH-WakeupAllowed" SG_ 2616986630 CCP_MOS_DTO_02_Data 0;
BA_ "GenSigAutoGenDsp" SG_ 901 CHA_01_CHK 1;
BA_ "GenSigAutoGenSnd" SG_ 901 CHA_01_CHK 1;
BA_ "GenSigSendType" SG_ 901 CHA_01_CHK 7;
BA_ "NWM-WakeupAllowed" SG_ 901 CHA_01_CHK 0;
BA_ "NMH-WakeupAllowed" SG_ 901 CHA_01_CHK 0;
BA_ "GenSigTimeoutMsg_Daempfer_B8" SG_ 901 CHA_01_CHK 901;
BA_ "GenSigTimeoutMsg_Getriebe_AL6000" SG_ 901 CHA_01_CHK 901;
BA_ "GenSigTimeoutMsg_Getriebe_DL5001" SG_ 901 CHA_01_CHK 901;
BA_ "GenSigTimeoutMsg_Getriebe_VL3002" SG_ 901 CHA_01_CHK 901;
BA_ "GenSigTimeoutMsg_Motor_EDC17_003" SG_ 901 CHA_01_CHK 901;
BA_ "GenSigTimeoutMsg_Motor_EDC17_004" SG_ 901 CHA_01_CHK 901;
BA_ "GenSigTimeoutMsg_Motor_MED17_B8" SG_ 901 CHA_01_CHK 901;
BA_ "GenSigTimeoutMsg_Motor_MED9_B8" SG_ 901 CHA_01_CHK 901;
BA_ "GenSigTimeoutMsg_Motor_SIMOS8_B8" SG_ 901 CHA_01_CHK 901;
BA_ "GenSigAutoGenDsp" SG_ 901 CHA_01_BZ 1;
BA_ "GenSigAutoGenSnd" SG_ 901 CHA_01_BZ 1;
BA_ "GenSigSendType" SG_ 901 CHA_01_BZ 7;
BA_ "NWM-WakeupAllowed" SG_ 901 CHA_01_BZ 0;
BA_ "NMH-WakeupAllowed" SG_ 901 CHA_01_BZ 0;
BA_ "GenSigAutoGenDsp" SG_ 901 CHA_Systemstatus 1;
BA_ "GenSigAutoGenSnd" SG_ 901 CHA_Systemstatus 1;
BA_ "GenSigSendType" SG_ 901 CHA_Systemstatus 7;
BA_ "NWM-WakeupAllowed" SG_ 901 CHA_Systemstatus 0;
BA_ "NMH-WakeupAllowed" SG_ 901 CHA_Systemstatus 0;
BA_ "GenSigTimeoutMsg_Daempfer_B8" SG_ 901 CHA_Systemstatus 901;
BA_ "GenSigTimeoutMsg_Getriebe_AL6000" SG_ 901 CHA_Systemstatus 901;
BA_ "GenSigTimeoutMsg_Getriebe_DL5001" SG_ 901 CHA_Systemstatus 901;
BA_ "GenSigTimeoutMsg_Getriebe_VL3002" SG_ 901 CHA_Systemstatus 901;
BA_ "GenSigTimeoutMsg_Motor_EDC17_003" SG_ 901 CHA_Systemstatus 901;
BA_ "GenSigTimeoutMsg_Motor_EDC17_004" SG_ 901 CHA_Systemstatus 901;
BA_ "GenSigTimeoutMsg_Motor_MED17_B8" SG_ 901 CHA_Systemstatus 901;
BA_ "GenSigTimeoutMsg_Motor_MED9_B8" SG_ 901 CHA_Systemstatus 901;
BA_ "GenSigTimeoutMsg_Motor_SIMOS8_B8" SG_ 901 CHA_Systemstatus 901;
BA_ "GenSigAutoGenDsp" SG_ 901 CHA_Ziel_FahrPr_MO 1;
BA_ "GenSigAutoGenSnd" SG_ 901 CHA_Ziel_FahrPr_MO 1;
BA_ "GenSigSendType" SG_ 901 CHA_Ziel_FahrPr_MO 7;
BA_ "NWM-WakeupAllowed" SG_ 901 CHA_Ziel_FahrPr_MO 0;
BA_ "NMH-WakeupAllowed" SG_ 901 CHA_Ziel_FahrPr_MO 0;
BA_ "GenSigTimeoutMsg_Motor_EDC17_003" SG_ 901 CHA_Ziel_FahrPr_MO 901;
BA_ "GenSigTimeoutMsg_Motor_EDC17_004" SG_ 901 CHA_Ziel_FahrPr_MO 901;
BA_ "GenSigTimeoutMsg_Motor_MED17_B8" SG_ 901 CHA_Ziel_FahrPr_MO 901;
BA_ "GenSigTimeoutMsg_Motor_MED9_B8" SG_ 901 CHA_Ziel_FahrPr_MO 901;
BA_ "GenSigTimeoutMsg_Motor_SIMOS8_B8" SG_ 901 CHA_Ziel_FahrPr_MO 901;
BA_ "GenSigAutoGenDsp" SG_ 901 CHA_Ziel_FahrPr_GE 1;
BA_ "GenSigAutoGenSnd" SG_ 901 CHA_Ziel_FahrPr_GE 1;
BA_ "GenSigSendType" SG_ 901 CHA_Ziel_FahrPr_GE 7;
BA_ "NWM-WakeupAllowed" SG_ 901 CHA_Ziel_FahrPr_GE 0;
BA_ "NMH-WakeupAllowed" SG_ 901 CHA_Ziel_FahrPr_GE 0;
BA_ "GenSigTimeoutMsg_Getriebe_AL6000" SG_ 901 CHA_Ziel_FahrPr_GE 901;
BA_ "GenSigTimeoutMsg_Getriebe_DL5001" SG_ 901 CHA_Ziel_FahrPr_GE 901;
BA_ "GenSigTimeoutMsg_Getriebe_VL3002" SG_ 901 CHA_Ziel_FahrPr_GE 901;
BA_ "GenSigAutoGenDsp" SG_ 901 CHA_Ziel_FahrPr_ST 1;
BA_ "GenSigAutoGenSnd" SG_ 901 CHA_Ziel_FahrPr_ST 1;
BA_ "GenSigSendType" SG_ 901 CHA_Ziel_FahrPr_ST 7;
BA_ "NWM-WakeupAllowed" SG_ 901 CHA_Ziel_FahrPr_ST 0;
BA_ "NMH-WakeupAllowed" SG_ 901 CHA_Ziel_FahrPr_ST 0;
BA_ "GenSigAutoGenDsp" SG_ 901 CHA_Ziel_FahrPr_SCU 1;
BA_ "GenSigAutoGenSnd" SG_ 901 CHA_Ziel_FahrPr_SCU 1;
BA_ "GenSigSendType" SG_ 901 CHA_Ziel_FahrPr_SCU 7;
BA_ "NWM-WakeupAllowed" SG_ 901 CHA_Ziel_FahrPr_SCU 0;
BA_ "NMH-WakeupAllowed" SG_ 901 CHA_Ziel_FahrPr_SCU 0;
BA_ "GenSigAutoGenDsp" SG_ 901 CHA_Ziel_FahrPr_DR 1;
BA_ "GenSigAutoGenSnd" SG_ 901 CHA_Ziel_FahrPr_DR 1;
BA_ "GenSigSendType" SG_ 901 CHA_Ziel_FahrPr_DR 7;
BA_ "NWM-WakeupAllowed" SG_ 901 CHA_Ziel_FahrPr_DR 0;
BA_ "NMH-WakeupAllowed" SG_ 901 CHA_Ziel_FahrPr_DR 0;
BA_ "GenSigTimeoutMsg_Daempfer_B8" SG_ 901 CHA_Ziel_FahrPr_DR 901;
BA_ "GenSigAutoGenDsp" SG_ 901 CHA_Ziel_FahrPr_QS 1;
BA_ "GenSigAutoGenSnd" SG_ 901 CHA_Ziel_FahrPr_QS 1;
BA_ "GenSigSendType" SG_ 901 CHA_Ziel_FahrPr_QS 7;
BA_ "NWM-WakeupAllowed" SG_ 901 CHA_Ziel_FahrPr_QS 0;
BA_ "NMH-WakeupAllowed" SG_ 901 CHA_Ziel_FahrPr_QS 0;
BA_ "GenSigAutoGenDsp" SG_ 901 CHA_Ziel_FahrPr_Sys_7 1;
BA_ "GenSigAutoGenSnd" SG_ 901 CHA_Ziel_FahrPr_Sys_7 1;
BA_ "GenSigSendType" SG_ 901 CHA_Ziel_FahrPr_Sys_7 7;
BA_ "NWM-WakeupAllowed" SG_ 901 CHA_Ziel_FahrPr_Sys_7 0;
BA_ "NMH-WakeupAllowed" SG_ 901 CHA_Ziel_FahrPr_Sys_7 0;
BA_ "GenSigAutoGenDsp" SG_ 901 CHA_Ziel_FahrPr_Sys_8 1;
BA_ "GenSigAutoGenSnd" SG_ 901 CHA_Ziel_FahrPr_Sys_8 1;
BA_ "GenSigSendType" SG_ 901 CHA_Ziel_FahrPr_Sys_8 7;
BA_ "NWM-WakeupAllowed" SG_ 901 CHA_Ziel_FahrPr_Sys_8 0;
BA_ "NMH-WakeupAllowed" SG_ 901 CHA_Ziel_FahrPr_Sys_8 0;
BA_ "GenSigAutoGenDsp" SG_ 918 Daempfer_01_CHK 1;
BA_ "GenSigAutoGenSnd" SG_ 918 Daempfer_01_CHK 1;
BA_ "GenSigSendType" SG_ 918 Daempfer_01_CHK 7;
BA_ "NWM-WakeupAllowed" SG_ 918 Daempfer_01_CHK 0;
BA_ "NMH-WakeupAllowed" SG_ 918 Daempfer_01_CHK 0;
BA_ "GenSigTimeoutMsg_Gateway_B8" SG_ 918 Daempfer_01_CHK 918;
BA_ "GenSigAutoGenDsp" SG_ 918 Daempfer_01_BZ 1;
BA_ "GenSigAutoGenSnd" SG_ 918 Daempfer_01_BZ 1;
BA_ "GenSigSendType" SG_ 918 Daempfer_01_BZ 7;
BA_ "NWM-WakeupAllowed" SG_ 918 Daempfer_01_BZ 0;
BA_ "NMH-WakeupAllowed" SG_ 918 Daempfer_01_BZ 0;
BA_ "GenSigTimeoutMsg_Gateway_B8" SG_ 918 Daempfer_01_BZ 918;
BA_ "GenSigAutoGenDsp" SG_ 918 DR_Systemstatus 0;
BA_ "GenSigAutoGenSnd" SG_ 918 DR_Systemstatus 0;
BA_ "GenSigSendType" SG_ 918 DR_Systemstatus 7;
BA_ "NWM-WakeupAllowed" SG_ 918 DR_Systemstatus 0;
BA_ "NMH-WakeupAllowed" SG_ 918 DR_Systemstatus 0;
BA_ "GenSigTimeoutMsg_Gateway_B8" SG_ 918 DR_Systemstatus 918;
BA_ "GenSigAutoGenDsp" SG_ 918 DR_Taster 0;
BA_ "GenSigAutoGenSnd" SG_ 918 DR_Taster 0;
BA_ "GenSigSendType" SG_ 918 DR_Taster 7;
BA_ "NWM-WakeupAllowed" SG_ 918 DR_Taster 0;
BA_ "NMH-WakeupAllowed" SG_ 918 DR_Taster 0;
BA_ "GenSigTimeoutMsg_Gateway_B8" SG_ 918 DR_Taster 918;
BA_ "GenSigAutoGenDsp" SG_ 918 DR_Gelbe_Warnlampe 0;
BA_ "GenSigAutoGenSnd" SG_ 918 DR_Gelbe_Warnlampe 0;
BA_ "GenSigSendType" SG_ 918 DR_Gelbe_Warnlampe 7;
BA_ "NWM-WakeupAllowed" SG_ 918 DR_Gelbe_Warnlampe 0;
BA_ "NMH-WakeupAllowed" SG_ 918 DR_Gelbe_Warnlampe 0;
BA_ "GenSigTimeoutMsg_Gateway_B8" SG_ 918 DR_Gelbe_Warnlampe 918;
BA_ "GenSigAutoGenDsp" SG_ 918 DR_Daempferreg_Texte 0;
BA_ "GenSigAutoGenSnd" SG_ 918 DR_Daempferreg_Texte 0;
BA_ "GenSigSendType" SG_ 918 DR_Daempferreg_Texte 7;
BA_ "NWM-WakeupAllowed" SG_ 918 DR_Daempferreg_Texte 0;
BA_ "NMH-WakeupAllowed" SG_ 918 DR_Daempferreg_Texte 0;
BA_ "GenSigTimeoutMsg_Gateway_B8" SG_ 918 DR_Daempferreg_Texte 918;
BA_ "GenSigAutoGenDsp" SG_ 918 DR_Charisma_FahrPr 1;
BA_ "GenSigAutoGenSnd" SG_ 918 DR_Charisma_FahrPr 1;
BA_ "GenSigSendType" SG_ 918 DR_Charisma_FahrPr 7;
BA_ "NWM-WakeupAllowed" SG_ 918 DR_Charisma_FahrPr 0;
BA_ "NMH-WakeupAllowed" SG_ 918 DR_Charisma_FahrPr 0;
BA_ "GenSigTimeoutMsg_Gateway_B8" SG_ 918 DR_Charisma_FahrPr 918;
BA_ "GenSigAutoGenDsp" SG_ 918 DR_Charisma_Status 1;
BA_ "GenSigAutoGenSnd" SG_ 918 DR_Charisma_Status 1;
BA_ "GenSigSendType" SG_ 918 DR_Charisma_Status 7;
BA_ "NWM-WakeupAllowed" SG_ 918 DR_Charisma_Status 0;
BA_ "NMH-WakeupAllowed" SG_ 918 DR_Charisma_Status 0;
BA_ "GenSigTimeoutMsg_Gateway_B8" SG_ 918 DR_Charisma_Status 918;
BA_ "GenSigAutoGenDsp" SG_ 918 DR_Charisma_Umschaltung 1;
BA_ "GenSigAutoGenSnd" SG_ 918 DR_Charisma_Umschaltung 1;
BA_ "GenSigSendType" SG_ 918 DR_Charisma_Umschaltung 7;
BA_ "NWM-WakeupAllowed" SG_ 918 DR_Charisma_Umschaltung 0;
BA_ "NMH-WakeupAllowed" SG_ 918 DR_Charisma_Umschaltung 0;
BA_ "GenSigTimeoutMsg_Gateway_B8" SG_ 918 DR_Charisma_Umschaltung 918;
BA_ "GenSigAutoGenDsp" SG_ 918 void_Byte_04 1;
BA_ "GenSigAutoGenSnd" SG_ 918 void_Byte_04 1;
BA_ "GenSigSendType" SG_ 918 void_Byte_04 7;
BA_ "NWM-WakeupAllowed" SG_ 918 void_Byte_04 0;
BA_ "NMH-WakeupAllowed" SG_ 918 void_Byte_04 0;
BA_ "GenSigTimeoutMsg_Gateway_B8" SG_ 918 void_Byte_04 918;
BA_ "GenSigAutoGenDsp" SG_ 918 void_Byte_05 1;
BA_ "GenSigAutoGenSnd" SG_ 918 void_Byte_05 1;
BA_ "GenSigSendType" SG_ 918 void_Byte_05 7;
BA_ "NWM-WakeupAllowed" SG_ 918 void_Byte_05 0;
BA_ "NMH-WakeupAllowed" SG_ 918 void_Byte_05 0;
BA_ "GenSigTimeoutMsg_Gateway_B8" SG_ 918 void_Byte_05 918;
BA_ "GenSigAutoGenDsp" SG_ 918 void_Byte_06 1;
BA_ "GenSigAutoGenSnd" SG_ 918 void_Byte_06 1;
BA_ "GenSigSendType" SG_ 918 void_Byte_06 7;
BA_ "NWM-WakeupAllowed" SG_ 918 void_Byte_06 0;
BA_ "NMH-WakeupAllowed" SG_ 918 void_Byte_06 0;
BA_ "GenSigTimeoutMsg_Gateway_B8" SG_ 918 void_Byte_06 918;
BA_ "GenSigAutoGenDsp" SG_ 918 void_Byte_07 1;
BA_ "GenSigAutoGenSnd" SG_ 918 void_Byte_07 1;
BA_ "GenSigSendType" SG_ 918 void_Byte_07 7;
BA_ "NWM-WakeupAllowed" SG_ 918 void_Byte_07 0;
BA_ "NMH-WakeupAllowed" SG_ 918 void_Byte_07 0;
BA_ "GenSigTimeoutMsg_Gateway_B8" SG_ 918 void_Byte_07 918;
BA_ "GenSigAutoGenDsp" SG_ 918 DR_KD_Fehler 1;
BA_ "GenSigAutoGenSnd" SG_ 918 DR_KD_Fehler 1;
BA_ "GenSigSendType" SG_ 918 DR_KD_Fehler 7;
BA_ "NWM-WakeupAllowed" SG_ 918 DR_KD_Fehler 0;
BA_ "NMH-WakeupAllowed" SG_ 918 DR_KD_Fehler 0;
BA_ "GenSigTimeoutMsg_Gateway_B8" SG_ 918 DR_KD_Fehler 918;
BA_ "GenSigAutoGenDsp" SG_ 1714 DGN_Verlernzaehler 1;
BA_ "GenSigAutoGenSnd" SG_ 1714 DGN_Verlernzaehler 1;
BA_ "GenSigEnvVarType" SG_ 1714 DGN_Verlernzaehler 0;
BA_ "GenSigSendType" SG_ 1714 DGN_Verlernzaehler 7;
BA_ "NWM-WakeupAllowed" SG_ 1714 DGN_Verlernzaehler 0;
BA_ "NMH-WakeupAllowed" SG_ 1714 DGN_Verlernzaehler 0;
BA_ "GenSigTimeoutMsg_AFS_B8" SG_ 1714 DGN_Verlernzaehler 1714;
BA_ "GenSigTimeoutMsg_Airbag_B8" SG_ 1714 DGN_Verlernzaehler 1714;
BA_ "GenSigTimeoutMsg_Daempfer_B8" SG_ 1714 DGN_Verlernzaehler 1714;
BA_ "GenSigTimeoutMsg_LWR_B8" SG_ 1714 DGN_Verlernzaehler 1714;
BA_ "GenSigAutoGenDsp" SG_ 1714 KBI_Kilometerstand 1;
BA_ "GenSigAutoGenSnd" SG_ 1714 KBI_Kilometerstand 1;
BA_ "GenSigEnvVarType" SG_ 1714 KBI_Kilometerstand 0;
BA_ "GenSigSendType" SG_ 1714 KBI_Kilometerstand 7;
BA_ "GenSigStartValue" SG_ 1714 KBI_Kilometerstand 1048574;
BA_ "NWM-WakeupAllowed" SG_ 1714 KBI_Kilometerstand 0;
BA_ "NMH-WakeupAllowed" SG_ 1714 KBI_Kilometerstand 0;
BA_ "GenSigTimeoutMsg_AFS_B8" SG_ 1714 KBI_Kilometerstand 1714;
BA_ "GenSigTimeoutMsg_Airbag_B8" SG_ 1714 KBI_Kilometerstand 1714;
BA_ "GenSigTimeoutMsg_Daempfer_B8" SG_ 1714 KBI_Kilometerstand 1714;
BA_ "GenSigTimeoutMsg_Getriebe_AL6000" SG_ 1714 KBI_Kilometerstand 1714;
BA_ "GenSigTimeoutMsg_Getriebe_DL5001" SG_ 1714 KBI_Kilometerstand 1714;
BA_ "GenSigTimeoutMsg_Getriebe_VL3002" SG_ 1714 KBI_Kilometerstand 1714;
BA_ "GenSigTimeoutMsg_LWR_B8" SG_ 1714 KBI_Kilometerstand 1714;
BA_ "GenSigTimeoutMsg_Motor_EDC17_003" SG_ 1714 KBI_Kilometerstand 1714;
BA_ "GenSigTimeoutMsg_Motor_EDC17_004" SG_ 1714 KBI_Kilometerstand 1714;
BA_ "GenSigTimeoutMsg_Motor_MED17_B8" SG_ 1714 KBI_Kilometerstand 1714;
BA_ "GenSigTimeoutMsg_Motor_MED9_B8" SG_ 1714 KBI_Kilometerstand 1714;
BA_ "GenSigTimeoutMsg_Motor_SIMOS8_B8" SG_ 1714 KBI_Kilometerstand 1714;
BA_ "GenSigAutoGenDsp" SG_ 1714 UH_Jahr 1;
BA_ "GenSigAutoGenSnd" SG_ 1714 UH_Jahr 1;
BA_ "GenSigEnvVarType" SG_ 1714 UH_Jahr 0;
BA_ "GenSigSendType" SG_ 1714 UH_Jahr 7;
BA_ "NWM-WakeupAllowed" SG_ 1714 UH_Jahr 0;
BA_ "NMH-WakeupAllowed" SG_ 1714 UH_Jahr 0;
BA_ "GenSigTimeoutMsg_AFS_B8" SG_ 1714 UH_Jahr 1714;
BA_ "GenSigTimeoutMsg_Airbag_B8" SG_ 1714 UH_Jahr 1714;
BA_ "GenSigTimeoutMsg_Daempfer_B8" SG_ 1714 UH_Jahr 1714;
BA_ "GenSigTimeoutMsg_Getriebe_AL6000" SG_ 1714 UH_Jahr 1714;
BA_ "GenSigTimeoutMsg_Getriebe_DL5001" SG_ 1714 UH_Jahr 1714;
BA_ "GenSigTimeoutMsg_Getriebe_VL3002" SG_ 1714 UH_Jahr 1714;
BA_ "GenSigTimeoutMsg_LWR_B8" SG_ 1714 UH_Jahr 1714;
BA_ "GenSigTimeoutMsg_Motor_EDC17_003" SG_ 1714 UH_Jahr 1714;
BA_ "GenSigTimeoutMsg_Motor_EDC17_004" SG_ 1714 UH_Jahr 1714;
BA_ "GenSigTimeoutMsg_Motor_MED17_B8" SG_ 1714 UH_Jahr 1714;
BA_ "GenSigTimeoutMsg_Motor_MED9_B8" SG_ 1714 UH_Jahr 1714;
BA_ "GenSigTimeoutMsg_Motor_SIMOS8_B8" SG_ 1714 UH_Jahr 1714;
BA_ "GenSigAutoGenDsp" SG_ 1714 UH_Monat 1;
BA_ "GenSigAutoGenSnd" SG_ 1714 UH_Monat 1;
BA_ "GenSigEnvVarType" SG_ 1714 UH_Monat 0;
BA_ "GenSigSendType" SG_ 1714 UH_Monat 7;
BA_ "NWM-WakeupAllowed" SG_ 1714 UH_Monat 0;
BA_ "NMH-WakeupAllowed" SG_ 1714 UH_Monat 0;
BA_ "GenSigTimeoutMsg_AFS_B8" SG_ 1714 UH_Monat 1714;
BA_ "GenSigTimeoutMsg_Airbag_B8" SG_ 1714 UH_Monat 1714;
BA_ "GenSigTimeoutMsg_Daempfer_B8" SG_ 1714 UH_Monat 1714;
BA_ "GenSigTimeoutMsg_Getriebe_AL6000" SG_ 1714 UH_Monat 1714;
BA_ "GenSigTimeoutMsg_Getriebe_DL5001" SG_ 1714 UH_Monat 1714;
BA_ "GenSigTimeoutMsg_Getriebe_VL3002" SG_ 1714 UH_Monat 1714;
BA_ "GenSigTimeoutMsg_LWR_B8" SG_ 1714 UH_Monat 1714;
BA_ "GenSigTimeoutMsg_Motor_EDC17_003" SG_ 1714 UH_Monat 1714;
BA_ "GenSigTimeoutMsg_Motor_EDC17_004" SG_ 1714 UH_Monat 1714;
BA_ "GenSigTimeoutMsg_Motor_MED17_B8" SG_ 1714 UH_Monat 1714;
BA_ "GenSigTimeoutMsg_Motor_MED9_B8" SG_ 1714 UH_Monat 1714;
BA_ "GenSigTimeoutMsg_Motor_SIMOS8_B8" SG_ 1714 UH_Monat 1714;
BA_ "GenSigAutoGenDsp" SG_ 1714 UH_Tag 1;
BA_ "GenSigAutoGenSnd" SG_ 1714 UH_Tag 1;
BA_ "GenSigEnvVarType" SG_ 1714 UH_Tag 0;
BA_ "GenSigSendType" SG_ 1714 UH_Tag 7;
BA_ "NWM-WakeupAllowed" SG_ 1714 UH_Tag 0;
BA_ "NMH-WakeupAllowed" SG_ 1714 UH_Tag 0;
BA_ "GenSigTimeoutMsg_AFS_B8" SG_ 1714 UH_Tag 1714;
BA_ "GenSigTimeoutMsg_Airbag_B8" SG_ 1714 UH_Tag 1714;
BA_ "GenSigTimeoutMsg_Daempfer_B8" SG_ 1714 UH_Tag 1714;
BA_ "GenSigTimeoutMsg_Getriebe_AL6000" SG_ 1714 UH_Tag 1714;
BA_ "GenSigTimeoutMsg_Getriebe_DL5001" SG_ 1714 UH_Tag 1714;
BA_ "GenSigTimeoutMsg_Getriebe_VL3002" SG_ 1714 UH_Tag 1714;
BA_ "GenSigTimeoutMsg_LWR_B8" SG_ 1714 UH_Tag 1714;
BA_ "GenSigTimeoutMsg_Motor_EDC17_003" SG_ 1714 UH_Tag 1714;
BA_ "GenSigTimeoutMsg_Motor_EDC17_004" SG_ 1714 UH_Tag 1714;
BA_ "GenSigTimeoutMsg_Motor_MED17_B8" SG_ 1714 UH_Tag 1714;
BA_ "GenSigTimeoutMsg_Motor_MED9_B8" SG_ 1714 UH_Tag 1714;
BA_ "GenSigTimeoutMsg_Motor_SIMOS8_B8" SG_ 1714 UH_Tag 1714;
BA_ "GenSigAutoGenDsp" SG_ 1714 UH_Stunde 1;
BA_ "GenSigAutoGenSnd" SG_ 1714 UH_Stunde 1;
BA_ "GenSigEnvVarType" SG_ 1714 UH_Stunde 0;
BA_ "GenSigSendType" SG_ 1714 UH_Stunde 7;
BA_ "NWM-WakeupAllowed" SG_ 1714 UH_Stunde 0;
BA_ "NMH-WakeupAllowed" SG_ 1714 UH_Stunde 0;
BA_ "GenSigTimeoutMsg_AFS_B8" SG_ 1714 UH_Stunde 1714;
BA_ "GenSigTimeoutMsg_Airbag_B8" SG_ 1714 UH_Stunde 1714;
BA_ "GenSigTimeoutMsg_Daempfer_B8" SG_ 1714 UH_Stunde 1714;
BA_ "GenSigTimeoutMsg_Getriebe_AL6000" SG_ 1714 UH_Stunde 1714;
BA_ "GenSigTimeoutMsg_Getriebe_DL5001" SG_ 1714 UH_Stunde 1714;
BA_ "GenSigTimeoutMsg_Getriebe_VL3002" SG_ 1714 UH_Stunde 1714;
BA_ "GenSigTimeoutMsg_LWR_B8" SG_ 1714 UH_Stunde 1714;
BA_ "GenSigTimeoutMsg_Motor_EDC17_003" SG_ 1714 UH_Stunde 1714;
BA_ "GenSigTimeoutMsg_Motor_EDC17_004" SG_ 1714 UH_Stunde 1714;
BA_ "GenSigTimeoutMsg_Motor_MED17_B8" SG_ 1714 UH_Stunde 1714;
BA_ "GenSigTimeoutMsg_Motor_MED9_B8" SG_ 1714 UH_Stunde 1714;
BA_ "GenSigTimeoutMsg_Motor_SIMOS8_B8" SG_ 1714 UH_Stunde 1714;
BA_ "GenSigAutoGenDsp" SG_ 1714 UH_Minute 1;
BA_ "GenSigAutoGenSnd" SG_ 1714 UH_Minute 1;
BA_ "GenSigEnvVarType" SG_ 1714 UH_Minute 0;
BA_ "GenSigSendType" SG_ 1714 UH_Minute 7;
BA_ "NWM-WakeupAllowed" SG_ 1714 UH_Minute 0;
BA_ "NMH-WakeupAllowed" SG_ 1714 UH_Minute 0;
BA_ "GenSigTimeoutMsg_AFS_B8" SG_ 1714 UH_Minute 1714;
BA_ "GenSigTimeoutMsg_Airbag_B8" SG_ 1714 UH_Minute 1714;
BA_ "GenSigTimeoutMsg_Daempfer_B8" SG_ 1714 UH_Minute 1714;
BA_ "GenSigTimeoutMsg_Getriebe_AL6000" SG_ 1714 UH_Minute 1714;
BA_ "GenSigTimeoutMsg_Getriebe_DL5001" SG_ 1714 UH_Minute 1714;
BA_ "GenSigTimeoutMsg_Getriebe_VL3002" SG_ 1714 UH_Minute 1714;
BA_ "GenSigTimeoutMsg_LWR_B8" SG_ 1714 UH_Minute 1714;
BA_ "GenSigTimeoutMsg_Motor_EDC17_003" SG_ 1714 UH_Minute 1714;
BA_ "GenSigTimeoutMsg_Motor_EDC17_004" SG_ 1714 UH_Minute 1714;
BA_ "GenSigTimeoutMsg_Motor_MED17_B8" SG_ 1714 UH_Minute 1714;
BA_ "GenSigTimeoutMsg_Motor_MED9_B8" SG_ 1714 UH_Minute 1714;
BA_ "GenSigTimeoutMsg_Motor_SIMOS8_B8" SG_ 1714 UH_Minute 1714;
BA_ "GenSigAutoGenDsp" SG_ 1714 UH_Sekunde 1;
BA_ "GenSigAutoGenSnd" SG_ 1714 UH_Sekunde 1;
BA_ "GenSigEnvVarType" SG_ 1714 UH_Sekunde 0;
BA_ "GenSigSendType" SG_ 1714 UH_Sekunde 7;
BA_ "NWM-WakeupAllowed" SG_ 1714 UH_Sekunde 0;
BA_ "NMH-WakeupAllowed" SG_ 1714 UH_Sekunde 0;
BA_ "GenSigTimeoutMsg_AFS_B8" SG_ 1714 UH_Sekunde 1714;
BA_ "GenSigTimeoutMsg_Airbag_B8" SG_ 1714 UH_Sekunde 1714;
BA_ "GenSigTimeoutMsg_Daempfer_B8" SG_ 1714 UH_Sekunde 1714;
BA_ "GenSigTimeoutMsg_Getriebe_AL6000" SG_ 1714 UH_Sekunde 1714;
BA_ "GenSigTimeoutMsg_Getriebe_DL5001" SG_ 1714 UH_Sekunde 1714;
BA_ "GenSigTimeoutMsg_Getriebe_VL3002" SG_ 1714 UH_Sekunde 1714;
BA_ "GenSigTimeoutMsg_LWR_B8" SG_ 1714 UH_Sekunde 1714;
BA_ "GenSigTimeoutMsg_Motor_EDC17_003" SG_ 1714 UH_Sekunde 1714;
BA_ "GenSigTimeoutMsg_Motor_EDC17_004" SG_ 1714 UH_Sekunde 1714;
BA_ "GenSigTimeoutMsg_Motor_MED17_B8" SG_ 1714 UH_Sekunde 1714;
BA_ "GenSigTimeoutMsg_Motor_MED9_B8" SG_ 1714 UH_Sekunde 1714;
BA_ "GenSigTimeoutMsg_Motor_SIMOS8_B8" SG_ 1714 UH_Sekunde 1714;
BA_ "GenSigAutoGenDsp" SG_ 1714 Kombi_02_alt 1;
BA_ "GenSigAutoGenSnd" SG_ 1714 Kombi_02_alt 1;
BA_ "GenSigEnvVarType" SG_ 1714 Kombi_02_alt 0;
BA_ "GenSigSendType" SG_ 1714 Kombi_02_alt 7;
BA_ "GenSigStartValue" SG_ 1714 Kombi_02_alt 1;
BA_ "NWM-WakeupAllowed" SG_ 1714 Kombi_02_alt 0;
BA_ "NMH-WakeupAllowed" SG_ 1714 Kombi_02_alt 0;
BA_ "GenSigTimeoutMsg_AFS_B8" SG_ 1714 Kombi_02_alt 1714;
BA_ "GenSigTimeoutMsg_Airbag_B8" SG_ 1714 Kombi_02_alt 1714;
BA_ "GenSigTimeoutMsg_Getriebe_AL6000" SG_ 1714 Kombi_02_alt 1714;
BA_ "GenSigTimeoutMsg_Getriebe_DL5001" SG_ 1714 Kombi_02_alt 1714;
BA_ "GenSigTimeoutMsg_Getriebe_VL3002" SG_ 1714 Kombi_02_alt 1714;
BA_ "GenSigTimeoutMsg_LWR_B8" SG_ 1714 Kombi_02_alt 1714;
BA_ "GenSigTimeoutMsg_Motor_EDC17_003" SG_ 1714 Kombi_02_alt 1714;
BA_ "GenSigTimeoutMsg_Motor_EDC17_004" SG_ 1714 Kombi_02_alt 1714;
BA_ "GenSigTimeoutMsg_Motor_MED17_B8" SG_ 1714 Kombi_02_alt 1714;
BA_ "GenSigTimeoutMsg_Motor_MED9_B8" SG_ 1714 Kombi_02_alt 1714;
BA_ "GenSigTimeoutMsg_Motor_SIMOS8_B8" SG_ 1714 Kombi_02_alt 1714;
BA_ "GenSigAutoGenDsp" SG_ 1714 Uhrzeit_01_alt 1;
BA_ "GenSigAutoGenSnd" SG_ 1714 Uhrzeit_01_alt 1;
BA_ "GenSigEnvVarType" SG_ 1714 Uhrzeit_01_alt 0;
BA_ "GenSigSendType" SG_ 1714 Uhrzeit_01_alt 7;
BA_ "GenSigStartValue" SG_ 1714 Uhrzeit_01_alt 1;
BA_ "NWM-WakeupAllowed" SG_ 1714 Uhrzeit_01_alt 0;
BA_ "NMH-WakeupAllowed" SG_ 1714 Uhrzeit_01_alt 0;
BA_ "GenSigTimeoutMsg_AFS_B8" SG_ 1714 Uhrzeit_01_alt 1714;
BA_ "GenSigTimeoutMsg_Airbag_B8" SG_ 1714 Uhrzeit_01_alt 1714;
BA_ "GenSigTimeoutMsg_Getriebe_AL6000" SG_ 1714 Uhrzeit_01_alt 1714;
BA_ "GenSigTimeoutMsg_Getriebe_DL5001" SG_ 1714 Uhrzeit_01_alt 1714;
BA_ "GenSigTimeoutMsg_Getriebe_VL3002" SG_ 1714 Uhrzeit_01_alt 1714;
BA_ "GenSigTimeoutMsg_LWR_B8" SG_ 1714 Uhrzeit_01_alt 1714;
BA_ "GenSigTimeoutMsg_Motor_EDC17_003" SG_ 1714 Uhrzeit_01_alt 1714;
BA_ "GenSigTimeoutMsg_Motor_EDC17_004" SG_ 1714 Uhrzeit_01_alt 1714;
BA_ "GenSigTimeoutMsg_Motor_MED17_B8" SG_ 1714 Uhrzeit_01_alt 1714;
BA_ "GenSigTimeoutMsg_Motor_MED9_B8" SG_ 1714 Uhrzeit_01_alt 1714;
BA_ "GenSigTimeoutMsg_Motor_SIMOS8_B8" SG_ 1714 Uhrzeit_01_alt 1714;
BA_ "GenSigAutoGenDsp" SG_ 1520 DI_KL_58d 1;
BA_ "GenSigAutoGenSnd" SG_ 1520 DI_KL_58d 1;
BA_ "GenSigEnvVarType" SG_ 1520 DI_KL_58d 0;
BA_ "GenSigSendType" SG_ 1520 DI_KL_58d 7;
BA_ "GenSigStartValue" SG_ 1520 DI_KL_58d 254;
BA_ "NWM-WakeupAllowed" SG_ 1520 DI_KL_58d 0;
BA_ "NMH-WakeupAllowed" SG_ 1520 DI_KL_58d 0;
BA_ "GenSigTimeoutMsg_Airbag_B8" SG_ 1520 DI_KL_58d 1520;
BA_ "GenSigAutoGenDsp" SG_ 1520 DI_KL_58s 1;
BA_ "GenSigAutoGenSnd" SG_ 1520 DI_KL_58s 1;
BA_ "GenSigEnvVarType" SG_ 1520 DI_KL_58s 0;
BA_ "GenSigSendType" SG_ 1520 DI_KL_58s 7;
BA_ "GenSigStartValue" SG_ 1520 DI_KL_58s 126;
BA_ "NWM-WakeupAllowed" SG_ 1520 DI_KL_58s 0;
BA_ "NMH-WakeupAllowed" SG_ 1520 DI_KL_58s 0;
BA_ "GenSigAutoGenDsp" SG_ 1520 DI_KL_58st 1;
BA_ "GenSigAutoGenSnd" SG_ 1520 DI_KL_58st 1;
BA_ "GenSigEnvVarType" SG_ 1520 DI_KL_58st 0;
BA_ "GenSigSendType" SG_ 1520 DI_KL_58st 7;
BA_ "GenSigStartValue" SG_ 1520 DI_KL_58st 126;
BA_ "NWM-WakeupAllowed" SG_ 1520 DI_KL_58st 0;
BA_ "NMH-WakeupAllowed" SG_ 1520 DI_KL_58st 0;
BA_ "GenSigAutoGenDsp" SG_ 1520 DI_Lichtsensorwert 1;
BA_ "GenSigAutoGenSnd" SG_ 1520 DI_Lichtsensorwert 1;
BA_ "GenSigEnvVarType" SG_ 1520 DI_Lichtsensorwert 0;
BA_ "GenSigSendType" SG_ 1520 DI_Lichtsensorwert 7;
BA_ "NWM-WakeupAllowed" SG_ 1520 DI_Lichtsensorwert 0;
BA_ "NMH-WakeupAllowed" SG_ 1520 DI_Lichtsensorwert 0;
BA_ "GenSigAutoGenDsp" SG_ 260 EPB_01_CHK 1;
BA_ "GenSigAutoGenSnd" SG_ 260 EPB_01_CHK 1;
BA_ "GenSigEnvVarType" SG_ 260 EPB_01_CHK 0;
BA_ "GenSigSendType" SG_ 260 EPB_01_CHK 7;
BA_ "NWM-WakeupAllowed" SG_ 260 EPB_01_CHK 0;
BA_ "NMH-WakeupAllowed" SG_ 260 EPB_01_CHK 0;
BA_ "GenSigTimeoutMsg_Daempfer_B8" SG_ 260 EPB_01_CHK 260;
BA_ "GenSigTimeoutMsg_Getriebe_AL6000" SG_ 260 EPB_01_CHK 260;
BA_ "GenSigTimeoutMsg_Getriebe_DL5001" SG_ 260 EPB_01_CHK 260;
BA_ "GenSigTimeoutMsg_Getriebe_VL3002" SG_ 260 EPB_01_CHK 260;
BA_ "GenSigTimeoutMsg_Motor_EDC17_003" SG_ 260 EPB_01_CHK 260;
BA_ "GenSigTimeoutMsg_Motor_EDC17_004" SG_ 260 EPB_01_CHK 260;
BA_ "GenSigTimeoutMsg_Motor_MED17_B8" SG_ 260 EPB_01_CHK 260;
BA_ "GenSigTimeoutMsg_Motor_MED9_B8" SG_ 260 EPB_01_CHK 260;
BA_ "GenSigTimeoutMsg_Motor_SIMOS8_B8" SG_ 260 EPB_01_CHK 260;
BA_ "GenSigAutoGenDsp" SG_ 260 EPB_01_BZ 1;
BA_ "GenSigAutoGenSnd" SG_ 260 EPB_01_BZ 1;
BA_ "GenSigEnvVarType" SG_ 260 EPB_01_BZ 0;
BA_ "GenSigSendType" SG_ 260 EPB_01_BZ 7;
BA_ "NWM-WakeupAllowed" SG_ 260 EPB_01_BZ 0;
BA_ "NMH-WakeupAllowed" SG_ 260 EPB_01_BZ 0;
BA_ "GenSigTimeoutMsg_Daempfer_B8" SG_ 260 EPB_01_BZ 260;
BA_ "GenSigTimeoutMsg_Getriebe_AL6000" SG_ 260 EPB_01_BZ 260;
BA_ "GenSigTimeoutMsg_Getriebe_DL5001" SG_ 260 EPB_01_BZ 260;
BA_ "GenSigTimeoutMsg_Getriebe_VL3002" SG_ 260 EPB_01_BZ 260;
BA_ "GenSigTimeoutMsg_Motor_EDC17_003" SG_ 260 EPB_01_BZ 260;
BA_ "GenSigTimeoutMsg_Motor_EDC17_004" SG_ 260 EPB_01_BZ 260;
BA_ "GenSigTimeoutMsg_Motor_MED17_B8" SG_ 260 EPB_01_BZ 260;
BA_ "GenSigTimeoutMsg_Motor_MED9_B8" SG_ 260 EPB_01_BZ 260;
BA_ "GenSigTimeoutMsg_Motor_SIMOS8_B8" SG_ 260 EPB_01_BZ 260;
BA_ "GenSigAutoGenDsp" SG_ 260 EPB_QBit_Laengsbeschleunigung 1;
BA_ "GenSigAutoGenSnd" SG_ 260 EPB_QBit_Laengsbeschleunigung 1;
BA_ "GenSigEnvVarType" SG_ 260 EPB_QBit_Laengsbeschleunigung 0;
BA_ "GenSigSendType" SG_ 260 EPB_QBit_Laengsbeschleunigung 7;
BA_ "GenSigStartValue" SG_ 260 EPB_QBit_Laengsbeschleunigung 1;
BA_ "NWM-WakeupAllowed" SG_ 260 EPB_QBit_Laengsbeschleunigung 0;
BA_ "NMH-WakeupAllowed" SG_ 260 EPB_QBit_Laengsbeschleunigung 0;
BA_ "GenSigTimeoutMsg_Getriebe_AL6000" SG_ 260 EPB_QBit_Laengsbeschleunigung 260;
BA_ "GenSigTimeoutMsg_Getriebe_DL5001" SG_ 260 EPB_QBit_Laengsbeschleunigung 260;
BA_ "GenSigTimeoutMsg_Getriebe_VL3002" SG_ 260 EPB_QBit_Laengsbeschleunigung 260;
BA_ "GenSigTimeoutMsg_Motor_EDC17_003" SG_ 260 EPB_QBit_Laengsbeschleunigung 260;
BA_ "GenSigTimeoutMsg_Motor_EDC17_004" SG_ 260 EPB_QBit_Laengsbeschleunigung 260;
BA_ "GenSigTimeoutMsg_Motor_MED17_B8" SG_ 260 EPB_QBit_Laengsbeschleunigung 260;
BA_ "GenSigTimeoutMsg_Motor_MED9_B8" SG_ 260 EPB_QBit_Laengsbeschleunigung 260;
BA_ "GenSigTimeoutMsg_Motor_SIMOS8_B8" SG_ 260 EPB_QBit_Laengsbeschleunigung 260;
BA_ "GenSigAutoGenDsp" SG_ 260 EPB_QBit_Pedalweg_Kuppl 1;
BA_ "GenSigAutoGenSnd" SG_ 260 EPB_QBit_Pedalweg_Kuppl 1;
BA_ "GenSigEnvVarType" SG_ 260 EPB_QBit_Pedalweg_Kuppl 0;
BA_ "GenSigSendType" SG_ 260 EPB_QBit_Pedalweg_Kuppl 7;
BA_ "GenSigStartValue" SG_ 260 EPB_QBit_Pedalweg_Kuppl 1;
BA_ "NWM-WakeupAllowed" SG_ 260 EPB_QBit_Pedalweg_Kuppl 0;
BA_ "NMH-WakeupAllowed" SG_ 260 EPB_QBit_Pedalweg_Kuppl 0;
BA_ "GenSigTimeoutMsg_Motor_EDC17_003" SG_ 260 EPB_QBit_Pedalweg_Kuppl 260;
BA_ "GenSigTimeoutMsg_Motor_EDC17_004" SG_ 260 EPB_QBit_Pedalweg_Kuppl 260;
BA_ "GenSigTimeoutMsg_Motor_MED17_B8" SG_ 260 EPB_QBit_Pedalweg_Kuppl 260;
BA_ "GenSigTimeoutMsg_Motor_MED9_B8" SG_ 260 EPB_QBit_Pedalweg_Kuppl 260;
BA_ "GenSigTimeoutMsg_Motor_SIMOS8_B8" SG_ 260 EPB_QBit_Pedalweg_Kuppl 260;
BA_ "GenSigAutoGenDsp" SG_ 260 EPB_BCM2_Motor_Wakeup 1;
BA_ "GenSigAutoGenSnd" SG_ 260 EPB_BCM2_Motor_Wakeup 1;
BA_ "GenSigEnvVarType" SG_ 260 EPB_BCM2_Motor_Wakeup 0;
BA_ "GenSigSendType" SG_ 260 EPB_BCM2_Motor_Wakeup 7;
BA_ "NWM-WakeupAllowed" SG_ 260 EPB_BCM2_Motor_Wakeup 0;
BA_ "NMH-WakeupAllowed" SG_ 260 EPB_BCM2_Motor_Wakeup 0;
BA_ "GenSigAutoGenDsp" SG_ 260 EPB_Freig_Verzoeg_Anf 1;
BA_ "GenSigAutoGenSnd" SG_ 260 EPB_Freig_Verzoeg_Anf 1;
BA_ "GenSigEnvVarType" SG_ 260 EPB_Freig_Verzoeg_Anf 0;
BA_ "GenSigSendType" SG_ 260 EPB_Freig_Verzoeg_Anf 7;
BA_ "NWM-WakeupAllowed" SG_ 260 EPB_Freig_Verzoeg_Anf 0;
BA_ "NMH-WakeupAllowed" SG_ 260 EPB_Freig_Verzoeg_Anf 0;
BA_ "GenSigTimeoutMsg_Daempfer_B8" SG_ 260 EPB_Freig_Verzoeg_Anf 260;
BA_ "GenSigTimeoutMsg_Getriebe_AL6000" SG_ 260 EPB_Freig_Verzoeg_Anf 260;
BA_ "GenSigTimeoutMsg_Motor_EDC17_003" SG_ 260 EPB_Freig_Verzoeg_Anf 260;
BA_ "GenSigTimeoutMsg_Motor_EDC17_004" SG_ 260 EPB_Freig_Verzoeg_Anf 260;
BA_ "GenSigTimeoutMsg_Motor_MED17_B8" SG_ 260 EPB_Freig_Verzoeg_Anf 260;
BA_ "GenSigTimeoutMsg_Motor_MED9_B8" SG_ 260 EPB_Freig_Verzoeg_Anf 260;
BA_ "GenSigTimeoutMsg_Motor_SIMOS8_B8" SG_ 260 EPB_Freig_Verzoeg_Anf 260;
BA_ "GenSigAutoGenDsp" SG_ 260 EPB_Verzoeg_Anf 1;
BA_ "GenSigAutoGenSnd" SG_ 260 EPB_Verzoeg_Anf 1;
BA_ "GenSigEnvVarType" SG_ 260 EPB_Verzoeg_Anf 1;
BA_ "GenSigSendType" SG_ 260 EPB_Verzoeg_Anf 7;
BA_ "GenSigStartValue" SG_ 260 EPB_Verzoeg_Anf 166;
BA_ "NWM-WakeupAllowed" SG_ 260 EPB_Verzoeg_Anf 0;
BA_ "NMH-WakeupAllowed" SG_ 260 EPB_Verzoeg_Anf 0;
BA_ "GenSigTimeoutMsg_Daempfer_B8" SG_ 260 EPB_Verzoeg_Anf 260;
BA_ "GenSigAutoGenDsp" SG_ 260 EPB_Laengsbeschleunigung 1;
BA_ "GenSigAutoGenSnd" SG_ 260 EPB_Laengsbeschleunigung 1;
BA_ "GenSigEnvVarType" SG_ 260 EPB_Laengsbeschleunigung 1;
BA_ "GenSigSendType" SG_ 260 EPB_Laengsbeschleunigung 7;
BA_ "NWM-WakeupAllowed" SG_ 260 EPB_Laengsbeschleunigung 0;
BA_ "NMH-WakeupAllowed" SG_ 260 EPB_Laengsbeschleunigung 0;
BA_ "GenSigTimeoutMsg_Getriebe_AL6000" SG_ 260 EPB_Laengsbeschleunigung 260;
BA_ "GenSigTimeoutMsg_Getriebe_DL5001" SG_ 260 EPB_Laengsbeschleunigung 260;
BA_ "GenSigTimeoutMsg_Getriebe_VL3002" SG_ 260 EPB_Laengsbeschleunigung 260;
BA_ "GenSigTimeoutMsg_Motor_EDC17_003" SG_ 260 EPB_Laengsbeschleunigung 260;
BA_ "GenSigTimeoutMsg_Motor_EDC17_004" SG_ 260 EPB_Laengsbeschleunigung 260;
BA_ "GenSigTimeoutMsg_Motor_MED17_B8" SG_ 260 EPB_Laengsbeschleunigung 260;
BA_ "GenSigTimeoutMsg_Motor_MED9_B8" SG_ 260 EPB_Laengsbeschleunigung 260;
BA_ "GenSigTimeoutMsg_Motor_SIMOS8_B8" SG_ 260 EPB_Laengsbeschleunigung 260;
BA_ "GenSigAutoGenDsp" SG_ 260 EPB_Pedalweg_Kuppl 1;
BA_ "GenSigAutoGenSnd" SG_ 260 EPB_Pedalweg_Kuppl 1;
BA_ "GenSigEnvVarType" SG_ 260 EPB_Pedalweg_Kuppl 1;
BA_ "GenSigSendType" SG_ 260 EPB_Pedalweg_Kuppl 7;
BA_ "NWM-WakeupAllowed" SG_ 260 EPB_Pedalweg_Kuppl 0;
BA_ "NMH-WakeupAllowed" SG_ 260 EPB_Pedalweg_Kuppl 0;
BA_ "GenSigTimeoutMsg_Motor_EDC17_003" SG_ 260 EPB_Pedalweg_Kuppl 260;
BA_ "GenSigTimeoutMsg_Motor_EDC17_004" SG_ 260 EPB_Pedalweg_Kuppl 260;
BA_ "GenSigTimeoutMsg_Motor_MED17_B8" SG_ 260 EPB_Pedalweg_Kuppl 260;
BA_ "GenSigTimeoutMsg_Motor_MED9_B8" SG_ 260 EPB_Pedalweg_Kuppl 260;
BA_ "GenSigTimeoutMsg_Motor_SIMOS8_B8" SG_ 260 EPB_Pedalweg_Kuppl 260;
BA_ "GenSigAutoGenDsp" SG_ 260 EPB_Fehlerstatus 1;
BA_ "GenSigAutoGenSnd" SG_ 260 EPB_Fehlerstatus 1;
BA_ "GenSigEnvVarType" SG_ 260 EPB_Fehlerstatus 0;
BA_ "GenSigSendType" SG_ 260 EPB_Fehlerstatus 7;
BA_ "NWM-WakeupAllowed" SG_ 260 EPB_Fehlerstatus 0;
BA_ "NMH-WakeupAllowed" SG_ 260 EPB_Fehlerstatus 0;
BA_ "GenSigAutoGenDsp" SG_ 260 EPB_Schalterposition 1;
BA_ "GenSigAutoGenSnd" SG_ 260 EPB_Schalterposition 1;
BA_ "GenSigEnvVarType" SG_ 260 EPB_Schalterposition 0;
BA_ "GenSigSendType" SG_ 260 EPB_Schalterposition 7;
BA_ "NWM-WakeupAllowed" SG_ 260 EPB_Schalterposition 0;
BA_ "NMH-WakeupAllowed" SG_ 260 EPB_Schalterposition 0;
BA_ "GenSigTimeoutMsg_Getriebe_AL6000" SG_ 260 EPB_Schalterposition 260;
BA_ "GenSigTimeoutMsg_Motor_EDC17_003" SG_ 260 EPB_Schalterposition 260;
BA_ "GenSigTimeoutMsg_Motor_EDC17_004" SG_ 260 EPB_Schalterposition 260;
BA_ "GenSigTimeoutMsg_Motor_MED17_B8" SG_ 260 EPB_Schalterposition 260;
BA_ "GenSigTimeoutMsg_Motor_MED9_B8" SG_ 260 EPB_Schalterposition 260;
BA_ "GenSigTimeoutMsg_Motor_SIMOS8_B8" SG_ 260 EPB_Schalterposition 260;
BA_ "GenSigAutoGenDsp" SG_ 260 EPB_QBit_Schalterpos 1;
BA_ "GenSigAutoGenSnd" SG_ 260 EPB_QBit_Schalterpos 1;
BA_ "GenSigEnvVarType" SG_ 260 EPB_QBit_Schalterpos 0;
BA_ "GenSigSendType" SG_ 260 EPB_QBit_Schalterpos 7;
BA_ "GenSigStartValue" SG_ 260 EPB_QBit_Schalterpos 1;
BA_ "NWM-WakeupAllowed" SG_ 260 EPB_QBit_Schalterpos 0;
BA_ "NMH-WakeupAllowed" SG_ 260 EPB_QBit_Schalterpos 0;
BA_ "GenSigTimeoutMsg_Getriebe_AL6000" SG_ 260 EPB_QBit_Schalterpos 260;
BA_ "GenSigTimeoutMsg_Motor_EDC17_003" SG_ 260 EPB_QBit_Schalterpos 260;
BA_ "GenSigTimeoutMsg_Motor_EDC17_004" SG_ 260 EPB_QBit_Schalterpos 260;
BA_ "GenSigTimeoutMsg_Motor_MED17_B8" SG_ 260 EPB_QBit_Schalterpos 260;
BA_ "GenSigTimeoutMsg_Motor_MED9_B8" SG_ 260 EPB_QBit_Schalterpos 260;
BA_ "GenSigTimeoutMsg_Motor_SIMOS8_B8" SG_ 260 EPB_QBit_Schalterpos 260;
BA_ "GenSigAutoGenDsp" SG_ 260 EPB_Spannkraft 1;
BA_ "GenSigAutoGenSnd" SG_ 260 EPB_Spannkraft 1;
BA_ "GenSigEnvVarType" SG_ 260 EPB_Spannkraft 0;
BA_ "GenSigSendType" SG_ 260 EPB_Spannkraft 7;
BA_ "GenSigStartValue" SG_ 260 EPB_Spannkraft 30;
BA_ "NWM-WakeupAllowed" SG_ 260 EPB_Spannkraft 0;
BA_ "NMH-WakeupAllowed" SG_ 260 EPB_Spannkraft 0;
BA_ "GenSigTimeoutMsg_Getriebe_AL6000" SG_ 260 EPB_Spannkraft 260;
BA_ "GenSigAutoGenDsp" SG_ 260 EPB_Status 1;
BA_ "GenSigAutoGenSnd" SG_ 260 EPB_Status 1;
BA_ "GenSigEnvVarType" SG_ 260 EPB_Status 0;
BA_ "GenSigSendType" SG_ 260 EPB_Status 7;
BA_ "NWM-WakeupAllowed" SG_ 260 EPB_Status 0;
BA_ "NMH-WakeupAllowed" SG_ 260 EPB_Status 0;
BA_ "GenSigTimeoutMsg_Getriebe_AL6000" SG_ 260 EPB_Status 260;
BA_ "GenSigTimeoutMsg_Motor_EDC17_003" SG_ 260 EPB_Status 260;
BA_ "GenSigTimeoutMsg_Motor_EDC17_004" SG_ 260 EPB_Status 260;
BA_ "GenSigTimeoutMsg_Motor_MED17_B8" SG_ 260 EPB_Status 260;
BA_ "GenSigTimeoutMsg_Motor_MED9_B8" SG_ 260 EPB_Status 260;
BA_ "GenSigTimeoutMsg_Motor_SIMOS8_B8" SG_ 260 EPB_Status 260;
BA_ "GenSigAutoGenDsp" SG_ 260 EPB_KD_Fehler 1;
BA_ "GenSigAutoGenSnd" SG_ 260 EPB_KD_Fehler 1;
BA_ "GenSigEnvVarType" SG_ 260 EPB_KD_Fehler 0;
BA_ "GenSigSendType" SG_ 260 EPB_KD_Fehler 7;
BA_ "NWM-WakeupAllowed" SG_ 260 EPB_KD_Fehler 0;
BA_ "NMH-WakeupAllowed" SG_ 260 EPB_KD_Fehler 0;
BA_ "GenSigAutoGenDsp" SG_ 256 ESP_01_CHK 1;
BA_ "GenSigAutoGenSnd" SG_ 256 ESP_01_CHK 1;
BA_ "GenSigEnvVarType" SG_ 256 ESP_01_CHK 0;
BA_ "GenSigSendType" SG_ 256 ESP_01_CHK 7;
BA_ "NWM-WakeupAllowed" SG_ 256 ESP_01_CHK 0;
BA_ "NMH-WakeupAllowed" SG_ 256 ESP_01_CHK 0;
BA_ "GenSigTimeoutMsg_Airbag_B8" SG_ 256 ESP_01_CHK 256;
BA_ "GenSigTimeoutMsg_Daempfer_B8" SG_ 256 ESP_01_CHK 256;
BA_ "GenSigTimeoutMsg_Getriebe_AL6000" SG_ 256 ESP_01_CHK 256;
BA_ "GenSigTimeoutMsg_Getriebe_DL5001" SG_ 256 ESP_01_CHK 256;
BA_ "GenSigTimeoutMsg_Getriebe_VL3002" SG_ 256 ESP_01_CHK 256;
BA_ "GenSigTimeoutMsg_Motor_EDC17_003" SG_ 256 ESP_01_CHK 256;
BA_ "GenSigTimeoutMsg_Motor_EDC17_004" SG_ 256 ESP_01_CHK 256;
BA_ "GenSigTimeoutMsg_Motor_MED17_B8" SG_ 256 ESP_01_CHK 256;
BA_ "GenSigTimeoutMsg_Motor_MED9_B8" SG_ 256 ESP_01_CHK 256;
BA_ "GenSigTimeoutMsg_Motor_SIMOS8_B8" SG_ 256 ESP_01_CHK 256;
BA_ "GenSigAutoGenDsp" SG_ 256 ESP_01_BZ 1;
BA_ "GenSigAutoGenSnd" SG_ 256 ESP_01_BZ 1;
BA_ "GenSigEnvVarType" SG_ 256 ESP_01_BZ 0;
BA_ "GenSigSendType" SG_ 256 ESP_01_BZ 7;
BA_ "NWM-WakeupAllowed" SG_ 256 ESP_01_BZ 0;
BA_ "NMH-WakeupAllowed" SG_ 256 ESP_01_BZ 0;
BA_ "GenSigTimeoutMsg_Airbag_B8" SG_ 256 ESP_01_BZ 256;
BA_ "GenSigTimeoutMsg_Daempfer_B8" SG_ 256 ESP_01_BZ 256;
BA_ "GenSigTimeoutMsg_Getriebe_AL6000" SG_ 256 ESP_01_BZ 256;
BA_ "GenSigTimeoutMsg_Getriebe_DL5001" SG_ 256 ESP_01_BZ 256;
BA_ "GenSigTimeoutMsg_Getriebe_VL3002" SG_ 256 ESP_01_BZ 256;
BA_ "GenSigTimeoutMsg_Motor_EDC17_003" SG_ 256 ESP_01_BZ 256;
BA_ "GenSigTimeoutMsg_Motor_EDC17_004" SG_ 256 ESP_01_BZ 256;
BA_ "GenSigTimeoutMsg_Motor_MED17_B8" SG_ 256 ESP_01_BZ 256;
BA_ "GenSigTimeoutMsg_Motor_MED9_B8" SG_ 256 ESP_01_BZ 256;
BA_ "GenSigTimeoutMsg_Motor_SIMOS8_B8" SG_ 256 ESP_01_BZ 256;
BA_ "GenSigAutoGenDsp" SG_ 256 ASR_Moment_langsam 1;
BA_ "GenSigAutoGenSnd" SG_ 256 ASR_Moment_langsam 1;
BA_ "GenSigEnvVarType" SG_ 256 ASR_Moment_langsam 1;
BA_ "GenSigSendType" SG_ 256 ASR_Moment_langsam 7;
BA_ "GenSigStartValue" SG_ 256 ASR_Moment_langsam 1022;
BA_ "NWM-WakeupAllowed" SG_ 256 ASR_Moment_langsam 0;
BA_ "NMH-WakeupAllowed" SG_ 256 ASR_Moment_langsam 0;
BA_ "GenSigTimeoutMsg_Airbag_B8" SG_ 256 ASR_Moment_langsam 256;
BA_ "GenSigTimeoutMsg_Getriebe_AL6000" SG_ 256 ASR_Moment_langsam 256;
BA_ "GenSigTimeoutMsg_Getriebe_DL5001" SG_ 256 ASR_Moment_langsam 256;
BA_ "GenSigTimeoutMsg_Motor_EDC17_003" SG_ 256 ASR_Moment_langsam 256;
BA_ "GenSigTimeoutMsg_Motor_EDC17_004" SG_ 256 ASR_Moment_langsam 256;
BA_ "GenSigTimeoutMsg_Motor_MED17_B8" SG_ 256 ASR_Moment_langsam 256;
BA_ "GenSigTimeoutMsg_Motor_MED9_B8" SG_ 256 ASR_Moment_langsam 256;
BA_ "GenSigTimeoutMsg_Motor_SIMOS8_B8" SG_ 256 ASR_Moment_langsam 256;
BA_ "GenSigAutoGenDsp" SG_ 256 ASR_MSR_Moment_schnell 1;
BA_ "GenSigAutoGenSnd" SG_ 256 ASR_MSR_Moment_schnell 1;
BA_ "GenSigEnvVarType" SG_ 256 ASR_MSR_Moment_schnell 1;
BA_ "GenSigSendType" SG_ 256 ASR_MSR_Moment_schnell 7;
BA_ "GenSigStartValue" SG_ 256 ASR_MSR_Moment_schnell 1022;
BA_ "NWM-WakeupAllowed" SG_ 256 ASR_MSR_Moment_schnell 0;
BA_ "NMH-WakeupAllowed" SG_ 256 ASR_MSR_Moment_schnell 0;
BA_ "GenSigTimeoutMsg_Airbag_B8" SG_ 256 ASR_MSR_Moment_schnell 256;
BA_ "GenSigTimeoutMsg_Getriebe_AL6000" SG_ 256 ASR_MSR_Moment_schnell 256;
BA_ "GenSigTimeoutMsg_Getriebe_DL5001" SG_ 256 ASR_MSR_Moment_schnell 256;
BA_ "GenSigTimeoutMsg_Motor_EDC17_003" SG_ 256 ASR_MSR_Moment_schnell 256;
BA_ "GenSigTimeoutMsg_Motor_EDC17_004" SG_ 256 ASR_MSR_Moment_schnell 256;
BA_ "GenSigTimeoutMsg_Motor_MED17_B8" SG_ 256 ASR_MSR_Moment_schnell 256;
BA_ "GenSigTimeoutMsg_Motor_MED9_B8" SG_ 256 ASR_MSR_Moment_schnell 256;
BA_ "GenSigTimeoutMsg_Motor_SIMOS8_B8" SG_ 256 ASR_MSR_Moment_schnell 256;
BA_ "GenSigAutoGenDsp" SG_ 256 ESP_v_Signal 1;
BA_ "GenSigAutoGenSnd" SG_ 256 ESP_v_Signal 1;
BA_ "GenSigEnvVarType" SG_ 256 ESP_v_Signal 1;
BA_ "GenSigSendType" SG_ 256 ESP_v_Signal 7;
BA_ "GenSigStartValue" SG_ 256 ESP_v_Signal 65534;
BA_ "NWM-WakeupAllowed" SG_ 256 ESP_v_Signal 0;
BA_ "NMH-WakeupAllowed" SG_ 256 ESP_v_Signal 0;
BA_ "GenSigTimeoutMsg_Airbag_B8" SG_ 256 ESP_v_Signal 256;
BA_ "GenSigTimeoutMsg_Daempfer_B8" SG_ 256 ESP_v_Signal 256;
BA_ "GenSigTimeoutMsg_Getriebe_AL6000" SG_ 256 ESP_v_Signal 256;
BA_ "GenSigTimeoutMsg_Getriebe_DL5001" SG_ 256 ESP_v_Signal 256;
BA_ "GenSigTimeoutMsg_Motor_EDC17_003" SG_ 256 ESP_v_Signal 256;
BA_ "GenSigTimeoutMsg_Motor_EDC17_004" SG_ 256 ESP_v_Signal 256;
BA_ "GenSigTimeoutMsg_Motor_MED17_B8" SG_ 256 ESP_v_Signal 256;
BA_ "GenSigTimeoutMsg_Motor_MED9_B8" SG_ 256 ESP_v_Signal 256;
BA_ "GenSigTimeoutMsg_Motor_SIMOS8_B8" SG_ 256 ESP_v_Signal 256;
BA_ "GenSigAutoGenDsp" SG_ 256 ASR_Tastung_passiv 1;
BA_ "GenSigAutoGenSnd" SG_ 256 ASR_Tastung_passiv 1;
BA_ "GenSigEnvVarType" SG_ 256 ASR_Tastung_passiv 0;
BA_ "GenSigSendType" SG_ 256 ASR_Tastung_passiv 7;
BA_ "NWM-WakeupAllowed" SG_ 256 ASR_Tastung_passiv 0;
BA_ "NMH-WakeupAllowed" SG_ 256 ASR_Tastung_passiv 0;
BA_ "GenSigTimeoutMsg_Airbag_B8" SG_ 256 ASR_Tastung_passiv 256;
BA_ "GenSigTimeoutMsg_Getriebe_AL6000" SG_ 256 ASR_Tastung_passiv 256;
BA_ "GenSigTimeoutMsg_Getriebe_DL5001" SG_ 256 ASR_Tastung_passiv 256;
BA_ "GenSigTimeoutMsg_Getriebe_VL3002" SG_ 256 ASR_Tastung_passiv 256;
BA_ "GenSigTimeoutMsg_Motor_EDC17_003" SG_ 256 ASR_Tastung_passiv 256;
BA_ "GenSigTimeoutMsg_Motor_EDC17_004" SG_ 256 ASR_Tastung_passiv 256;
BA_ "GenSigTimeoutMsg_Motor_MED17_B8" SG_ 256 ASR_Tastung_passiv 256;
BA_ "GenSigTimeoutMsg_Motor_MED9_B8" SG_ 256 ASR_Tastung_passiv 256;
BA_ "GenSigTimeoutMsg_Motor_SIMOS8_B8" SG_ 256 ASR_Tastung_passiv 256;
BA_ "GenSigAutoGenDsp" SG_ 256 ESP_Tastung_passiv 1;
BA_ "GenSigAutoGenSnd" SG_ 256 ESP_Tastung_passiv 1;
BA_ "GenSigEnvVarType" SG_ 256 ESP_Tastung_passiv 0;
BA_ "GenSigSendType" SG_ 256 ESP_Tastung_passiv 7;
BA_ "NWM-WakeupAllowed" SG_ 256 ESP_Tastung_passiv 0;
BA_ "NMH-WakeupAllowed" SG_ 256 ESP_Tastung_passiv 0;
BA_ "GenSigTimeoutMsg_Airbag_B8" SG_ 256 ESP_Tastung_passiv 256;
BA_ "GenSigTimeoutMsg_Getriebe_AL6000" SG_ 256 ESP_Tastung_passiv 256;
BA_ "GenSigTimeoutMsg_Getriebe_DL5001" SG_ 256 ESP_Tastung_passiv 256;
BA_ "GenSigTimeoutMsg_Getriebe_VL3002" SG_ 256 ESP_Tastung_passiv 256;
BA_ "GenSigTimeoutMsg_Motor_EDC17_003" SG_ 256 ESP_Tastung_passiv 256;
BA_ "GenSigTimeoutMsg_Motor_EDC17_004" SG_ 256 ESP_Tastung_passiv 256;
BA_ "GenSigTimeoutMsg_Motor_MED17_B8" SG_ 256 ESP_Tastung_passiv 256;
BA_ "GenSigTimeoutMsg_Motor_MED9_B8" SG_ 256 ESP_Tastung_passiv 256;
BA_ "GenSigTimeoutMsg_Motor_SIMOS8_B8" SG_ 256 ESP_Tastung_passiv 256;
BA_ "GenSigAutoGenDsp" SG_ 256 ESP_Systemstatus 1;
BA_ "GenSigAutoGenSnd" SG_ 256 ESP_Systemstatus 1;
BA_ "GenSigEnvVarType" SG_ 256 ESP_Systemstatus 0;
BA_ "GenSigSendType" SG_ 256 ESP_Systemstatus 7;
BA_ "NWM-WakeupAllowed" SG_ 256 ESP_Systemstatus 0;
BA_ "NMH-WakeupAllowed" SG_ 256 ESP_Systemstatus 0;
BA_ "GenSigTimeoutMsg_Airbag_B8" SG_ 256 ESP_Systemstatus 256;
BA_ "GenSigTimeoutMsg_Motor_EDC17_003" SG_ 256 ESP_Systemstatus 256;
BA_ "GenSigTimeoutMsg_Motor_EDC17_004" SG_ 256 ESP_Systemstatus 256;
BA_ "GenSigTimeoutMsg_Motor_MED17_B8" SG_ 256 ESP_Systemstatus 256;
BA_ "GenSigTimeoutMsg_Motor_MED9_B8" SG_ 256 ESP_Systemstatus 256;
BA_ "GenSigTimeoutMsg_Motor_SIMOS8_B8" SG_ 256 ESP_Systemstatus 256;
BA_ "GenSigAutoGenDsp" SG_ 256 ASR_Schalteingriff 1;
BA_ "GenSigAutoGenSnd" SG_ 256 ASR_Schalteingriff 1;
BA_ "GenSigEnvVarType" SG_ 256 ASR_Schalteingriff 0;
BA_ "GenSigSendType" SG_ 256 ASR_Schalteingriff 7;
BA_ "NWM-WakeupAllowed" SG_ 256 ASR_Schalteingriff 0;
BA_ "NMH-WakeupAllowed" SG_ 256 ASR_Schalteingriff 0;
BA_ "GenSigTimeoutMsg_Airbag_B8" SG_ 256 ASR_Schalteingriff 256;
BA_ "GenSigTimeoutMsg_Getriebe_AL6000" SG_ 256 ASR_Schalteingriff 256;
BA_ "GenSigTimeoutMsg_Getriebe_DL5001" SG_ 256 ASR_Schalteingriff 256;
BA_ "GenSigTimeoutMsg_Getriebe_VL3002" SG_ 256 ASR_Schalteingriff 256;
BA_ "GenSigAutoGenDsp" SG_ 256 OBD_Schlechtweg 1;
BA_ "GenSigAutoGenSnd" SG_ 256 OBD_Schlechtweg 1;
BA_ "GenSigEnvVarType" SG_ 256 OBD_Schlechtweg 0;
BA_ "GenSigSendType" SG_ 256 OBD_Schlechtweg 7;
BA_ "NWM-WakeupAllowed" SG_ 256 OBD_Schlechtweg 0;
BA_ "NMH-WakeupAllowed" SG_ 256 OBD_Schlechtweg 0;
BA_ "GenSigTimeoutMsg_Motor_EDC17_003" SG_ 256 OBD_Schlechtweg 256;
BA_ "GenSigTimeoutMsg_Motor_EDC17_004" SG_ 256 OBD_Schlechtweg 256;
BA_ "GenSigTimeoutMsg_Motor_MED17_B8" SG_ 256 OBD_Schlechtweg 256;
BA_ "GenSigTimeoutMsg_Motor_MED9_B8" SG_ 256 OBD_Schlechtweg 256;
BA_ "GenSigTimeoutMsg_Motor_SIMOS8_B8" SG_ 256 OBD_Schlechtweg 256;
BA_ "GenSigAutoGenDsp" SG_ 256 OBD_QBit_Schlechtweg 1;
BA_ "GenSigAutoGenSnd" SG_ 256 OBD_QBit_Schlechtweg 1;
BA_ "GenSigEnvVarType" SG_ 256 OBD_QBit_Schlechtweg 0;
BA_ "GenSigSendType" SG_ 256 OBD_QBit_Schlechtweg 7;
BA_ "GenSigStartValue" SG_ 256 OBD_QBit_Schlechtweg 1;
BA_ "NWM-WakeupAllowed" SG_ 256 OBD_QBit_Schlechtweg 0;
BA_ "NMH-WakeupAllowed" SG_ 256 OBD_QBit_Schlechtweg 0;
BA_ "GenSigTimeoutMsg_Motor_EDC17_003" SG_ 256 OBD_QBit_Schlechtweg 256;
BA_ "GenSigTimeoutMsg_Motor_EDC17_004" SG_ 256 OBD_QBit_Schlechtweg 256;
BA_ "GenSigTimeoutMsg_Motor_MED17_B8" SG_ 256 OBD_QBit_Schlechtweg 256;
BA_ "GenSigTimeoutMsg_Motor_MED9_B8" SG_ 256 OBD_QBit_Schlechtweg 256;
BA_ "GenSigTimeoutMsg_Motor_SIMOS8_B8" SG_ 256 OBD_QBit_Schlechtweg 256;
BA_ "GenSigAutoGenDsp" SG_ 256 ESP_QBit_v_Signal 1;
BA_ "GenSigAutoGenSnd" SG_ 256 ESP_QBit_v_Signal 1;
BA_ "GenSigEnvVarType" SG_ 256 ESP_QBit_v_Signal 0;
BA_ "GenSigSendType" SG_ 256 ESP_QBit_v_Signal 7;
BA_ "GenSigStartValue" SG_ 256 ESP_QBit_v_Signal 1;
BA_ "NWM-WakeupAllowed" SG_ 256 ESP_QBit_v_Signal 0;
BA_ "NMH-WakeupAllowed" SG_ 256 ESP_QBit_v_Signal 0;
BA_ "GenSigTimeoutMsg_Airbag_B8" SG_ 256 ESP_QBit_v_Signal 256;
BA_ "GenSigTimeoutMsg_Daempfer_B8" SG_ 256 ESP_QBit_v_Signal 256;
BA_ "GenSigTimeoutMsg_Getriebe_AL6000" SG_ 256 ESP_QBit_v_Signal 256;
BA_ "GenSigTimeoutMsg_Getriebe_DL5001" SG_ 256 ESP_QBit_v_Signal 256;
BA_ "GenSigTimeoutMsg_Motor_EDC17_003" SG_ 256 ESP_QBit_v_Signal 256;
BA_ "GenSigTimeoutMsg_Motor_EDC17_004" SG_ 256 ESP_QBit_v_Signal 256;
BA_ "GenSigTimeoutMsg_Motor_MED17_B8" SG_ 256 ESP_QBit_v_Signal 256;
BA_ "GenSigTimeoutMsg_Motor_MED9_B8" SG_ 256 ESP_QBit_v_Signal 256;
BA_ "GenSigTimeoutMsg_Motor_SIMOS8_B8" SG_ 256 ESP_QBit_v_Signal 256;
BA_ "GenSigAutoGenDsp" SG_ 256 ABS_Bremsung 1;
BA_ "GenSigAutoGenSnd" SG_ 256 ABS_Bremsung 1;
BA_ "GenSigEnvVarType" SG_ 256 ABS_Bremsung 0;
BA_ "GenSigSendType" SG_ 256 ABS_Bremsung 7;
BA_ "NWM-WakeupAllowed" SG_ 256 ABS_Bremsung 0;
BA_ "NMH-WakeupAllowed" SG_ 256 ABS_Bremsung 0;
BA_ "GenSigTimeoutMsg_Airbag_B8" SG_ 256 ABS_Bremsung 256;
BA_ "GenSigTimeoutMsg_Daempfer_B8" SG_ 256 ABS_Bremsung 256;
BA_ "GenSigTimeoutMsg_Getriebe_AL6000" SG_ 256 ABS_Bremsung 256;
BA_ "GenSigTimeoutMsg_Getriebe_DL5001" SG_ 256 ABS_Bremsung 256;
BA_ "GenSigTimeoutMsg_Getriebe_VL3002" SG_ 256 ABS_Bremsung 256;
BA_ "GenSigTimeoutMsg_Motor_EDC17_003" SG_ 256 ABS_Bremsung 256;
BA_ "GenSigTimeoutMsg_Motor_EDC17_004" SG_ 256 ABS_Bremsung 256;
BA_ "GenSigTimeoutMsg_Motor_MED17_B8" SG_ 256 ABS_Bremsung 256;
BA_ "GenSigTimeoutMsg_Motor_MED9_B8" SG_ 256 ABS_Bremsung 256;
BA_ "GenSigTimeoutMsg_Motor_SIMOS8_B8" SG_ 256 ABS_Bremsung 256;
BA_ "GenSigAutoGenDsp" SG_ 256 ASR_Anf 1;
BA_ "GenSigAutoGenSnd" SG_ 256 ASR_Anf 1;
BA_ "GenSigEnvVarType" SG_ 256 ASR_Anf 0;
BA_ "GenSigSendType" SG_ 256 ASR_Anf 7;
BA_ "NWM-WakeupAllowed" SG_ 256 ASR_Anf 0;
BA_ "NMH-WakeupAllowed" SG_ 256 ASR_Anf 0;
BA_ "GenSigTimeoutMsg_Airbag_B8" SG_ 256 ASR_Anf 256;
BA_ "GenSigTimeoutMsg_Getriebe_AL6000" SG_ 256 ASR_Anf 256;
BA_ "GenSigTimeoutMsg_Getriebe_DL5001" SG_ 256 ASR_Anf 256;
BA_ "GenSigTimeoutMsg_Getriebe_VL3002" SG_ 256 ASR_Anf 256;
BA_ "GenSigTimeoutMsg_Motor_EDC17_003" SG_ 256 ASR_Anf 256;
BA_ "GenSigTimeoutMsg_Motor_EDC17_004" SG_ 256 ASR_Anf 256;
BA_ "GenSigTimeoutMsg_Motor_MED17_B8" SG_ 256 ASR_Anf 256;
BA_ "GenSigTimeoutMsg_Motor_MED9_B8" SG_ 256 ASR_Anf 256;
BA_ "GenSigTimeoutMsg_Motor_SIMOS8_B8" SG_ 256 ASR_Anf 256;
BA_ "GenSigAutoGenDsp" SG_ 256 MSR_Anf 1;
BA_ "GenSigAutoGenSnd" SG_ 256 MSR_Anf 1;
BA_ "GenSigEnvVarType" SG_ 256 MSR_Anf 0;
BA_ "GenSigSendType" SG_ 256 MSR_Anf 7;
BA_ "NWM-WakeupAllowed" SG_ 256 MSR_Anf 0;
BA_ "NMH-WakeupAllowed" SG_ 256 MSR_Anf 0;
BA_ "GenSigTimeoutMsg_Airbag_B8" SG_ 256 MSR_Anf 256;
BA_ "GenSigTimeoutMsg_Getriebe_VL3002" SG_ 256 MSR_Anf 256;
BA_ "GenSigTimeoutMsg_Motor_EDC17_003" SG_ 256 MSR_Anf 256;
BA_ "GenSigTimeoutMsg_Motor_EDC17_004" SG_ 256 MSR_Anf 256;
BA_ "GenSigTimeoutMsg_Motor_MED17_B8" SG_ 256 MSR_Anf 256;
BA_ "GenSigTimeoutMsg_Motor_MED9_B8" SG_ 256 MSR_Anf 256;
BA_ "GenSigTimeoutMsg_Motor_SIMOS8_B8" SG_ 256 MSR_Anf 256;
BA_ "GenSigAutoGenDsp" SG_ 256 EBV_Eingriff 1;
BA_ "GenSigAutoGenSnd" SG_ 256 EBV_Eingriff 1;
BA_ "GenSigEnvVarType" SG_ 256 EBV_Eingriff 0;
BA_ "GenSigSendType" SG_ 256 EBV_Eingriff 7;
BA_ "NWM-WakeupAllowed" SG_ 256 EBV_Eingriff 0;
BA_ "NMH-WakeupAllowed" SG_ 256 EBV_Eingriff 0;
BA_ "GenSigTimeoutMsg_Airbag_B8" SG_ 256 EBV_Eingriff 256;
BA_ "GenSigTimeoutMsg_Daempfer_B8" SG_ 256 EBV_Eingriff 256;
BA_ "GenSigTimeoutMsg_Getriebe_AL6000" SG_ 256 EBV_Eingriff 256;
BA_ "GenSigTimeoutMsg_Getriebe_DL5001" SG_ 256 EBV_Eingriff 256;
BA_ "GenSigTimeoutMsg_Motor_EDC17_003" SG_ 256 EBV_Eingriff 256;
BA_ "GenSigTimeoutMsg_Motor_EDC17_004" SG_ 256 EBV_Eingriff 256;
BA_ "GenSigTimeoutMsg_Motor_MED17_B8" SG_ 256 EBV_Eingriff 256;
BA_ "GenSigTimeoutMsg_Motor_MED9_B8" SG_ 256 EBV_Eingriff 256;
BA_ "GenSigTimeoutMsg_Motor_SIMOS8_B8" SG_ 256 EBV_Eingriff 256;
BA_ "GenSigAutoGenDsp" SG_ 256 EDS_Eingriff 1;
BA_ "GenSigAutoGenSnd" SG_ 256 EDS_Eingriff 1;
BA_ "GenSigEnvVarType" SG_ 256 EDS_Eingriff 0;
BA_ "GenSigSendType" SG_ 256 EDS_Eingriff 7;
BA_ "NWM-WakeupAllowed" SG_ 256 EDS_Eingriff 0;
BA_ "NMH-WakeupAllowed" SG_ 256 EDS_Eingriff 0;
BA_ "GenSigTimeoutMsg_Airbag_B8" SG_ 256 EDS_Eingriff 256;
BA_ "GenSigTimeoutMsg_Daempfer_B8" SG_ 256 EDS_Eingriff 256;
BA_ "GenSigTimeoutMsg_Getriebe_VL3002" SG_ 256 EDS_Eingriff 256;
BA_ "GenSigTimeoutMsg_Motor_EDC17_003" SG_ 256 EDS_Eingriff 256;
BA_ "GenSigTimeoutMsg_Motor_EDC17_004" SG_ 256 EDS_Eingriff 256;
BA_ "GenSigTimeoutMsg_Motor_MED17_B8" SG_ 256 EDS_Eingriff 256;
BA_ "GenSigTimeoutMsg_Motor_MED9_B8" SG_ 256 EDS_Eingriff 256;
BA_ "GenSigTimeoutMsg_Motor_SIMOS8_B8" SG_ 256 EDS_Eingriff 256;
BA_ "GenSigAutoGenDsp" SG_ 256 ESP_Eingriff 1;
BA_ "GenSigAutoGenSnd" SG_ 256 ESP_Eingriff 1;
BA_ "GenSigEnvVarType" SG_ 256 ESP_Eingriff 0;
BA_ "GenSigSendType" SG_ 256 ESP_Eingriff 7;
BA_ "NWM-WakeupAllowed" SG_ 256 ESP_Eingriff 0;
BA_ "NMH-WakeupAllowed" SG_ 256 ESP_Eingriff 0;
BA_ "GenSigTimeoutMsg_Airbag_B8" SG_ 256 ESP_Eingriff 256;
BA_ "GenSigTimeoutMsg_Daempfer_B8" SG_ 256 ESP_Eingriff 256;
BA_ "GenSigTimeoutMsg_Getriebe_AL6000" SG_ 256 ESP_Eingriff 256;
BA_ "GenSigTimeoutMsg_Getriebe_DL5001" SG_ 256 ESP_Eingriff 256;
BA_ "GenSigTimeoutMsg_Getriebe_VL3002" SG_ 256 ESP_Eingriff 256;
BA_ "GenSigTimeoutMsg_Motor_EDC17_003" SG_ 256 ESP_Eingriff 256;
BA_ "GenSigTimeoutMsg_Motor_EDC17_004" SG_ 256 ESP_Eingriff 256;
BA_ "GenSigTimeoutMsg_Motor_MED17_B8" SG_ 256 ESP_Eingriff 256;
BA_ "GenSigTimeoutMsg_Motor_MED9_B8" SG_ 256 ESP_Eingriff 256;
BA_ "GenSigTimeoutMsg_Motor_SIMOS8_B8" SG_ 256 ESP_Eingriff 256;
BA_ "GenSigAutoGenDsp" SG_ 256 ESP_ASP 1;
BA_ "GenSigAutoGenSnd" SG_ 256 ESP_ASP 1;
BA_ "GenSigEnvVarType" SG_ 256 ESP_ASP 0;
BA_ "GenSigSendType" SG_ 256 ESP_ASP 7;
BA_ "NWM-WakeupAllowed" SG_ 256 ESP_ASP 0;
BA_ "NMH-WakeupAllowed" SG_ 256 ESP_ASP 0;
BA_ "GenSigTimeoutMsg_Motor_EDC17_003" SG_ 256 ESP_ASP 256;
BA_ "GenSigTimeoutMsg_Motor_EDC17_004" SG_ 256 ESP_ASP 256;
BA_ "GenSigTimeoutMsg_Motor_MED17_B8" SG_ 256 ESP_ASP 256;
BA_ "GenSigTimeoutMsg_Motor_MED9_B8" SG_ 256 ESP_ASP 256;
BA_ "GenSigTimeoutMsg_Motor_SIMOS8_B8" SG_ 256 ESP_ASP 256;
BA_ "GenSigAutoGenDsp" SG_ 256 ESP_KD_Fehler 1;
BA_ "GenSigAutoGenSnd" SG_ 256 ESP_KD_Fehler 1;
BA_ "GenSigEnvVarType" SG_ 256 ESP_KD_Fehler 0;
BA_ "GenSigSendType" SG_ 256 ESP_KD_Fehler 7;
BA_ "NWM-WakeupAllowed" SG_ 256 ESP_KD_Fehler 0;
BA_ "NMH-WakeupAllowed" SG_ 256 ESP_KD_Fehler 0;
BA_ "GenSigAutoGenDsp" SG_ 257 ESP_02_CHK 1;
BA_ "GenSigAutoGenSnd" SG_ 257 ESP_02_CHK 1;
BA_ "GenSigEnvVarType" SG_ 257 ESP_02_CHK 0;
BA_ "GenSigSendType" SG_ 257 ESP_02_CHK 7;
BA_ "NWM-WakeupAllowed" SG_ 257 ESP_02_CHK 0;
BA_ "NMH-WakeupAllowed" SG_ 257 ESP_02_CHK 0;
BA_ "GenSigTimeoutMsg_Daempfer_B8" SG_ 257 ESP_02_CHK 257;
BA_ "GenSigTimeoutMsg_Getriebe_AL6000" SG_ 257 ESP_02_CHK 257;
BA_ "GenSigTimeoutMsg_Getriebe_DL5001" SG_ 257 ESP_02_CHK 257;
BA_ "GenSigTimeoutMsg_Motor_EDC17_003" SG_ 257 ESP_02_CHK 257;
BA_ "GenSigTimeoutMsg_Motor_EDC17_004" SG_ 257 ESP_02_CHK 257;
BA_ "GenSigTimeoutMsg_Motor_MED17_B8" SG_ 257 ESP_02_CHK 257;
BA_ "GenSigTimeoutMsg_Motor_MED9_B8" SG_ 257 ESP_02_CHK 257;
BA_ "GenSigTimeoutMsg_Motor_SIMOS8_B8" SG_ 257 ESP_02_CHK 257;
BA_ "GenSigAutoGenDsp" SG_ 257 ESP_02_BZ 1;
BA_ "GenSigAutoGenSnd" SG_ 257 ESP_02_BZ 1;
BA_ "GenSigEnvVarType" SG_ 257 ESP_02_BZ 0;
BA_ "GenSigSendType" SG_ 257 ESP_02_BZ 7;
BA_ "NWM-WakeupAllowed" SG_ 257 ESP_02_BZ 0;
BA_ "NMH-WakeupAllowed" SG_ 257 ESP_02_BZ 0;
BA_ "GenSigTimeoutMsg_Daempfer_B8" SG_ 257 ESP_02_BZ 257;
BA_ "GenSigTimeoutMsg_Getriebe_AL6000" SG_ 257 ESP_02_BZ 257;
BA_ "GenSigTimeoutMsg_Getriebe_DL5001" SG_ 257 ESP_02_BZ 257;
BA_ "GenSigTimeoutMsg_Motor_EDC17_003" SG_ 257 ESP_02_BZ 257;
BA_ "GenSigTimeoutMsg_Motor_EDC17_004" SG_ 257 ESP_02_BZ 257;
BA_ "GenSigTimeoutMsg_Motor_MED17_B8" SG_ 257 ESP_02_BZ 257;
BA_ "GenSigTimeoutMsg_Motor_MED9_B8" SG_ 257 ESP_02_BZ 257;
BA_ "GenSigTimeoutMsg_Motor_SIMOS8_B8" SG_ 257 ESP_02_BZ 257;
BA_ "GenSigAutoGenDsp" SG_ 257 ESP_QBit_Gierrate 1;
BA_ "GenSigAutoGenSnd" SG_ 257 ESP_QBit_Gierrate 1;
BA_ "GenSigEnvVarType" SG_ 257 ESP_QBit_Gierrate 0;
BA_ "GenSigSendType" SG_ 257 ESP_QBit_Gierrate 7;
BA_ "GenSigStartValue" SG_ 257 ESP_QBit_Gierrate 1;
BA_ "NWM-WakeupAllowed" SG_ 257 ESP_QBit_Gierrate 0;
BA_ "NMH-WakeupAllowed" SG_ 257 ESP_QBit_Gierrate 0;
BA_ "GenSigTimeoutMsg_AFS_B8" SG_ 257 ESP_QBit_Gierrate 257;
BA_ "GenSigTimeoutMsg_Daempfer_B8" SG_ 257 ESP_QBit_Gierrate 257;
BA_ "GenSigAutoGenDsp" SG_ 257 ESP_QBit_Laengsbeschl 1;
BA_ "GenSigAutoGenSnd" SG_ 257 ESP_QBit_Laengsbeschl 1;
BA_ "GenSigEnvVarType" SG_ 257 ESP_QBit_Laengsbeschl 0;
BA_ "GenSigSendType" SG_ 257 ESP_QBit_Laengsbeschl 7;
BA_ "GenSigStartValue" SG_ 257 ESP_QBit_Laengsbeschl 1;
BA_ "NWM-WakeupAllowed" SG_ 257 ESP_QBit_Laengsbeschl 0;
BA_ "NMH-WakeupAllowed" SG_ 257 ESP_QBit_Laengsbeschl 0;
BA_ "GenSigAutoGenDsp" SG_ 257 ESP_QBit_Querb 1;
BA_ "GenSigAutoGenSnd" SG_ 257 ESP_QBit_Querb 1;
BA_ "GenSigEnvVarType" SG_ 257 ESP_QBit_Querb 0;
BA_ "GenSigSendType" SG_ 257 ESP_QBit_Querb 7;
BA_ "GenSigStartValue" SG_ 257 ESP_QBit_Querb 1;
BA_ "NWM-WakeupAllowed" SG_ 257 ESP_QBit_Querb 0;
BA_ "NMH-WakeupAllowed" SG_ 257 ESP_QBit_Querb 0;
BA_ "GenSigTimeoutMsg_AFS_B8" SG_ 257 ESP_QBit_Querb 257;
BA_ "GenSigTimeoutMsg_Daempfer_B8" SG_ 257 ESP_QBit_Querb 257;
BA_ "GenSigTimeoutMsg_Getriebe_AL6000" SG_ 257 ESP_QBit_Querb 257;
BA_ "GenSigTimeoutMsg_Getriebe_DL5001" SG_ 257 ESP_QBit_Querb 257;
BA_ "GenSigTimeoutMsg_Motor_EDC17_003" SG_ 257 ESP_QBit_Querb 257;
BA_ "GenSigTimeoutMsg_Motor_EDC17_004" SG_ 257 ESP_QBit_Querb 257;
BA_ "GenSigTimeoutMsg_Motor_MED17_B8" SG_ 257 ESP_QBit_Querb 257;
BA_ "GenSigTimeoutMsg_Motor_MED9_B8" SG_ 257 ESP_QBit_Querb 257;
BA_ "GenSigTimeoutMsg_Motor_SIMOS8_B8" SG_ 257 ESP_QBit_Querb 257;
BA_ "GenSigAutoGenDsp" SG_ 257 ESP_Stillstandsflag 1;
BA_ "GenSigAutoGenSnd" SG_ 257 ESP_Stillstandsflag 1;
BA_ "GenSigEnvVarType" SG_ 257 ESP_Stillstandsflag 0;
BA_ "GenSigSendType" SG_ 257 ESP_Stillstandsflag 7;
BA_ "NWM-WakeupAllowed" SG_ 257 ESP_Stillstandsflag 0;
BA_ "NMH-WakeupAllowed" SG_ 257 ESP_Stillstandsflag 0;
BA_ "GenSigAutoGenDsp" SG_ 257 ESP_Querbeschleunigung 1;
BA_ "GenSigAutoGenSnd" SG_ 257 ESP_Querbeschleunigung 1;
BA_ "GenSigEnvVarType" SG_ 257 ESP_Querbeschleunigung 1;
BA_ "GenSigSendType" SG_ 257 ESP_Querbeschleunigung 7;
BA_ "GenSigStartValue" SG_ 257 ESP_Querbeschleunigung 127;
BA_ "NWM-WakeupAllowed" SG_ 257 ESP_Querbeschleunigung 0;
BA_ "NMH-WakeupAllowed" SG_ 257 ESP_Querbeschleunigung 0;
BA_ "GenSigTimeoutMsg_AFS_B8" SG_ 257 ESP_Querbeschleunigung 257;
BA_ "GenSigTimeoutMsg_Daempfer_B8" SG_ 257 ESP_Querbeschleunigung 257;
BA_ "GenSigTimeoutMsg_Getriebe_AL6000" SG_ 257 ESP_Querbeschleunigung 257;
BA_ "GenSigTimeoutMsg_Getriebe_DL5001" SG_ 257 ESP_Querbeschleunigung 257;
BA_ "GenSigTimeoutMsg_Motor_EDC17_003" SG_ 257 ESP_Querbeschleunigung 257;
BA_ "GenSigTimeoutMsg_Motor_EDC17_004" SG_ 257 ESP_Querbeschleunigung 257;
BA_ "GenSigTimeoutMsg_Motor_MED17_B8" SG_ 257 ESP_Querbeschleunigung 257;
BA_ "GenSigTimeoutMsg_Motor_MED9_B8" SG_ 257 ESP_Querbeschleunigung 257;
BA_ "GenSigTimeoutMsg_Motor_SIMOS8_B8" SG_ 257 ESP_Querbeschleunigung 257;
BA_ "GenSigAutoGenDsp" SG_ 257 ESP_Laengsbeschl 1;
BA_ "GenSigAutoGenSnd" SG_ 257 ESP_Laengsbeschl 1;
BA_ "GenSigSendType" SG_ 257 ESP_Laengsbeschl 7;
BA_ "GenSigStartValue" SG_ 257 ESP_Laengsbeschl 512;
BA_ "NWM-WakeupAllowed" SG_ 257 ESP_Laengsbeschl 0;
BA_ "NMH-WakeupAllowed" SG_ 257 ESP_Laengsbeschl 0;
BA_ "GenSigAutoGenDsp" SG_ 257 ESP_Verteil_Wankmom 1;
BA_ "GenSigAutoGenSnd" SG_ 257 ESP_Verteil_Wankmom 1;
BA_ "GenSigSendType" SG_ 257 ESP_Verteil_Wankmom 7;
BA_ "GenSigStartValue" SG_ 257 ESP_Verteil_Wankmom 30;
BA_ "NWM-WakeupAllowed" SG_ 257 ESP_Verteil_Wankmom 0;
BA_ "NMH-WakeupAllowed" SG_ 257 ESP_Verteil_Wankmom 0;
BA_ "GenSigAutoGenDsp" SG_ 257 ESP_QBit_Anf_Vert_Wank 1;
BA_ "GenSigAutoGenSnd" SG_ 257 ESP_QBit_Anf_Vert_Wank 1;
BA_ "GenSigSendType" SG_ 257 ESP_QBit_Anf_Vert_Wank 7;
BA_ "GenSigStartValue" SG_ 257 ESP_QBit_Anf_Vert_Wank 1;
BA_ "NWM-WakeupAllowed" SG_ 257 ESP_QBit_Anf_Vert_Wank 0;
BA_ "NMH-WakeupAllowed" SG_ 257 ESP_QBit_Anf_Vert_Wank 0;
BA_ "GenSigAutoGenDsp" SG_ 257 ESP_Gierrate 1;
BA_ "GenSigAutoGenSnd" SG_ 257 ESP_Gierrate 1;
BA_ "GenSigEnvVarType" SG_ 257 ESP_Gierrate 1;
BA_ "GenSigSendType" SG_ 257 ESP_Gierrate 7;
BA_ "NWM-WakeupAllowed" SG_ 257 ESP_Gierrate 0;
BA_ "NMH-WakeupAllowed" SG_ 257 ESP_Gierrate 0;
BA_ "GenSigTimeoutMsg_AFS_B8" SG_ 257 ESP_Gierrate 257;
BA_ "GenSigTimeoutMsg_Daempfer_B8" SG_ 257 ESP_Gierrate 257;
BA_ "GenSigAutoGenDsp" SG_ 257 ESP_VZ_Gierrate 1;
BA_ "GenSigAutoGenSnd" SG_ 257 ESP_VZ_Gierrate 1;
BA_ "GenSigEnvVarType" SG_ 257 ESP_VZ_Gierrate 1;
BA_ "GenSigSendType" SG_ 257 ESP_VZ_Gierrate 7;
BA_ "NWM-WakeupAllowed" SG_ 257 ESP_VZ_Gierrate 0;
BA_ "NMH-WakeupAllowed" SG_ 257 ESP_VZ_Gierrate 0;
BA_ "GenSigTimeoutMsg_AFS_B8" SG_ 257 ESP_VZ_Gierrate 257;
BA_ "GenSigTimeoutMsg_Daempfer_B8" SG_ 257 ESP_VZ_Gierrate 257;
BA_ "GenSigAutoGenDsp" SG_ 257 ESP_Notbremsanzeige 1;
BA_ "GenSigAutoGenSnd" SG_ 257 ESP_Notbremsanzeige 1;
BA_ "GenSigEnvVarType" SG_ 257 ESP_Notbremsanzeige 0;
BA_ "GenSigSendType" SG_ 257 ESP_Notbremsanzeige 7;
BA_ "NWM-WakeupAllowed" SG_ 257 ESP_Notbremsanzeige 0;
BA_ "NMH-WakeupAllowed" SG_ 257 ESP_Notbremsanzeige 0;
BA_ "GenSigAutoGenDsp" SG_ 257 void_Byte_11 1;
BA_ "GenSigAutoGenSnd" SG_ 257 void_Byte_11 1;
BA_ "GenSigSendType" SG_ 257 void_Byte_11 7;
BA_ "NWM-WakeupAllowed" SG_ 257 void_Byte_11 0;
BA_ "NMH-WakeupAllowed" SG_ 257 void_Byte_11 0;
BA_ "GenSigAutoGenDsp" SG_ 259 ESP_03_CHK 1;
BA_ "GenSigAutoGenSnd" SG_ 259 ESP_03_CHK 1;
BA_ "GenSigEnvVarType" SG_ 259 ESP_03_CHK 0;
BA_ "GenSigSendType" SG_ 259 ESP_03_CHK 7;
BA_ "NWM-WakeupAllowed" SG_ 259 ESP_03_CHK 0;
BA_ "NMH-WakeupAllowed" SG_ 259 ESP_03_CHK 0;
BA_ "GenSigTimeoutMsg_Getriebe_AL6000" SG_ 259 ESP_03_CHK 259;
BA_ "GenSigTimeoutMsg_Getriebe_DL5001" SG_ 259 ESP_03_CHK 259;
BA_ "GenSigTimeoutMsg_Getriebe_VL3002" SG_ 259 ESP_03_CHK 259;
BA_ "GenSigAutoGenDsp" SG_ 259 ESP_03_BZ 1;
BA_ "GenSigAutoGenSnd" SG_ 259 ESP_03_BZ 1;
BA_ "GenSigEnvVarType" SG_ 259 ESP_03_BZ 0;
BA_ "GenSigSendType" SG_ 259 ESP_03_BZ 7;
BA_ "NWM-WakeupAllowed" SG_ 259 ESP_03_BZ 0;
BA_ "NMH-WakeupAllowed" SG_ 259 ESP_03_BZ 0;
BA_ "GenSigTimeoutMsg_Getriebe_AL6000" SG_ 259 ESP_03_BZ 259;
BA_ "GenSigTimeoutMsg_Getriebe_DL5001" SG_ 259 ESP_03_BZ 259;
BA_ "GenSigTimeoutMsg_Getriebe_VL3002" SG_ 259 ESP_03_BZ 259;
BA_ "GenSigAutoGenDsp" SG_ 259 ESP_VL_FR 1;
BA_ "GenSigAutoGenSnd" SG_ 259 ESP_VL_FR 1;
BA_ "GenSigEnvVarType" SG_ 259 ESP_VL_FR 0;
BA_ "GenSigSendType" SG_ 259 ESP_VL_FR 7;
BA_ "NWM-WakeupAllowed" SG_ 259 ESP_VL_FR 0;
BA_ "NMH-WakeupAllowed" SG_ 259 ESP_VL_FR 0;
BA_ "GenSigTimeoutMsg_Getriebe_AL6000" SG_ 259 ESP_VL_FR 259;
BA_ "GenSigTimeoutMsg_Getriebe_DL5001" SG_ 259 ESP_VL_FR 259;
BA_ "GenSigAutoGenDsp" SG_ 259 ESP_VR_FR 1;
BA_ "GenSigAutoGenSnd" SG_ 259 ESP_VR_FR 1;
BA_ "GenSigEnvVarType" SG_ 259 ESP_VR_FR 0;
BA_ "GenSigSendType" SG_ 259 ESP_VR_FR 7;
BA_ "NWM-WakeupAllowed" SG_ 259 ESP_VR_FR 0;
BA_ "NMH-WakeupAllowed" SG_ 259 ESP_VR_FR 0;
BA_ "GenSigTimeoutMsg_Getriebe_AL6000" SG_ 259 ESP_VR_FR 259;
BA_ "GenSigTimeoutMsg_Getriebe_DL5001" SG_ 259 ESP_VR_FR 259;
BA_ "GenSigAutoGenDsp" SG_ 259 ESP_HL_FR 1;
BA_ "GenSigAutoGenSnd" SG_ 259 ESP_HL_FR 1;
BA_ "GenSigEnvVarType" SG_ 259 ESP_HL_FR 0;
BA_ "GenSigSendType" SG_ 259 ESP_HL_FR 7;
BA_ "NWM-WakeupAllowed" SG_ 259 ESP_HL_FR 0;
BA_ "NMH-WakeupAllowed" SG_ 259 ESP_HL_FR 0;
BA_ "GenSigTimeoutMsg_AFS_B8" SG_ 259 ESP_HL_FR 259;
BA_ "GenSigTimeoutMsg_Getriebe_AL6000" SG_ 259 ESP_HL_FR 259;
BA_ "GenSigTimeoutMsg_Getriebe_DL5001" SG_ 259 ESP_HL_FR 259;
BA_ "GenSigTimeoutMsg_LWR_B8" SG_ 259 ESP_HL_FR 259;
BA_ "GenSigAutoGenDsp" SG_ 259 ESP_HR_FR 1;
BA_ "GenSigAutoGenSnd" SG_ 259 ESP_HR_FR 1;
BA_ "GenSigEnvVarType" SG_ 259 ESP_HR_FR 0;
BA_ "GenSigSendType" SG_ 259 ESP_HR_FR 7;
BA_ "NWM-WakeupAllowed" SG_ 259 ESP_HR_FR 0;
BA_ "NMH-WakeupAllowed" SG_ 259 ESP_HR_FR 0;
BA_ "GenSigTimeoutMsg_AFS_B8" SG_ 259 ESP_HR_FR 259;
BA_ "GenSigTimeoutMsg_Getriebe_AL6000" SG_ 259 ESP_HR_FR 259;
BA_ "GenSigTimeoutMsg_Getriebe_DL5001" SG_ 259 ESP_HR_FR 259;
BA_ "GenSigTimeoutMsg_LWR_B8" SG_ 259 ESP_HR_FR 259;
BA_ "GenSigAutoGenDsp" SG_ 259 ESP_VL_Radgeschw 1;
BA_ "GenSigAutoGenSnd" SG_ 259 ESP_VL_Radgeschw 1;
BA_ "GenSigEnvVarType" SG_ 259 ESP_VL_Radgeschw 1;
BA_ "GenSigSendType" SG_ 259 ESP_VL_Radgeschw 7;
BA_ "GenSigStartValue" SG_ 259 ESP_VL_Radgeschw 4094;
BA_ "NWM-WakeupAllowed" SG_ 259 ESP_VL_Radgeschw 0;
BA_ "NMH-WakeupAllowed" SG_ 259 ESP_VL_Radgeschw 0;
BA_ "GenSigTimeoutMsg_Getriebe_AL6000" SG_ 259 ESP_VL_Radgeschw 259;
BA_ "GenSigTimeoutMsg_Getriebe_DL5001" SG_ 259 ESP_VL_Radgeschw 259;
BA_ "GenSigTimeoutMsg_Getriebe_VL3002" SG_ 259 ESP_VL_Radgeschw 259;
BA_ "GenSigAutoGenDsp" SG_ 259 ESP_VR_Radgeschw 1;
BA_ "GenSigAutoGenSnd" SG_ 259 ESP_VR_Radgeschw 1;
BA_ "GenSigEnvVarType" SG_ 259 ESP_VR_Radgeschw 1;
BA_ "GenSigSendType" SG_ 259 ESP_VR_Radgeschw 7;
BA_ "GenSigStartValue" SG_ 259 ESP_VR_Radgeschw 4094;
BA_ "NWM-WakeupAllowed" SG_ 259 ESP_VR_Radgeschw 0;
BA_ "NMH-WakeupAllowed" SG_ 259 ESP_VR_Radgeschw 0;
BA_ "GenSigTimeoutMsg_Getriebe_AL6000" SG_ 259 ESP_VR_Radgeschw 259;
BA_ "GenSigTimeoutMsg_Getriebe_DL5001" SG_ 259 ESP_VR_Radgeschw 259;
BA_ "GenSigTimeoutMsg_Getriebe_VL3002" SG_ 259 ESP_VR_Radgeschw 259;
BA_ "GenSigAutoGenDsp" SG_ 259 ESP_HL_Radgeschw 1;
BA_ "GenSigAutoGenSnd" SG_ 259 ESP_HL_Radgeschw 1;
BA_ "GenSigEnvVarType" SG_ 259 ESP_HL_Radgeschw 1;
BA_ "GenSigSendType" SG_ 259 ESP_HL_Radgeschw 7;
BA_ "GenSigStartValue" SG_ 259 ESP_HL_Radgeschw 4094;
BA_ "NWM-WakeupAllowed" SG_ 259 ESP_HL_Radgeschw 0;
BA_ "NMH-WakeupAllowed" SG_ 259 ESP_HL_Radgeschw 0;
BA_ "GenSigTimeoutMsg_AFS_B8" SG_ 259 ESP_HL_Radgeschw 259;
BA_ "GenSigTimeoutMsg_Getriebe_AL6000" SG_ 259 ESP_HL_Radgeschw 259;
BA_ "GenSigTimeoutMsg_Getriebe_DL5001" SG_ 259 ESP_HL_Radgeschw 259;
BA_ "GenSigTimeoutMsg_Getriebe_VL3002" SG_ 259 ESP_HL_Radgeschw 259;
BA_ "GenSigTimeoutMsg_LWR_B8" SG_ 259 ESP_HL_Radgeschw 259;
BA_ "GenSigAutoGenDsp" SG_ 259 ESP_HR_Radgeschw 1;
BA_ "GenSigAutoGenSnd" SG_ 259 ESP_HR_Radgeschw 1;
BA_ "GenSigEnvVarType" SG_ 259 ESP_HR_Radgeschw 1;
BA_ "GenSigSendType" SG_ 259 ESP_HR_Radgeschw 7;
BA_ "GenSigStartValue" SG_ 259 ESP_HR_Radgeschw 4094;
BA_ "NWM-WakeupAllowed" SG_ 259 ESP_HR_Radgeschw 0;
BA_ "NMH-WakeupAllowed" SG_ 259 ESP_HR_Radgeschw 0;
BA_ "GenSigTimeoutMsg_AFS_B8" SG_ 259 ESP_HR_Radgeschw 259;
BA_ "GenSigTimeoutMsg_Getriebe_AL6000" SG_ 259 ESP_HR_Radgeschw 259;
BA_ "GenSigTimeoutMsg_Getriebe_DL5001" SG_ 259 ESP_HR_Radgeschw 259;
BA_ "GenSigTimeoutMsg_Getriebe_VL3002" SG_ 259 ESP_HR_Radgeschw 259;
BA_ "GenSigTimeoutMsg_LWR_B8" SG_ 259 ESP_HR_Radgeschw 259;
VAL_ 265 ACC_Sollbeschleunigung 2047 "nicht definiert" ;
VAL_ 265 ACC_neg_Sollbeschl_Grad 255 "nicht definiert" ;
VAL_ 265 ACC_pos_Sollbeschl_Grad 255 "nicht definiert" ;
VAL_ 265 ACC_KD_Fehler 1 "eingetragen" 0 "nicht eingetragen" ;
VAL_ 265 ACC_Anhalten 1 "Anhalten gewuenscht" 0 "kein Anhalten gewuenscht" ;
VAL_ 265 ACC_Dynamik 2 "standard" 0 "Init" 3 "comfort" 1 "dynamic" ;
VAL_ 265 ACC_Status_ACC 0 "ACC OFF (ACC-Hauptschalter aus)" 2 "ACC STANDBY" 4 "ACC OVERRIDE" 1 "ACC INIT" 7 "irreversibler Fehler ACC-System" 5 "nicht definiert" 6 "reversibler Fehler ACC-System" 3 "ACC AKTIV (regelt)" ;
VAL_ 265 ACC_Minimale_Bremsung 0 "Anforderung Minimale Bremsung nicht aktiv" 1 "Anforderung Minimale Bremsung aktiv" ;
VAL_ 64 AB_Front_Crash 1 "Front-Crash" 0 "kein Front-Crash" ;
VAL_ 64 AB_Heck_Crash 1 "Heck-Crash" 0 "kein Heck-Crash" ;
VAL_ 64 AB_SF_Crash 0 "kein Seiten Crash Fahrer" 1 "Seiten-Crash Fahrer" ;
VAL_ 64 AB_SB_Crash 0 "kein Seiten Crash Beifahrer" 1 "Seiten Crash Beifahrer" ;
VAL_ 64 AB_Rollover_Crash 0 "kein Rollover" 1 "Rollover" ;
VAL_ 64 AB_Crash_Int 4 "RdW-Schwelle ueberschritten" 2 "US-Schwelle ueberschritten" 1 "Gurtstrafferschwelle ueberschritten" 7 "RdW-Schwelle überschritten bei Bosch-Airbag" ;
VAL_ 64 AB_Lampe 0 "Aus" 1 "Ein" ;
VAL_ 64 AB_Deaktiviert 0 "aktiv" 1 "deaktiviert" ;
VAL_ 64 AB_VB_deaktiviert 1 "Beifahrerairbag deaktiviert" 0 "Beifahrerairbag aktiv" ;
VAL_ 64 AB_Systemfehler 0 "kein Fehler" 1 "Systemfehler" ;
VAL_ 64 AB_Diagnose 1 "in Diagnose" 0 "nicht in Diagnose" ;
VAL_ 64 AB_Stellgliedtest 0 "nicht im Stellgliedtest" 1 "im Stellgliedtest" ;
VAL_ 64 AB_Erh_Auf_VB 2 "Beifahrerairbag aktiviert" 1 "Beifahrerairbag deaktiviert" 3 "nicht benutzt" 0 "keine Anzeige" ;
VAL_ 64 AB_Gurtwarn_VF 1 "Gurtwarnung ausloesen" 0 "keine Warnung" ;
VAL_ 64 AB_Gurtwarn_VB 1 "Gurtwarnung ausloesen" 0 "keine Warnung" ;
VAL_ 64 AB_Anzeige_Fussg 0 "keine Anzeige" 2 "Systemfehler" 1 "Motorhaube offen" ;
VAL_ 64 AB_KD_Fehler 1 "eingetragen" 0 "nicht eingetragen" ;
VAL_ 1312 AB_Belegung_VB 0 "nicht verfuegbar" 3 "belegt" 2 "nicht belegt" 1 "Fehler" ;
VAL_ 1633 AAG_Bremsl_durch_ECD 0 "Bremslicht ist aus" 1 "Bremslicht durch ECD aktiv" ;
VAL_ 1633 AAG_Anhaenger_abgesteckt 1 "Anhaenger wurde bei Kl. 15 aus abgesteckt" ;
VAL_ 1633 AAG_NSL_aktiv 1 "Anhaenger Nebelschlusslicht aktiv" ;
VAL_ 1633 AAG_Anhaenger_erkannt 1 "Anhaenger erkannt" ;
VAL_ 1633 AAG_Blinker_H_aktiv 1 "Anhaenger Blinker aktiv" ;
VAL_ 1633 AAG_Blinker_HL_def 1 "Anhaenger Blinker links defekt" ;
VAL_ 1633 AAG_Blinker_HR_def 1 "Anhaenger Blinker rechts defekt" ;
VAL_ 1633 AAG_Bremslicht_H_def 1 "Anhaenger Bremslicht defekt" ;
VAL_ 1633 AAG_Schlusslicht_HL_def 1 "Anhaenger Schlußlicht links defekt" ;
VAL_ 1633 AAG_Schlusslicht_HR_def 1 "Anhaenger Schlußlicht rechts defekt" ;
VAL_ 1633 AAG_KD_Fehler 1 "mindestens ein Kundendienstfehlerspeicher Eintrag vorhanden" ;
VAL_ 1633 AAG_AVS_Fehler 2 "n.i.O. + Fahrzeugstopp erforderlich" 3 "t.b.d." 0 "i.O." 1 "n.i.O." ;
VAL_ 1633 AAG_AVS_Stati 1 "endlage ausgefahren erreicht" 3 "einfahren automatik" 2 "ausfahren automatik " 5 "einfahren manuell" 6 "zwischenposition" 7 "nicht initialisiert" 0 "endlage eingefahren erreicht" 4 "ausfahren manuell " ;
VAL_ 777 BEM_P_Generator 255 "Fehler" ;
VAL_ 777 BEM_n_LLA 2 "Stufe 2" 1 "Stufe 1" 0 "keine Erhoehung" 3 "nicht definiert" ;
VAL_ 777 BEM_01_Abschaltstufen 0 "Stufe 0 (keine Einschränkungen)" 1 "Stufe 1" 2 "Stufe 2" 3 "Stufe 3" 7 "Ruhestrommessmodus" 4 "Transportmodus" ;
VAL_ 777 BEM_Anf_KL 1 "Anforderung Kühlerlüfter Ansteuerung" 0 "keine Anforderung" ;
VAL_ 867 BM_ZV_auf 1 "Blinken bei ZV auf aktiv " 0 "Blinken bei ZV auf nicht aktiv " ;
VAL_ 867 BM_ZV_zu 1 "Blinken bei ZV zu aktiv " 0 "Blinken bei ZV zu nicht aktiv " ;
VAL_ 867 BM_DWA_ein 1 "Quittierungsblinken DWA aktiv " 0 "Quittierungsblinken DWA nicht aktiv " ;
VAL_ 867 BM_DWA_Alarm 1 "DWA-Alarmblinken aktiv " 0 "DWA-Alarmblinken nicht aktiv " ;
VAL_ 867 BM_Crash 1 "Crashblinken aktiv " 0 "Crashblinken nicht aktiv " ;
VAL_ 867 BM_Panik 0 "Panikblinken nicht aktiv " 1 "Panikblinken aktiv " ;
VAL_ 867 BM_Not_Bremsung 0 "Notbremsblinken nicht aktiv " 1 "Notbremsblinken aktiv " ;
VAL_ 867 BM_GDO 1 "Blinken bei UGDO anlernen aktiv " 0 "Blinken bei UGDO anlernen nicht aktiv " ;
VAL_ 867 BM_links 1 "Richtungsblinken links aktiv " 0 "Richtungsblinken links nicht aktiv " ;
VAL_ 867 BM_rechts 1 "Richtungsblinken rechts aktiv " 0 "Richtungsblinken rechts nicht aktiv " ;
VAL_ 867 BM_Warnblinken 0 "Warnblinken nicht aktiv " 1 "Warnblinken aktiv " ;
VAL_ 867 BM_Autobahn 0 "Autobahnblinken nicht aktiv " 1 "Autobahnblinken aktiv " ;
VAL_ 867 BM_Taxi_Notalarm 1 "Blinken bei Taxi-Not-Alarm aktiv " 0 "Blinken bei Taxi-Not-Alarm nicht aktiv " ;
VAL_ 867 BM_Telematik 1 "Telematikblinken aktiv " 0 "Telematikblinken nicht aktiv " ;
VAL_ 867 BM_WBT_Beleuchtung 1 "Warnblinktasterfunktionsbeleuchtung soll aktiviert werden (statisch auf 1)" ;
VAL_ 867 Blinken_li_Fzg_Takt 1 "Blinker links eingeschaltet" 0 "Blinker links ausgeschaltet" ;
VAL_ 867 Blinken_re_Fzg_Takt 0 "Blinker rechts ausgeschaltet" 1 "Blinker rechts eingeschaltet" ;
VAL_ 867 Blinken_li_Kombi_Takt 1 "Blinkerkontrolllampe links eingeschaltet" 0 "Blinkerkontrolllampe links ausgeschaltet" ;
VAL_ 867 Blinken_re_Kombi_Takt 0 "Blinkerkontrolllampe rechts ausgeschaltet" 1 "Blinkerkontrolllampe rechts eingeschaltet" ;
VAL_ 867 Blinken_FWB_aktiv 1 "freilaufendes Warnblinken aktiv" 0 "freilaufendes Warnblinken nicht aktiv" ;
VAL_ 901 CHA_Systemstatus 1 "Status nicht in Ordnung" 3 "reserviert" 0 "Status in Ordnung" 2 "reserviert" ;
VAL_ 901 CHA_Ziel_FahrPr_MO 5 "nicht belegt" 0 "nicht belegt" 2 "Dynamik" 7 "nicht belegt" 3 "Sport" 4 "nicht belegt" 6 "nicht belegt" 1 "Komfort" ;
VAL_ 901 CHA_Ziel_FahrPr_GE 4 "nicht belegt" 0 "nicht belegt" 5 "nicht belegt" 1 "Komfort" 6 "nicht belegt" 7 "nicht belegt" 2 "Dynamik" 3 "Sport" ;
VAL_ 901 CHA_Ziel_FahrPr_ST 4 "nicht belegt" 5 "nicht belegt" 0 "nicht belegt" 2 "Dynamik" 3 "Sport" 6 "nicht belegt" 1 "Komfort" 7 "nicht belegt" ;
VAL_ 901 CHA_Ziel_FahrPr_SCU 3 "Sport" 4 "nicht belegt" 5 "nicht belegt" 1 "Komfort" 2 "Dynamik" 7 "nicht belegt" 6 "nicht belegt" 0 "nicht belegt" ;
VAL_ 901 CHA_Ziel_FahrPr_DR 6 "nicht belegt" 5 "nicht belegt" 7 "nicht belegt" 2 "Dynamik" 3 "Sport" 4 "nicht belegt" 0 "nicht belegt" 1 "Komfort" ;
VAL_ 901 CHA_Ziel_FahrPr_QS 3 "Sport" 1 "Komfort" 5 "nicht belegt" 2 "Dynamik" 4 "nicht belegt" 6 "nicht belegt" 7 "nicht belegt" 0 "nicht belegt" ;
VAL_ 901 CHA_Ziel_FahrPr_Sys_7 4 "nicht belegt" 3 "Sport" 1 "Komfort" 2 "Dynamik" 7 "nicht belegt" 6 "nicht belegt" 0 "nicht belegt" 5 "nicht belegt" ;
VAL_ 901 CHA_Ziel_FahrPr_Sys_8 7 "nicht belegt" 1 "Komfort" 4 "nicht belegt" 6 "nicht belegt" 3 "Sport" 0 "nicht belegt" 5 "nicht belegt" 2 "Dynamik" ;
VAL_ 918 DR_Systemstatus 3 "Sport 1" 4 "Sport 2" 7 "Notfahrfunktion" 5 "nicht funktionsfähig" 2 "Normal" 0 "Init oder kein Wert verfuegbar" 1 "Komfortabel" 6 "nicht definiert" ;
VAL_ 918 DR_Taster 0 "Taster nicht gedrückt" 1 "Taster gedrückt" ;
VAL_ 918 DR_Gelbe_Warnlampe 0 "Warnlampe aus" 1 "Warnlampe ein (Aufprüfen)" 2 "Warnlampe an (Warnung)" 3 "reserviert" ;
VAL_ 918 DR_Daempferreg_Texte 15 "Text15 'Verlademodus" 3 "Text3 'Dämpfer Comfort'" 2 "Text2 'Dämpfer Basis'" 1 "Text1  'Dämpfer Sport'" 0 "kein Text" ;
VAL_ 918 DR_KD_Fehler 1 "eingetragen" 0 "nicht eingetragen" ;
VAL_ 1714 DGN_Verlernzaehler 255 "ungültiger Zählerstand oder kein gültiger Fahrzyklus" ;
VAL_ 1714 KBI_Kilometerstand 1048574 "Init" 1048575 "Fehler" ;
VAL_ 1714 UH_Monat 0 "Fehler" ;
VAL_ 1714 UH_Tag 0 "Fehler" ;
VAL_ 1520 DI_KL_58d 254 "Init" 255 "Fehler" ;
VAL_ 1520 DI_KL_58s 127 "Fehler" ;
VAL_ 1520 DI_KL_58st 126 "Init" 127 "Fehler" ;
VAL_ 260 EPB_QBit_Laengsbeschleunigung 1 "Ersatz-, Init- oder Fehlerwert" 0 "gültiger Wert" ;
VAL_ 260 EPB_QBit_Pedalweg_Kuppl 1 "Ersatz-, Init- oder Fehlerwert" 0 "gültiger Wert" ;
VAL_ 260 EPB_BCM2_Motor_Wakeup 1 "Anforderung an BCM2 Wakeupleitung zum Motor hochzuziehen aufgrund von Car-Wakeup" 0 "keine Anforderung" ;
VAL_ 260 EPB_Freig_Verzoeg_Anf 0 "nicht freigegeben" 1 "freigegeben" ;
VAL_ 260 EPB_Laengsbeschleunigung 255 "Fehler" ;
VAL_ 260 EPB_Pedalweg_Kuppl 0 "Init" 255 "Fehler" ;
VAL_ 260 EPB_Fehlerstatus 2 "tbd." 1 "tbd." 3 "Fehler in EPB - AVH darf von ESP nicht ausgeführt werden" 0 "kein Fehler in EPB - AVH darf von ESP ausgeführt werden" ;
VAL_ 260 EPB_Schalterposition 2 "Fahreranforderung Schließen" 0 "keine Fahreranforderung" 1 "Fahreranforderung Öffnen" 3 "Fehler" ;
VAL_ 260 EPB_QBit_Schalterpos 1 " Ersatz-, Init- oder Fehlerwert (Schalter ausser Funktion)" 0 "gültiger Wert (volle Funktion)" ;
VAL_ 260 EPB_Spannkraft 30 "Init" 31 "Fehler" ;
VAL_ 260 EPB_Status 2 "Aktuator im Lauf" 0 "Bremse geöffnet" 1 "Bremse geschlossen" ;
VAL_ 260 EPB_KD_Fehler 1 "eingetragen" 0 "nicht eingetragen" ;
VAL_ 256 ASR_Moment_langsam 1022 "Init" 1023 "Fehler" ;
VAL_ 256 ASR_MSR_Moment_schnell 1022 "Init" 1023 "Fehler" ;
VAL_ 256 ESP_v_Signal 65534 "Init" 65533 "Unterspannung" 65535 "Fehler" ;
VAL_ 256 ASR_Tastung_passiv 1 "ASR passiv getastet" 0 "ASR aktiviert" ;
VAL_ 256 ESP_Tastung_passiv 1 "ESP passiv getastet" 0 "ESP aktiviert" ;
VAL_ 256 ESP_Systemstatus 0 "iO" 1 "Fehler" ;
VAL_ 256 ASR_Schalteingriff 0 "keine Anforderung" 3 "Schaltverbot" 2 "Rückschaltung" 1 "ASR-Schaltkennfeld" ;
VAL_ 256 OBD_Schlechtweg 1 "Schlechtweg erkannt" 0 "kein Schlechtweg erkannt" ;
VAL_ 256 OBD_QBit_Schlechtweg 0 "gültiger Wert" 1 "Ersatz-, Init- oder Fehlerwert" ;
VAL_ 256 ESP_QBit_v_Signal 0 "gültiger Wert" 1 "Ersatz-, Init- oder Fehlerwert" ;
VAL_ 256 ABS_Bremsung 1 "ABS-Regelung" 0 "keine ABS-Regelung" ;
VAL_ 256 ASR_Anf 1 "ASR-Anforderung" 0 "keine Anforderung" ;
VAL_ 256 MSR_Anf 0 "keine Anfoderung" 1 "MSR-Anforderung" ;
VAL_ 256 EBV_Eingriff 0 "kein EBV-Eingriff" 1 "EBV-Eingriff" ;
VAL_ 256 EDS_Eingriff 1 "EDS-Eingriff" 0 "kein EDS-Eingriff" ;
VAL_ 256 ESP_Eingriff 1 "ESP-Eingriff" 0 "kein ESP-Eingriff" ;
VAL_ 256 ESP_ASP 1 "ASP aktiv" 0 "ASP inaktiv" ;
VAL_ 256 ESP_KD_Fehler 1 "eingetragen" 0 "nicht eingetragen" ;
VAL_ 257 ESP_QBit_Gierrate 0 "gültiger Wert" 1 "Ersatz-, Init- oder Fehlerwert" ;
VAL_ 257 ESP_QBit_Laengsbeschl 0 "gültiger Wert" 1 "Ersatz-, Init- oder Fehlerwert" ;
VAL_ 257 ESP_QBit_Querb 0 "gültiger Wert" 1 "Ersatz-, Init- oder Fehlerwert" ;
VAL_ 257 ESP_Stillstandsflag 0 "kein Stillstand erkannt" 1 "Stillstand erkannt" ;
VAL_ 257 ESP_Querbeschleunigung 255 "Fehler" ;
VAL_ 257 ESP_Laengsbeschl 1022 "Signal nicht vorhanden" 1023 "Fehler" ;
VAL_ 257 ESP_Verteil_Wankmom 30 "Init" 31 "Fehler" ;
VAL_ 257 ESP_QBit_Anf_Vert_Wank 0 "gültiger Wert" 1 "Ersatz-, Init- oder Fehlerwert" ;
VAL_ 257 ESP_Gierrate 16383 "Fehler" ;
VAL_ 257 ESP_VZ_Gierrate 0 "positiv" 1 "negativ" ;
VAL_ 257 ESP_Notbremsanzeige 0 "keine Notbremsung erkannt" 1 "Notbremsung erkannt" ;
VAL_ 259 ESP_VL_FR 0 "Vorwärts" 1 "Rückwärts" ;
VAL_ 259 ESP_VR_FR 0 "Vorwärts" 1 "Rückwärts" ;
VAL_ 259 ESP_HL_FR 0 "Vorwaerts" 1 "Rueckwaerts" ;
VAL_ 259 ESP_HR_FR 1 "Rueckwaerts" 0 "Vorwaerts" ;
VAL_ 259 ESP_VL_Radgeschw 4093 "Unterspannung" 4094 "Init" 4095 "Fehler" ;
VAL_ 259 ESP_VR_Radgeschw 4094 "Init" 4093 "Unterspannung" 4095 "Fehler" ;
VAL_ 259 ESP_HL_Radgeschw 4094 "Init" 4093 "Unterspannung" 4095 "Fehler" ;
VAL_ 259 ESP_HR_Radgeschw 4094 "Init" 4093 "Unterspannung" 4095 "Fehler" ;
